VERSION "BodyCANhs"

NS_ :

BS_:

BU_: CCM CEM DDM ETC PAM PDM POT PSMD PSMP TRM VCM Y20CCMV526M1 Vector_XXX

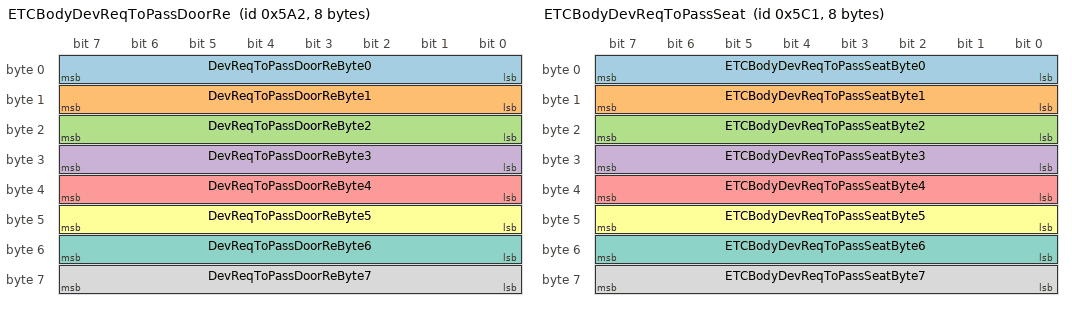
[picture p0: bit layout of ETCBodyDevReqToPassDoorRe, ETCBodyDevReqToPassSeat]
BO_ 1442 ETCBodyDevReqToPassDoorRe: 8 ETC
 SG_ DevReqToPassDoorReByte0 : 7|8@0+ (1,0) [0|255] ""  PDM
 SG_ DevReqToPassDoorReByte1 : 15|8@0+ (1,0) [0|255] ""  PDM
 SG_ DevReqToPassDoorReByte2 : 23|8@0+ (1,0) [0|255] ""  PDM
 SG_ DevReqToPassDoorReByte3 : 31|8@0+ (1,0) [0|255] ""  PDM
 SG_ DevReqToPassDoorReByte4 : 39|8@0+ (1,0) [0|255] ""  PDM
 SG_ DevReqToPassDoorReByte5 : 47|8@0+ (1,0) [0|255] ""  PDM
 SG_ DevReqToPassDoorReByte6 : 55|8@0+ (1,0) [0|255] ""  PDM
 SG_ DevReqToPassDoorReByte7 : 63|8@0+ (1,0) [0|255] ""  PDM

BO_ 1473 ETCBodyDevReqToPassSeat: 8 ETC
 SG_ ETCBodyDevReqToPassSeatByte0 : 7|8@0+ (1,0) [0|255] ""  PSMP
 SG_ ETCBodyDevReqToPassSeatByte1 : 15|8@0+ (1,0) [0|255] ""  PSMP
 SG_ ETCBodyDevReqToPassSeatByte2 : 23|8@0+ (1,0) [0|255] ""  PSMP
 SG_ ETCBodyDevReqToPassSeatByte3 : 31|8@0+ (1,0) [0|255] ""  PSMP
 SG_ ETCBodyDevReqToPassSeatByte4 : 39|8@0+ (1,0) [0|255] ""  PSMP
 SG_ ETCBodyDevReqToPassSeatByte5 : 47|8@0+ (1,0) [0|255] ""  PSMP
 SG_ ETCBodyDevReqToPassSeatByte6 : 55|8@0+ (1,0) [0|255] ""  PSMP
 SG_ ETCBodyDevReqToPassSeatByte7 : 63|8@0+ (1,0) [0|255] ""  PSMP

BO_ 1405 EtcMstCfgIDBodyFr01: 8 ETC
 SG_ IniValMstCfgIDBodyCAN : 7|16@0+ (1,0) [0|65535] ""  CEM

BO_ 1406 EtcSigCfgIDBodyFr01: 8 ETC
 SG_ IniValSigCfgIDBodyCAN : 7|16@0+ (1,0) [0|65535] ""  CCM,DDM,PDM,POT,PSMD,PSMP,TRM,VCM

BO_ 1520 ETCtoCCMXCPFr01: 8 ETC

BO_ 1521 ETCtoCEMXCPFr01: 8 ETC

BO_ 1522 ETCtoDDMXCPFr01: 8 ETC

BO_ 1523 ETCtoPDMXCPFr01: 8 ETC

BO_ 1467 ETCtoPOTXCPFr01: 8 ETC

BO_ 1465 ETCtoTRMXcpFr01: 8 ETC

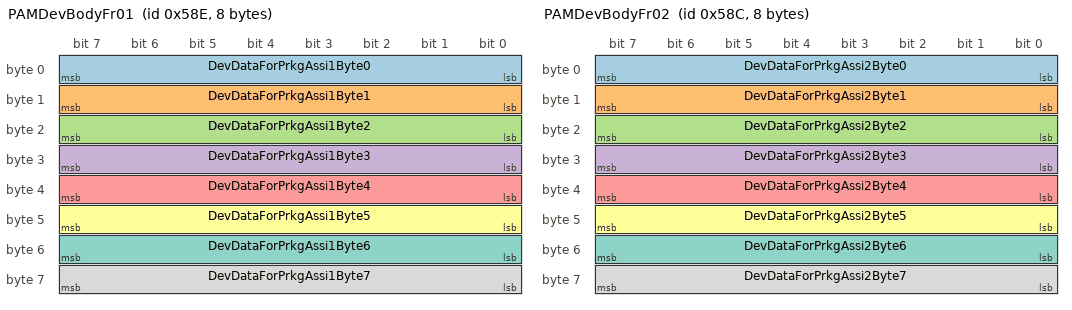
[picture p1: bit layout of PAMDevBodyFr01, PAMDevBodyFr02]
BO_ 1422 PAMDevBodyFr01: 8 PAM
 SG_ DevDataForPrkgAssi1Byte0 : 7|8@0+ (1,0) [0|255] ""  ETC
 SG_ DevDataForPrkgAssi1Byte1 : 15|8@0+ (1,0) [0|255] ""  ETC
 SG_ DevDataForPrkgAssi1Byte2 : 23|8@0+ (1,0) [0|255] ""  ETC
 SG_ DevDataForPrkgAssi1Byte3 : 31|8@0+ (1,0) [0|255] ""  ETC
 SG_ DevDataForPrkgAssi1Byte4 : 39|8@0+ (1,0) [0|255] ""  ETC
 SG_ DevDataForPrkgAssi1Byte5 : 47|8@0+ (1,0) [0|255] ""  ETC
 SG_ DevDataForPrkgAssi1Byte6 : 55|8@0+ (1,0) [0|255] ""  ETC
 SG_ DevDataForPrkgAssi1Byte7 : 63|8@0+ (1,0) [0|255] ""  ETC

BO_ 1420 PAMDevBodyFr02: 8 PAM
 SG_ DevDataForPrkgAssi2Byte0 : 7|8@0+ (1,0) [0|255] ""  ETC
 SG_ DevDataForPrkgAssi2Byte1 : 15|8@0+ (1,0) [0|255] ""  ETC
 SG_ DevDataForPrkgAssi2Byte2 : 23|8@0+ (1,0) [0|255] ""  ETC
 SG_ DevDataForPrkgAssi2Byte3 : 31|8@0+ (1,0) [0|255] ""  ETC
 SG_ DevDataForPrkgAssi2Byte4 : 39|8@0+ (1,0) [0|255] ""  ETC
 SG_ DevDataForPrkgAssi2Byte5 : 47|8@0+ (1,0) [0|255] ""  ETC
 SG_ DevDataForPrkgAssi2Byte6 : 55|8@0+ (1,0) [0|255] ""  ETC
 SG_ DevDataForPrkgAssi2Byte7 : 63|8@0+ (1,0) [0|255] ""  ETC

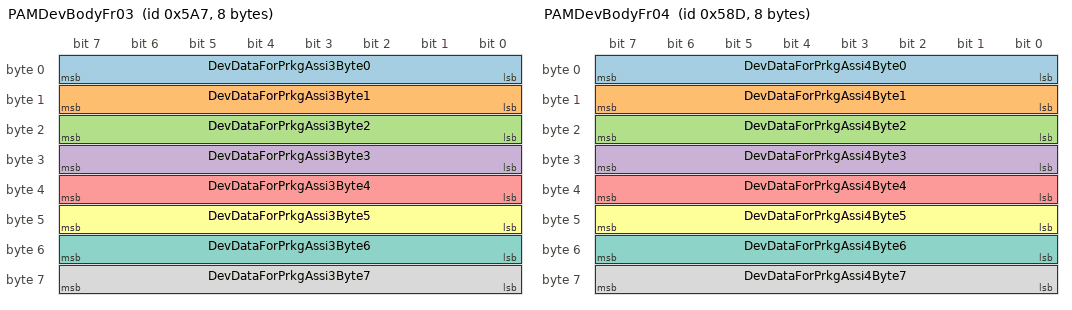
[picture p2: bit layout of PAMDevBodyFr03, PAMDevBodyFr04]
BO_ 1447 PAMDevBodyFr03: 8 PAM
 SG_ DevDataForPrkgAssi3Byte0 : 7|8@0+ (1,0) [0|255] ""  ETC
 SG_ DevDataForPrkgAssi3Byte1 : 15|8@0+ (1,0) [0|255] ""  ETC
 SG_ DevDataForPrkgAssi3Byte2 : 23|8@0+ (1,0) [0|255] ""  ETC
 SG_ DevDataForPrkgAssi3Byte3 : 31|8@0+ (1,0) [0|255] ""  ETC
 SG_ DevDataForPrkgAssi3Byte4 : 39|8@0+ (1,0) [0|255] ""  ETC
 SG_ DevDataForPrkgAssi3Byte5 : 47|8@0+ (1,0) [0|255] ""  ETC
 SG_ DevDataForPrkgAssi3Byte6 : 55|8@0+ (1,0) [0|255] ""  ETC
 SG_ DevDataForPrkgAssi3Byte7 : 63|8@0+ (1,0) [0|255] ""  ETC

BO_ 1421 PAMDevBodyFr04: 8 PAM
 SG_ DevDataForPrkgAssi4Byte0 : 7|8@0+ (1,0) [0|255] ""  ETC
 SG_ DevDataForPrkgAssi4Byte1 : 15|8@0+ (1,0) [0|255] ""  ETC
 SG_ DevDataForPrkgAssi4Byte2 : 23|8@0+ (1,0) [0|255] ""  ETC
 SG_ DevDataForPrkgAssi4Byte3 : 31|8@0+ (1,0) [0|255] ""  ETC
 SG_ DevDataForPrkgAssi4Byte4 : 39|8@0+ (1,0) [0|255] ""  ETC
 SG_ DevDataForPrkgAssi4Byte5 : 47|8@0+ (1,0) [0|255] ""  ETC
 SG_ DevDataForPrkgAssi4Byte6 : 55|8@0+ (1,0) [0|255] ""  ETC
 SG_ DevDataForPrkgAssi4Byte7 : 63|8@0+ (1,0) [0|255] ""  ETC

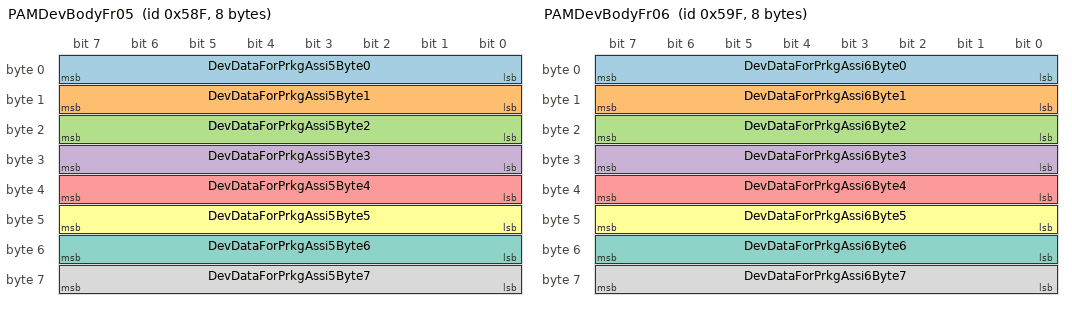
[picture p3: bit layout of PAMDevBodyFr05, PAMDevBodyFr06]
BO_ 1423 PAMDevBodyFr05: 8 PAM
 SG_ DevDataForPrkgAssi5Byte0 : 7|8@0+ (1,0) [0|255] ""  ETC
 SG_ DevDataForPrkgAssi5Byte1 : 15|8@0+ (1,0) [0|255] ""  ETC
 SG_ DevDataForPrkgAssi5Byte2 : 23|8@0+ (1,0) [0|255] ""  ETC
 SG_ DevDataForPrkgAssi5Byte3 : 31|8@0+ (1,0) [0|255] ""  ETC
 SG_ DevDataForPrkgAssi5Byte4 : 39|8@0+ (1,0) [0|255] ""  ETC
 SG_ DevDataForPrkgAssi5Byte5 : 47|8@0+ (1,0) [0|255] ""  ETC
 SG_ DevDataForPrkgAssi5Byte6 : 55|8@0+ (1,0) [0|255] ""  ETC
 SG_ DevDataForPrkgAssi5Byte7 : 63|8@0+ (1,0) [0|255] ""  ETC

BO_ 1439 PAMDevBodyFr06: 8 PAM
 SG_ DevDataForPrkgAssi6Byte0 : 7|8@0+ (1,0) [0|255] ""  ETC
 SG_ DevDataForPrkgAssi6Byte1 : 15|8@0+ (1,0) [0|255] ""  ETC
 SG_ DevDataForPrkgAssi6Byte2 : 23|8@0+ (1,0) [0|255] ""  ETC
 SG_ DevDataForPrkgAssi6Byte3 : 31|8@0+ (1,0) [0|255] ""  ETC
 SG_ DevDataForPrkgAssi6Byte4 : 39|8@0+ (1,0) [0|255] ""  ETC
 SG_ DevDataForPrkgAssi6Byte5 : 47|8@0+ (1,0) [0|255] ""  ETC
 SG_ DevDataForPrkgAssi6Byte6 : 55|8@0+ (1,0) [0|255] ""  ETC
 SG_ DevDataForPrkgAssi6Byte7 : 63|8@0+ (1,0) [0|255] ""  ETC

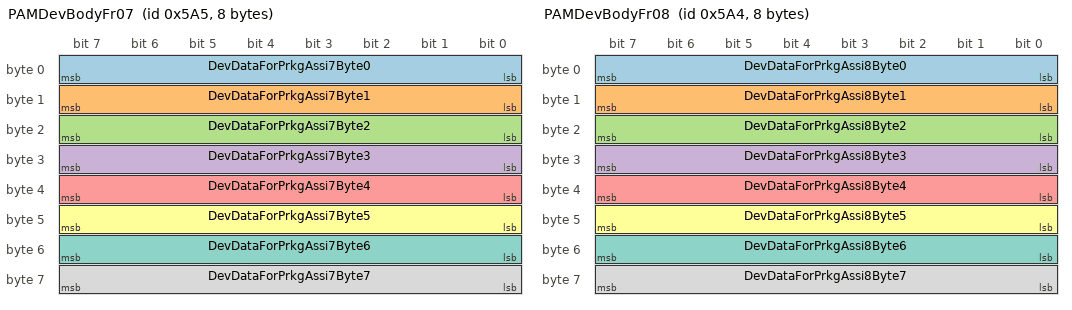
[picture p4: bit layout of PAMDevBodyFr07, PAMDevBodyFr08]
BO_ 1445 PAMDevBodyFr07: 8 PAM
 SG_ DevDataForPrkgAssi7Byte0 : 7|8@0+ (1,0) [0|255] ""  ETC
 SG_ DevDataForPrkgAssi7Byte1 : 15|8@0+ (1,0) [0|255] ""  ETC
 SG_ DevDataForPrkgAssi7Byte2 : 23|8@0+ (1,0) [0|255] ""  ETC
 SG_ DevDataForPrkgAssi7Byte3 : 31|8@0+ (1,0) [0|255] ""  ETC
 SG_ DevDataForPrkgAssi7Byte4 : 39|8@0+ (1,0) [0|255] ""  ETC
 SG_ DevDataForPrkgAssi7Byte5 : 47|8@0+ (1,0) [0|255] ""  ETC
 SG_ DevDataForPrkgAssi7Byte6 : 55|8@0+ (1,0) [0|255] ""  ETC
 SG_ DevDataForPrkgAssi7Byte7 : 63|8@0+ (1,0) [0|255] ""  ETC

BO_ 1444 PAMDevBodyFr08: 8 PAM
 SG_ DevDataForPrkgAssi8Byte0 : 7|8@0+ (1,0) [0|255] ""  ETC
 SG_ DevDataForPrkgAssi8Byte1 : 15|8@0+ (1,0) [0|255] ""  ETC
 SG_ DevDataForPrkgAssi8Byte2 : 23|8@0+ (1,0) [0|255] ""  ETC
 SG_ DevDataForPrkgAssi8Byte3 : 31|8@0+ (1,0) [0|255] ""  ETC
 SG_ DevDataForPrkgAssi8Byte4 : 39|8@0+ (1,0) [0|255] ""  ETC
 SG_ DevDataForPrkgAssi8Byte5 : 47|8@0+ (1,0) [0|255] ""  ETC
 SG_ DevDataForPrkgAssi8Byte6 : 55|8@0+ (1,0) [0|255] ""  ETC
 SG_ DevDataForPrkgAssi8Byte7 : 63|8@0+ (1,0) [0|255] ""  ETC

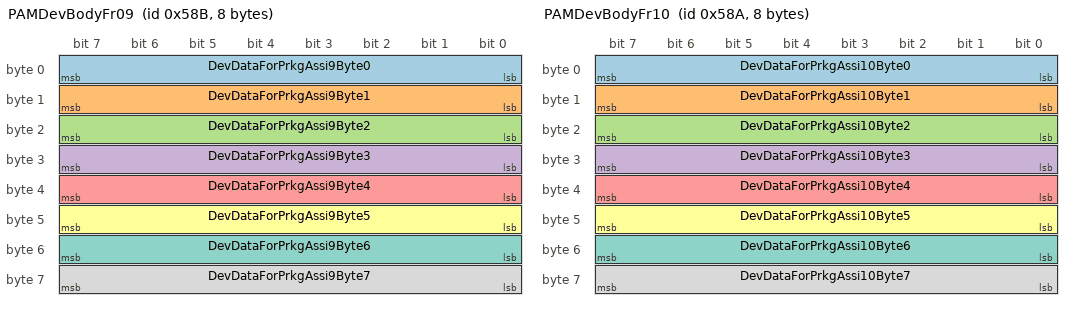
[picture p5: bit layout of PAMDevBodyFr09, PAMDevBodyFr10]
BO_ 1419 PAMDevBodyFr09: 8 PAM
 SG_ DevDataForPrkgAssi9Byte0 : 7|8@0+ (1,0) [0|255] ""  ETC
 SG_ DevDataForPrkgAssi9Byte1 : 15|8@0+ (1,0) [0|255] ""  ETC
 SG_ DevDataForPrkgAssi9Byte2 : 23|8@0+ (1,0) [0|255] ""  ETC
 SG_ DevDataForPrkgAssi9Byte3 : 31|8@0+ (1,0) [0|255] ""  ETC
 SG_ DevDataForPrkgAssi9Byte4 : 39|8@0+ (1,0) [0|255] ""  ETC
 SG_ DevDataForPrkgAssi9Byte5 : 47|8@0+ (1,0) [0|255] ""  ETC
 SG_ DevDataForPrkgAssi9Byte6 : 55|8@0+ (1,0) [0|255] ""  ETC
 SG_ DevDataForPrkgAssi9Byte7 : 63|8@0+ (1,0) [0|255] ""  ETC

BO_ 1418 PAMDevBodyFr10: 8 PAM
 SG_ DevDataForPrkgAssi10Byte0 : 7|8@0+ (1,0) [0|255] ""  ETC
 SG_ DevDataForPrkgAssi10Byte1 : 15|8@0+ (1,0) [0|255] ""  ETC
 SG_ DevDataForPrkgAssi10Byte2 : 23|8@0+ (1,0) [0|255] ""  ETC
 SG_ DevDataForPrkgAssi10Byte3 : 31|8@0+ (1,0) [0|255] ""  ETC
 SG_ DevDataForPrkgAssi10Byte4 : 39|8@0+ (1,0) [0|255] ""  ETC
 SG_ DevDataForPrkgAssi10Byte5 : 47|8@0+ (1,0) [0|255] ""  ETC
 SG_ DevDataForPrkgAssi10Byte6 : 55|8@0+ (1,0) [0|255] ""  ETC
 SG_ DevDataForPrkgAssi10Byte7 : 63|8@0+ (1,0) [0|255] ""  ETC

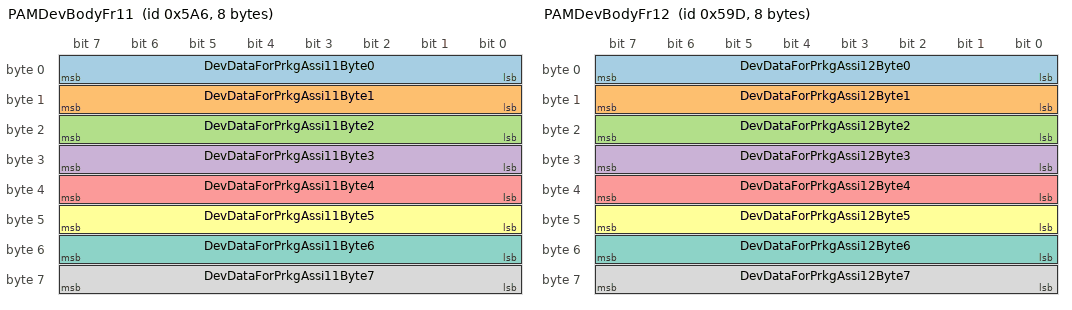
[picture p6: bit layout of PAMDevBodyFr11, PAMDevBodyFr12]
BO_ 1446 PAMDevBodyFr11: 8 PAM
 SG_ DevDataForPrkgAssi11Byte0 : 7|8@0+ (1,0) [0|255] ""  ETC
 SG_ DevDataForPrkgAssi11Byte1 : 15|8@0+ (1,0) [0|255] ""  ETC
 SG_ DevDataForPrkgAssi11Byte2 : 23|8@0+ (1,0) [0|255] ""  ETC
 SG_ DevDataForPrkgAssi11Byte3 : 31|8@0+ (1,0) [0|255] ""  ETC
 SG_ DevDataForPrkgAssi11Byte4 : 39|8@0+ (1,0) [0|255] ""  ETC
 SG_ DevDataForPrkgAssi11Byte5 : 47|8@0+ (1,0) [0|255] ""  ETC
 SG_ DevDataForPrkgAssi11Byte6 : 55|8@0+ (1,0) [0|255] ""  ETC
 SG_ DevDataForPrkgAssi11Byte7 : 63|8@0+ (1,0) [0|255] ""  ETC

BO_ 1437 PAMDevBodyFr12: 8 PAM
 SG_ DevDataForPrkgAssi12Byte0 : 7|8@0+ (1,0) [0|255] ""  ETC
 SG_ DevDataForPrkgAssi12Byte1 : 15|8@0+ (1,0) [0|255] ""  ETC
 SG_ DevDataForPrkgAssi12Byte2 : 23|8@0+ (1,0) [0|255] ""  ETC
 SG_ DevDataForPrkgAssi12Byte3 : 31|8@0+ (1,0) [0|255] ""  ETC
 SG_ DevDataForPrkgAssi12Byte4 : 39|8@0+ (1,0) [0|255] ""  ETC
 SG_ DevDataForPrkgAssi12Byte5 : 47|8@0+ (1,0) [0|255] ""  ETC
 SG_ DevDataForPrkgAssi12Byte6 : 55|8@0+ (1,0) [0|255] ""  ETC
 SG_ DevDataForPrkgAssi12Byte7 : 63|8@0+ (1,0) [0|255] ""  ETC

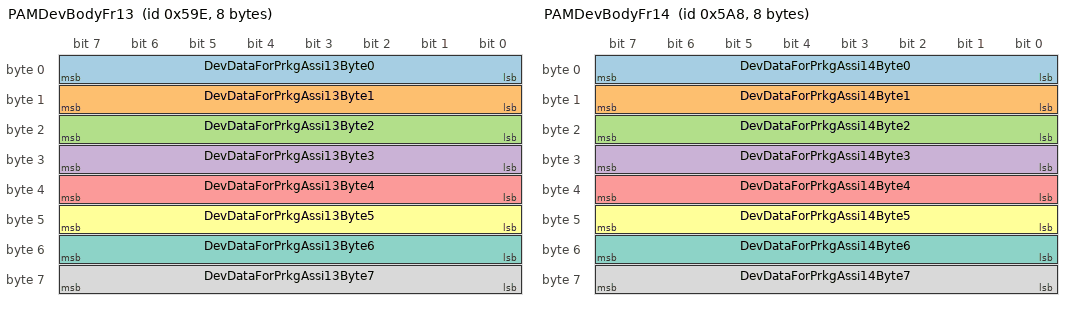
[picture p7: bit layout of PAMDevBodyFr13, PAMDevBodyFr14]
BO_ 1438 PAMDevBodyFr13: 8 PAM
 SG_ DevDataForPrkgAssi13Byte0 : 7|8@0+ (1,0) [0|255] ""  ETC
 SG_ DevDataForPrkgAssi13Byte1 : 15|8@0+ (1,0) [0|255] ""  ETC
 SG_ DevDataForPrkgAssi13Byte2 : 23|8@0+ (1,0) [0|255] ""  ETC
 SG_ DevDataForPrkgAssi13Byte3 : 31|8@0+ (1,0) [0|255] ""  ETC
 SG_ DevDataForPrkgAssi13Byte4 : 39|8@0+ (1,0) [0|255] ""  ETC
 SG_ DevDataForPrkgAssi13Byte5 : 47|8@0+ (1,0) [0|255] ""  ETC
 SG_ DevDataForPrkgAssi13Byte6 : 55|8@0+ (1,0) [0|255] ""  ETC
 SG_ DevDataForPrkgAssi13Byte7 : 63|8@0+ (1,0) [0|255] ""  ETC

BO_ 1448 PAMDevBodyFr14: 8 PAM
 SG_ DevDataForPrkgAssi14Byte0 : 7|8@0+ (1,0) [0|255] ""  ETC
 SG_ DevDataForPrkgAssi14Byte1 : 15|8@0+ (1,0) [0|255] ""  ETC
 SG_ DevDataForPrkgAssi14Byte2 : 23|8@0+ (1,0) [0|255] ""  ETC
 SG_ DevDataForPrkgAssi14Byte3 : 31|8@0+ (1,0) [0|255] ""  ETC
 SG_ DevDataForPrkgAssi14Byte4 : 39|8@0+ (1,0) [0|255] ""  ETC
 SG_ DevDataForPrkgAssi14Byte5 : 47|8@0+ (1,0) [0|255] ""  ETC
 SG_ DevDataForPrkgAssi14Byte6 : 55|8@0+ (1,0) [0|255] ""  ETC
 SG_ DevDataForPrkgAssi14Byte7 : 63|8@0+ (1,0) [0|255] ""  ETC

BO_ 16 PDMBodyFr01: 8 PDM
 SG_ ChdLockgProtnStsAtPassRe : 31|2@0+ (1,0) [0|3] ""  DDM
 SG_ ChdLockgProtnStsAtPassRe_UB : 38|1@0+ (1,0) [0|1] ""  DDM
 SG_ ChdWinProtnStsAtPassRe : 25|1@0+ (1,0) [0|1] ""  CEM,DDM
 SG_ ChdWinProtnStsAtPassRe_UB : 37|1@0+ (1,0) [0|1] ""  CEM,DDM
 SG_ CurtReReqFromRe : 54|1@0+ (1,0) [0|1] ""  CEM
 SG_ CurtReReqFromRe_UB : 55|1@0+ (1,0) [0|1] ""  CEM
 SG_ DoorPassLockReSts : 29|2@0+ (1,0) [0|3] ""  CEM,VCM
 SG_ DoorPassLockReSts_UB : 36|1@0+ (1,0) [0|1] ""  CEM,VCM
 SG_ DoorPassLockSts : 27|2@0+ (1,0) [0|3] ""  CEM,VCM
 SG_ DoorPassLockSts_UB : 35|1@0+ (1,0) [0|1] ""  CEM,VCM
 SG_ DoorPassSwtIntrLockgReq : 18|2@0+ (1,0) [0|3] ""  CEM
 SG_ DoorPassSwtIntrLockgReq_UB : 16|1@0+ (1,0) [0|1] ""  CEM
 SG_ DoorPassSwtLockgReSts : 24|1@0+ (1,0) [0|1] ""  CEM
 SG_ DoorPassSwtLockgReSts_UB : 34|1@0+ (1,0) [0|1] ""  CEM
 SG_ LcmaLedStsPassSide : 39|1@0+ (1,0) [0|1] ""  CEM
 SG_ LcmaLedStsPassSide_UB : 33|1@0+ (1,0) [0|1] ""  CEM
 SG_ MirrAtPassInMovmt : 1|1@0+ (1,0) [0|1] ""  CEM
 SG_ MirrAtPassInMovmt_UB : 0|1@0+ (1,0) [0|1] ""  CEM
 SG_ MirrDwnStsAtPass : 15|3@0+ (1,0) [0|7] ""  CEM,DDM
 SG_ MirrDwnStsAtPass_UB : 12|1@0+ (1,0) [0|1] ""  CEM,DDM
 SG_ MirrFoldStsAtPass : 11|3@0+ (1,0) [0|7] ""  CEM,DDM
 SG_ MirrFoldStsAtPass_UB : 8|1@0+ (1,0) [0|1] ""  CEM,DDM
 SG_ PassMemBtnPsd_UB : 19|1@0+ (1,0) [0|1] ""  CEM
 SG_ PassMemBtnPsdMemBtn1 : 23|1@0+ (1,0) [0|1] ""  CEM
 SG_ PassMemBtnPsdMemBtn2 : 22|1@0+ (1,0) [0|1] ""  CEM
 SG_ PassMemBtnPsdMemBtn3 : 21|1@0+ (1,0) [0|1] ""  CEM
 SG_ PassMemBtnPsdMemButM : 20|1@0+ (1,0) [0|1] ""  CEM
 SG_ SunRoofAndCurtReqFromRe_UB : 32|1@0+ (1,0) [0|1] ""  CEM
 SG_ SunRoofAndCurtReqFromReSunCurtRo : 53|3@0+ (1,0) [0|7] ""  CEM
 SG_ SunRoofAndCurtReqFromReSunRoofRe : 50|3@0+ (1,0) [0|7] ""  CEM
 SG_ WinAndCurtSwtReqReLeFromRe : 42|3@0+ (1,0) [0|7] ""  DDM
 SG_ WinAndCurtSwtReqReLeFromRe_UB : 43|1@0+ (1,0) [0|1] ""  DDM
 SG_ WinPosnStsRePass : 7|5@0+ (1,0) [0|31] ""  CCM,CEM
 SG_ WinPosnStsRePass_UB : 2|1@0+ (1,0) [0|1] ""  CCM,CEM

BO_ 352 PDMBodyFr02: 8 PDM
 SG_ AmbTQlyAtPassSide : 4|2@0+ (1,0) [0|3] ""  CEM
 SG_ AmbTRawAtPassSide_UB : 5|1@0+ (1,0) [0|1] ""  CEM
 SG_ AmbTURawAtRiSideForObd : 41|10@0+ (1,0) [0|1023] ""  CEM
 SG_ AmbTURawAtRiSideForObd_UB : 46|1@0+ (1,0) [0|1] ""  CEM
 SG_ AmbTValAtPassSide : 2|11@0+ (0.1,-70) [-70|134.7] "degC"  CEM
 SG_ CrashUnlckFailrStsAtPass : 7|2@0+ (1,0) [0|3] ""  CEM
 SG_ CrashUnlckFailrStsAtPass_UB : 24|1@0+ (1,0) [0|1] ""  CEM
 SG_ CrashUnlckFailrStsAtPassRe : 17|2@0+ (1,0) [0|3] ""  CEM
 SG_ CrashUnlckFailrStsAtPassRe_UB : 25|1@0+ (1,0) [0|1] ""  CEM
 SG_ DoorPassReStsOfSeatSwt_UB : 36|1@0+ (1,0) [0|1] ""  PSMP
 SG_ DoorPassReStsOfSeatSwtActrIncSts : 35|2@0+ (1,0) [0|3] ""  PSMP
 SG_ DoorPassReStsOfSeatSwtActrSldSts : 33|2@0+ (1,0) [0|3] ""  PSMP
 SG_ FltOfPuddleLiPass : 31|1@0+ (1,0) [0|1] ""  CEM
 SG_ FltOfPuddleLiPass_UB : 26|1@0+ (1,0) [0|1] ""  CEM
 SG_ LiPassFltIndcrTurn : 30|1@0+ (1,0) [0|1] ""  CEM
 SG_ LiPassFltIndcrTurn_UB : 27|1@0+ (1,0) [0|1] ""  CEM
 SG_ MirrDefrstAtPassSts : 18|1@0+ (1,0) [0|1] ""  CEM
 SG_ MirrDefrstAtPassSts_UB : 28|1@0+ (1,0) [0|1] ""  CEM
 SG_ WinPosnStsPass : 23|5@0+ (1,0) [0|31] ""  CCM,CEM,VCM
 SG_ WinPosnStsPass_UB : 29|1@0+ (1,0) [0|1] ""  CCM,CEM,VCM

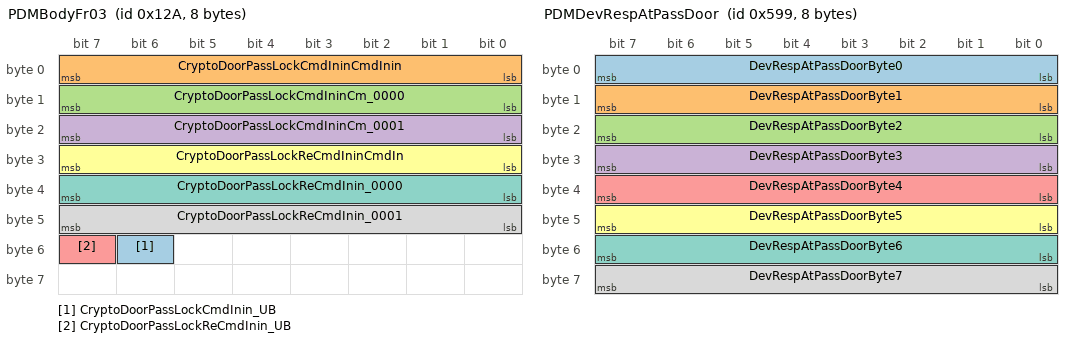
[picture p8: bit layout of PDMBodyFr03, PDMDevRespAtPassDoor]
BO_ 298 PDMBodyFr03: 8 PDM
 SG_ CryptoDoorPassLockCmdInin_UB : 54|1@0+ (1,0) [0|1] ""  CEM
 SG_ CryptoDoorPassLockCmdIninCmdInin : 7|8@0+ (1,0) [0|255] ""  CEM
 SG_ CryptoDoorPassLockCmdIninCm_0000 : 15|8@0+ (1,0) [0|255] ""  CEM
 SG_ CryptoDoorPassLockCmdIninCm_0001 : 23|8@0+ (1,0) [0|255] ""  CEM
 SG_ CryptoDoorPassLockReCmdInin_UB : 55|1@0+ (1,0) [0|1] ""  CEM
 SG_ CryptoDoorPassLockReCmdIninCmdIn : 31|8@0+ (1,0) [0|255] ""  CEM
 SG_ CryptoDoorPassLockReCmdInin_0000 : 39|8@0+ (1,0) [0|255] ""  CEM
 SG_ CryptoDoorPassLockReCmdInin_0001 : 47|8@0+ (1,0) [0|255] ""  CEM

BO_ 1284 PdmBodyNMFr: 8 PDM
 SG_ PNC23_Spare1_PDM : 39|1@0+ (1,0) [0|0] ""  ETC
 SG_ PNC22_Spare2_PDM : 38|1@0+ (1,0) [0|0] ""  ETC
 SG_ PNC21_Spare3_PDM : 37|1@0+ (1,0) [0|0] ""  ETC
 SG_ PNC20_Spare4_PDM : 36|1@0+ (1,0) [0|0] ""  ETC
 SG_ PNC19_Spare5_PDM : 35|1@0+ (1,0) [0|0] ""  ETC
 SG_ PNC18_Spare6_PDM : 34|1@0+ (1,0) [0|0] ""  ETC
 SG_ PNC17_Spare7_PDM : 33|1@0+ (1,0) [0|0] ""  ETC
 SG_ PNC16_Diesel_PDM : 32|1@0+ (1,0) [0|0] ""  ETC
 SG_ PNC15_DriverInfoPoll_PDM : 31|1@0+ (1,0) [0|0] ""  ETC
 SG_ PNC14_GSD_PDM : 30|1@0+ (1,0) [0|0] ""  ETC
 SG_ PNC13_Global_PDM : 29|1@0+ (1,0) [0|0] ""  ETC
 SG_ PNC12_TrailerCaravan_PDM : 28|1@0+ (1,0) [0|0] ""  ETC
 SG_ PNC11_Driving_PDM : 27|1@0+ (1,0) [0|0] ""  ETC
 SG_ PNC10_PreClimatization_PDM : 26|1@0+ (1,0) [0|0] ""  ETC
 SG_ PNC9_Charging_PDM : 25|1@0+ (1,0) [0|0] ""  ETC
 SG_ PNC8_Start_PDM : 24|1@0+ (1,0) [0|0] ""  ETC
 SG_ PNC7_Entrance_PDM : 23|1@0+ (1,0) [0|0] ""  ETC
 SG_ PNC6_InfotainmentHMI_PDM : 22|1@0+ (1,0) [0|0] ""  ETC
 SG_ PNC5_Body_PDM : 21|1@0+ (1,0) [0|0] ""  ETC
 SG_ PNC4_Visibility_PDM : 20|1@0+ (1,0) [0|0] ""  ETC
 SG_ PNC3_WarningSounds_PDM : 19|1@0+ (1,0) [0|0] ""  ETC
 SG_ PNC2_Hazard_PDM : 18|1@0+ (1,0) [0|0] ""  ETC
 SG_ PNC1_Locking_PDM : 17|1@0+ (1,0) [0|0] ""  ETC
 SG_ PNC0_DriverInfo_PDM : 16|1@0+ (1,0) [0|0] ""  ETC
 SG_ NM_AW_PDM : 12|1@0+ (1,0) [0|0] ""  ETC
 SG_ NM_CS_PDM : 11|1@0+ (1,0) [0|0] ""  ETC
 SG_ NM_RMR_PDM : 8|1@0+ (1,0) [0|0] ""  ETC
 SG_ NM_PNI_PDM : 14|1@0+ (1,0) [0|0] ""  ETC
 SG_ NM_NodeID_PDM : 7|8@0+ (1,0) [0|0] ""  ETC

BO_ 1433 PDMDevRespAtPassDoor: 8 PDM
 SG_ DevRespAtPassDoorByte0 : 7|8@0+ (1,0) [0|255] ""  ETC
 SG_ DevRespAtPassDoorByte1 : 15|8@0+ (1,0) [0|255] ""  ETC
 SG_ DevRespAtPassDoorByte2 : 23|8@0+ (1,0) [0|255] ""  ETC
 SG_ DevRespAtPassDoorByte3 : 31|8@0+ (1,0) [0|255] ""  ETC
 SG_ DevRespAtPassDoorByte4 : 39|8@0+ (1,0) [0|255] ""  ETC
 SG_ DevRespAtPassDoorByte5 : 47|8@0+ (1,0) [0|255] ""  ETC
 SG_ DevRespAtPassDoorByte6 : 55|8@0+ (1,0) [0|255] ""  ETC
 SG_ DevRespAtPassDoorByte7 : 63|8@0+ (1,0) [0|255] ""  ETC

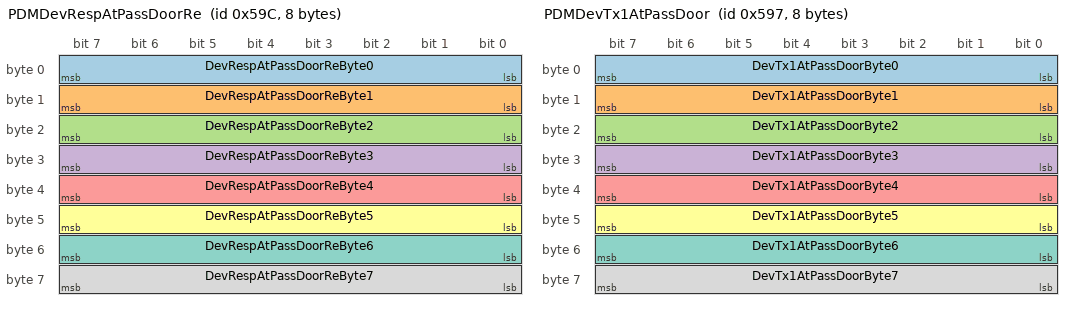
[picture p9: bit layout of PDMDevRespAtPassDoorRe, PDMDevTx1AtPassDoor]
BO_ 1436 PDMDevRespAtPassDoorRe: 8 PDM
 SG_ DevRespAtPassDoorReByte0 : 7|8@0+ (1,0) [0|255] ""  ETC
 SG_ DevRespAtPassDoorReByte1 : 15|8@0+ (1,0) [0|255] ""  ETC
 SG_ DevRespAtPassDoorReByte2 : 23|8@0+ (1,0) [0|255] ""  ETC
 SG_ DevRespAtPassDoorReByte3 : 31|8@0+ (1,0) [0|255] ""  ETC
 SG_ DevRespAtPassDoorReByte4 : 39|8@0+ (1,0) [0|255] ""  ETC
 SG_ DevRespAtPassDoorReByte5 : 47|8@0+ (1,0) [0|255] ""  ETC
 SG_ DevRespAtPassDoorReByte6 : 55|8@0+ (1,0) [0|255] ""  ETC
 SG_ DevRespAtPassDoorReByte7 : 63|8@0+ (1,0) [0|255] ""  ETC

BO_ 1431 PDMDevTx1AtPassDoor: 8 PDM
 SG_ DevTx1AtPassDoorByte0 : 7|8@0+ (1,0) [0|255] ""  ETC
 SG_ DevTx1AtPassDoorByte1 : 15|8@0+ (1,0) [0|255] ""  ETC
 SG_ DevTx1AtPassDoorByte2 : 23|8@0+ (1,0) [0|255] ""  ETC
 SG_ DevTx1AtPassDoorByte3 : 31|8@0+ (1,0) [0|255] ""  ETC
 SG_ DevTx1AtPassDoorByte4 : 39|8@0+ (1,0) [0|255] ""  ETC
 SG_ DevTx1AtPassDoorByte5 : 47|8@0+ (1,0) [0|255] ""  ETC
 SG_ DevTx1AtPassDoorByte6 : 55|8@0+ (1,0) [0|255] ""  ETC
 SG_ DevTx1AtPassDoorByte7 : 63|8@0+ (1,0) [0|255] ""  ETC

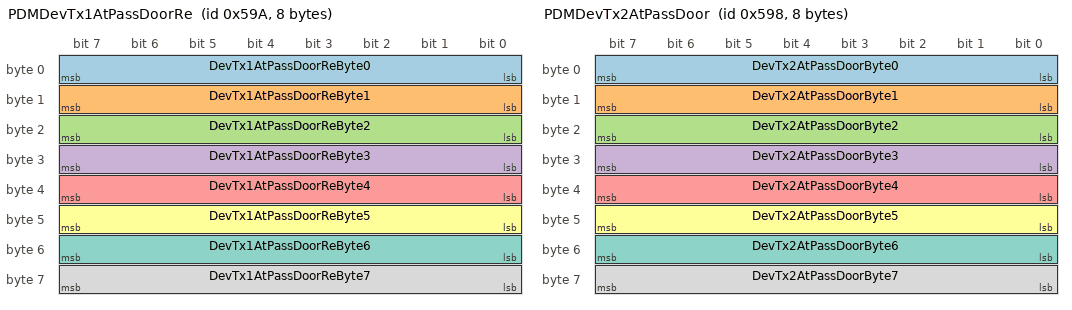
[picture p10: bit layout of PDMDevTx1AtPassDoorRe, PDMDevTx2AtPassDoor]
BO_ 1434 PDMDevTx1AtPassDoorRe: 8 PDM
 SG_ DevTx1AtPassDoorReByte0 : 7|8@0+ (1,0) [0|255] ""  ETC
 SG_ DevTx1AtPassDoorReByte1 : 15|8@0+ (1,0) [0|255] ""  ETC
 SG_ DevTx1AtPassDoorReByte2 : 23|8@0+ (1,0) [0|255] ""  ETC
 SG_ DevTx1AtPassDoorReByte3 : 31|8@0+ (1,0) [0|255] ""  ETC
 SG_ DevTx1AtPassDoorReByte4 : 39|8@0+ (1,0) [0|255] ""  ETC
 SG_ DevTx1AtPassDoorReByte5 : 47|8@0+ (1,0) [0|255] ""  ETC
 SG_ DevTx1AtPassDoorReByte6 : 55|8@0+ (1,0) [0|255] ""  ETC
 SG_ DevTx1AtPassDoorReByte7 : 63|8@0+ (1,0) [0|255] ""  ETC

BO_ 1432 PDMDevTx2AtPassDoor: 8 PDM
 SG_ DevTx2AtPassDoorByte0 : 7|8@0+ (1,0) [0|255] ""  ETC
 SG_ DevTx2AtPassDoorByte1 : 15|8@0+ (1,0) [0|255] ""  ETC
 SG_ DevTx2AtPassDoorByte2 : 23|8@0+ (1,0) [0|255] ""  ETC
 SG_ DevTx2AtPassDoorByte3 : 31|8@0+ (1,0) [0|255] ""  ETC
 SG_ DevTx2AtPassDoorByte4 : 39|8@0+ (1,0) [0|255] ""  ETC
 SG_ DevTx2AtPassDoorByte5 : 47|8@0+ (1,0) [0|255] ""  ETC
 SG_ DevTx2AtPassDoorByte6 : 55|8@0+ (1,0) [0|255] ""  ETC
 SG_ DevTx2AtPassDoorByte7 : 63|8@0+ (1,0) [0|255] ""  ETC

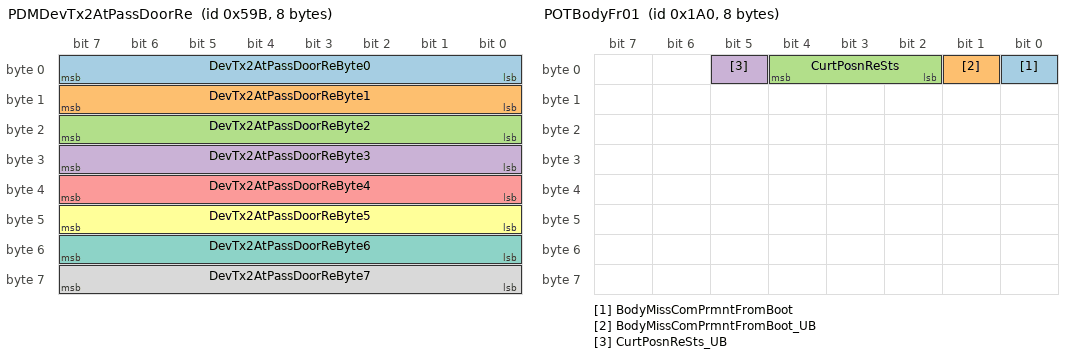
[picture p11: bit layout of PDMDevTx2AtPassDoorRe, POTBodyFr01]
BO_ 1435 PDMDevTx2AtPassDoorRe: 8 PDM
 SG_ DevTx2AtPassDoorReByte0 : 7|8@0+ (1,0) [0|255] ""  ETC
 SG_ DevTx2AtPassDoorReByte1 : 15|8@0+ (1,0) [0|255] ""  ETC
 SG_ DevTx2AtPassDoorReByte2 : 23|8@0+ (1,0) [0|255] ""  ETC
 SG_ DevTx2AtPassDoorReByte3 : 31|8@0+ (1,0) [0|255] ""  ETC
 SG_ DevTx2AtPassDoorReByte4 : 39|8@0+ (1,0) [0|255] ""  ETC
 SG_ DevTx2AtPassDoorReByte5 : 47|8@0+ (1,0) [0|255] ""  ETC
 SG_ DevTx2AtPassDoorReByte6 : 55|8@0+ (1,0) [0|255] ""  ETC
 SG_ DevTx2AtPassDoorReByte7 : 63|8@0+ (1,0) [0|255] ""  ETC

BO_ 1555 PdmToCemBodyDiagResFrame: 8 PDM

BO_ 1424 PDMtoETCXCPFr01: 8 PDM

BO_ 416 POTBodyFr01: 8 POT
 SG_ BodyMissComPrmntFromBoot : 0|1@0+ (1,0) [0|1] ""  CEM
 SG_ BodyMissComPrmntFromBoot_UB : 1|1@0+ (1,0) [0|1] ""  CEM
 SG_ CurtPosnReSts : 4|3@0+ (1,0) [0|7] ""  CEM
 SG_ CurtPosnReSts_UB : 5|1@0+ (1,0) [0|1] ""  CEM

BO_ 149 POTBodyFr02: 8 POT
 SG_ TrOpenerSts : 3|4@0+ (1,0) [0|15] ""  CEM
 SG_ TrOpenerSts_UB : 4|1@0+ (1,0) [0|1] ""  CEM

BO_ 1287 PotBodyNMFr: 8 POT
 SG_ PNC23_Spare1_POT : 39|1@0+ (1,0) [0|0] ""  ETC
 SG_ PNC22_Spare2_POT : 38|1@0+ (1,0) [0|0] ""  ETC
 SG_ PNC21_Spare3_POT : 37|1@0+ (1,0) [0|0] ""  ETC
 SG_ PNC20_Spare4_POT : 36|1@0+ (1,0) [0|0] ""  ETC
 SG_ PNC19_Spare5_POT : 35|1@0+ (1,0) [0|0] ""  ETC
 SG_ PNC18_Spare6_POT : 34|1@0+ (1,0) [0|0] ""  ETC
 SG_ PNC17_Spare7_POT : 33|1@0+ (1,0) [0|0] ""  ETC
 SG_ PNC16_Diesel_POT : 32|1@0+ (1,0) [0|0] ""  ETC
 SG_ PNC15_DriverInfoPoll_POT : 31|1@0+ (1,0) [0|0] ""  ETC
 SG_ PNC14_GSD_POT : 30|1@0+ (1,0) [0|0] ""  ETC
 SG_ PNC13_Global_POT : 29|1@0+ (1,0) [0|0] ""  ETC
 SG_ PNC12_TrailerCaravan_POT : 28|1@0+ (1,0) [0|0] ""  ETC
 SG_ PNC11_Driving_POT : 27|1@0+ (1,0) [0|0] ""  ETC
 SG_ PNC10_PreClimatization_POT : 26|1@0+ (1,0) [0|0] ""  ETC
 SG_ PNC9_Charging_POT : 25|1@0+ (1,0) [0|0] ""  ETC
 SG_ PNC8_Start_POT : 24|1@0+ (1,0) [0|0] ""  ETC
 SG_ PNC7_Entrance_POT : 23|1@0+ (1,0) [0|0] ""  ETC
 SG_ PNC6_InfotainmentHMI_POT : 22|1@0+ (1,0) [0|0] ""  ETC
 SG_ PNC5_Body_POT : 21|1@0+ (1,0) [0|0] ""  ETC
 SG_ PNC4_Visibility_POT : 20|1@0+ (1,0) [0|0] ""  ETC
 SG_ PNC3_WarningSounds_POT : 19|1@0+ (1,0) [0|0] ""  ETC
 SG_ PNC2_Hazard_POT : 18|1@0+ (1,0) [0|0] ""  ETC
 SG_ PNC1_Locking_POT : 17|1@0+ (1,0) [0|0] ""  ETC
 SG_ PNC0_DriverInfo_POT : 16|1@0+ (1,0) [0|0] ""  ETC
 SG_ NM_AW_POT : 12|1@0+ (1,0) [0|0] ""  ETC
 SG_ NM_CS_POT : 11|1@0+ (1,0) [0|0] ""  ETC
 SG_ NM_RMR_POT : 8|1@0+ (1,0) [0|0] ""  ETC
 SG_ NM_PNI_POT : 14|1@0+ (1,0) [0|0] ""  ETC
 SG_ NM_NodeID_POT : 7|8@0+ (1,0) [0|0] ""  ETC

BO_ 1557 PotToCemBodyDiagResFrame: 8 POT

BO_ 1466 POTtoETCXCPFr01: 8 POT

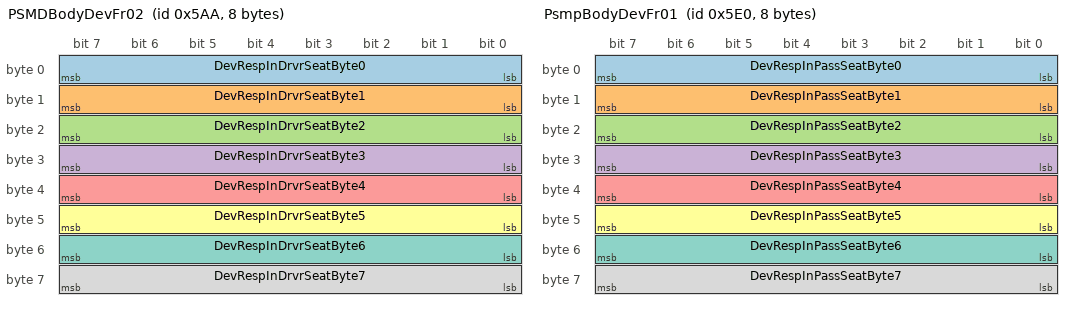
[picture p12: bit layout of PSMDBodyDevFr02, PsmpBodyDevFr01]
BO_ 1450 PSMDBodyDevFr02: 8 PSMD
 SG_ DevRespInDrvrSeatByte0 : 7|8@0+ (1,0) [0|255] ""  ETC
 SG_ DevRespInDrvrSeatByte1 : 15|8@0+ (1,0) [0|255] ""  ETC
 SG_ DevRespInDrvrSeatByte2 : 23|8@0+ (1,0) [0|255] ""  ETC
 SG_ DevRespInDrvrSeatByte3 : 31|8@0+ (1,0) [0|255] ""  ETC
 SG_ DevRespInDrvrSeatByte4 : 39|8@0+ (1,0) [0|255] ""  ETC
 SG_ DevRespInDrvrSeatByte5 : 47|8@0+ (1,0) [0|255] ""  ETC
 SG_ DevRespInDrvrSeatByte6 : 55|8@0+ (1,0) [0|255] ""  ETC
 SG_ DevRespInDrvrSeatByte7 : 63|8@0+ (1,0) [0|255] ""  ETC

BO_ 144 PSMDBodyFr01: 8 PSMD
 SG_ DrvrCtrlOfPassSeatFrntSts : 4|2@0+ (1,0) [0|3] ""  CEM,PSMP
 SG_ DrvrCtrlOfPassSeatFrntSts_UB : 39|1@0+ (1,0) [0|1] ""  CEM,PSMP
 SG_ DrvrMassgRunng : 2|1@0+ (1,0) [0|1] ""  CEM
 SG_ DrvrMassgRunng_UB : 38|1@0+ (1,0) [0|1] ""  CEM
 SG_ DrvrSeatActvSpplFct : 7|3@0+ (1,0) [0|7] ""  CEM
 SG_ DrvrSeatActvSpplFct_UB : 37|1@0+ (1,0) [0|1] ""  CEM
 SG_ DrvrSeatBtnPsd : 1|1@0+ (1,0) [0|1] ""  CEM
 SG_ DrvrSeatBtnPsd_UB : 36|1@0+ (1,0) [0|1] ""  CEM
 SG_ DrvrSeatInAutMovmt : 0|1@0+ (1,0) [0|1] ""  CEM
 SG_ DrvrSeatInAutMovmt_UB : 35|1@0+ (1,0) [0|1] ""  CEM
 SG_ DrvrSeatMassgFct_UB : 34|1@0+ (1,0) [0|1] ""  CEM
 SG_ DrvrSeatMassgFctMassgInten : 11|2@0+ (1,0) [0|3] ""  CEM
 SG_ DrvrSeatMassgFctMassgProg : 15|3@0+ (1,0) [0|7] ""  CEM
 SG_ DrvrSeatMassgFctMassgSpdLvl : 9|2@0+ (1,0) [0|3] ""  CEM
 SG_ DrvrSeatMassgFctOnOff : 12|1@0+ (1,0) [0|1] ""  CEM
 SG_ DrvrSeatSwtAdjmtOfSpplFctHozlSts : 23|2@0+ (1,0) [0|3] ""  CEM,PSMP
 SG_ DrvrSeatSwtAdjmtOfSpplFctVertSts : 21|2@0+ (1,0) [0|3] ""  CEM,PSMP
 SG_ DrvrSeatSwtHeiFrntSts : 19|2@0+ (1,0) [0|3] ""  CEM,PSMP
 SG_ DrvrSeatSwtHeiSts : 17|2@0+ (1,0) [0|3] ""  CEM,PSMP
 SG_ DrvrSeatSwtInclSts : 31|2@0+ (1,0) [0|3] ""  CEM,PSMP
 SG_ DrvrSeatSwtSelnOfSpplFctSts : 29|2@0+ (1,0) [0|3] ""  CEM,PSMP
 SG_ DrvrSeatSwtSldSts : 27|2@0+ (1,0) [0|3] ""  CEM,PSMP
 SG_ DrvrSeatSwtSts_UB : 24|1@0+ (1,0) [0|1] ""  CEM,PSMP
 SG_ SeatBackUnlckdThrd_UB : 43|1@0+ (1,0) [0|1] ""  CEM
 SG_ SeatBackUnlckdThrdLe : 47|1@0+ (1,0) [0|1] ""  CEM
 SG_ SeatBackUnlckdThrdRi : 46|1@0+ (1,0) [0|1] ""  CEM
 SG_ SeatBlkdLe : 45|1@0+ (1,0) [0|1] ""  CEM
 SG_ SeatBlkdRi : 44|1@0+ (1,0) [0|1] ""  CEM
 SG_ SeatBlkdThrd_UB : 42|1@0+ (1,0) [0|1] ""  CEM
 SG_ SeatFoldFctStsThrdGlb : 25|1@0+ (1,0) [0|1] ""  CEM
 SG_ SeatFoldFctStsThrdGlb_UB : 33|1@0+ (1,0) [0|1] ""  CEM

BO_ 1285 PsmdBodyNMFr: 8 PSMD
 SG_ PNC23_Spare1_PSMD : 39|1@0+ (1,0) [0|0] ""  ETC
 SG_ PNC22_Spare2_PSMD : 38|1@0+ (1,0) [0|0] ""  ETC
 SG_ PNC21_Spare3_PSMD : 37|1@0+ (1,0) [0|0] ""  ETC
 SG_ PNC20_Spare4_PSMD : 36|1@0+ (1,0) [0|0] ""  ETC
 SG_ PNC19_Spare5_PSMD : 35|1@0+ (1,0) [0|0] ""  ETC
 SG_ PNC18_Spare6_PSMD : 34|1@0+ (1,0) [0|0] ""  ETC
 SG_ PNC17_Spare7_PSMD : 33|1@0+ (1,0) [0|0] ""  ETC
 SG_ PNC16_Diesel_PSMD : 32|1@0+ (1,0) [0|0] ""  ETC
 SG_ PNC15_DriverInfoPoll_PSMD : 31|1@0+ (1,0) [0|0] ""  ETC
 SG_ PNC14_GSD_PSMD : 30|1@0+ (1,0) [0|0] ""  ETC
 SG_ PNC13_Global_PSMD : 29|1@0+ (1,0) [0|0] ""  ETC
 SG_ PNC12_TrailerCaravan_PSMD : 28|1@0+ (1,0) [0|0] ""  ETC
 SG_ PNC11_Driving_PSMD : 27|1@0+ (1,0) [0|0] ""  ETC
 SG_ PNC10_PreClimatization_PSMD : 26|1@0+ (1,0) [0|0] ""  ETC
 SG_ PNC9_Charging_PSMD : 25|1@0+ (1,0) [0|0] ""  ETC
 SG_ PNC8_Start_PSMD : 24|1@0+ (1,0) [0|0] ""  ETC
 SG_ PNC7_Entrance_PSMD : 23|1@0+ (1,0) [0|0] ""  ETC
 SG_ PNC6_InfotainmentHMI_PSMD : 22|1@0+ (1,0) [0|0] ""  ETC
 SG_ PNC5_Body_PSMD : 21|1@0+ (1,0) [0|0] ""  ETC
 SG_ PNC4_Visibility_PSMD : 20|1@0+ (1,0) [0|0] ""  ETC
 SG_ PNC3_WarningSounds_PSMD : 19|1@0+ (1,0) [0|0] ""  ETC
 SG_ PNC2_Hazard_PSMD : 18|1@0+ (1,0) [0|0] ""  ETC
 SG_ PNC1_Locking_PSMD : 17|1@0+ (1,0) [0|0] ""  ETC
 SG_ PNC0_DriverInfo_PSMD : 16|1@0+ (1,0) [0|0] ""  ETC
 SG_ NM_AW_PSMD : 12|1@0+ (1,0) [0|0] ""  ETC
 SG_ NM_CS_PSMD : 11|1@0+ (1,0) [0|0] ""  ETC
 SG_ NM_RMR_PSMD : 8|1@0+ (1,0) [0|0] ""  ETC
 SG_ NM_PNI_PSMD : 14|1@0+ (1,0) [0|0] ""  ETC
 SG_ NM_NodeID_PSMD : 7|8@0+ (1,0) [0|0] ""  ETC

BO_ 1556 PsmdToCemBodyDiagResFrame: 8 PSMD

BO_ 1504 PsmpBodyDevFr01: 8 PSMP
 SG_ DevRespInPassSeatByte0 : 7|8@0+ (1,0) [0|255] ""  ETC
 SG_ DevRespInPassSeatByte1 : 15|8@0+ (1,0) [0|255] ""  ETC
 SG_ DevRespInPassSeatByte2 : 23|8@0+ (1,0) [0|255] ""  ETC
 SG_ DevRespInPassSeatByte3 : 31|8@0+ (1,0) [0|255] ""  ETC
 SG_ DevRespInPassSeatByte4 : 39|8@0+ (1,0) [0|255] ""  ETC
 SG_ DevRespInPassSeatByte5 : 47|8@0+ (1,0) [0|255] ""  ETC
 SG_ DevRespInPassSeatByte6 : 55|8@0+ (1,0) [0|255] ""  ETC
 SG_ DevRespInPassSeatByte7 : 63|8@0+ (1,0) [0|255] ""  ETC

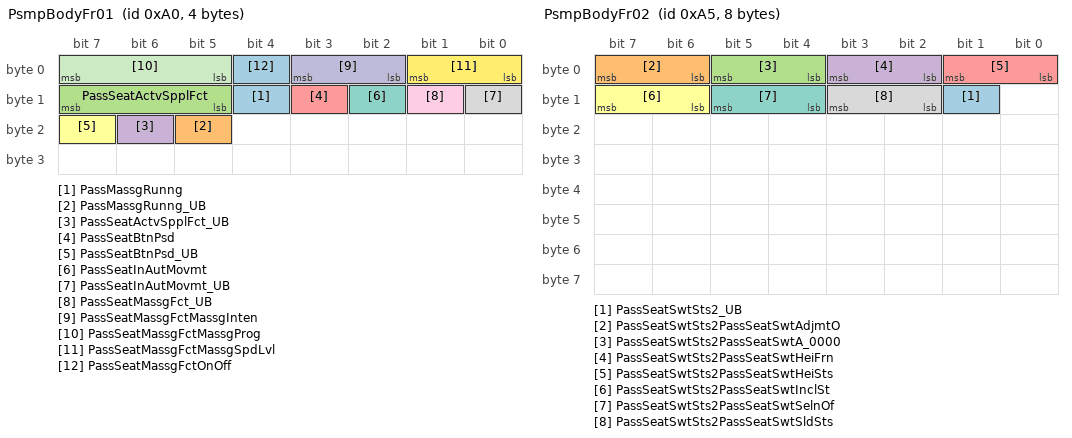
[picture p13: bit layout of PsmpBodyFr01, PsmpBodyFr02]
BO_ 160 PsmpBodyFr01: 4 PSMP
 SG_ PassMassgRunng : 12|1@0+ (1,0) [0|1] ""  CEM
 SG_ PassMassgRunng_UB : 21|1@0+ (1,0) [0|1] ""  CEM
 SG_ PassSeatActvSpplFct : 15|3@0+ (1,0) [0|7] ""  CEM
 SG_ PassSeatActvSpplFct_UB : 22|1@0+ (1,0) [0|1] ""  CEM
 SG_ PassSeatBtnPsd : 11|1@0+ (1,0) [0|1] ""  CEM
 SG_ PassSeatBtnPsd_UB : 23|1@0+ (1,0) [0|1] ""  CEM
 SG_ PassSeatInAutMovmt : 10|1@0+ (1,0) [0|1] ""  CEM
 SG_ PassSeatInAutMovmt_UB : 8|1@0+ (1,0) [0|1] ""  CEM
 SG_ PassSeatMassgFct_UB : 9|1@0+ (1,0) [0|1] ""  CEM
 SG_ PassSeatMassgFctMassgInten : 3|2@0+ (1,0) [0|3] ""  CEM
 SG_ PassSeatMassgFctMassgProg : 7|3@0+ (1,0) [0|7] ""  CEM
 SG_ PassSeatMassgFctMassgSpdLvl : 1|2@0+ (1,0) [0|3] ""  CEM
 SG_ PassSeatMassgFctOnOff : 4|1@0+ (1,0) [0|1] ""  CEM

BO_ 165 PsmpBodyFr02: 8 PSMP
 SG_ PassSeatSwtSts2_UB : 9|1@0+ (1,0) [0|1] ""  CEM
 SG_ PassSeatSwtSts2PassSeatSwtAdjmtO : 7|2@0+ (1,0) [0|3] ""  CEM
 SG_ PassSeatSwtSts2PassSeatSwtA_0000 : 5|2@0+ (1,0) [0|3] ""  CEM
 SG_ PassSeatSwtSts2PassSeatSwtHeiFrn : 3|2@0+ (1,0) [0|3] ""  CEM
 SG_ PassSeatSwtSts2PassSeatSwtHeiSts : 1|2@0+ (1,0) [0|3] ""  CEM
 SG_ PassSeatSwtSts2PassSeatSwtInclSt : 15|2@0+ (1,0) [0|3] ""  CEM
 SG_ PassSeatSwtSts2PassSeatSwtSelnOf : 13|2@0+ (1,0) [0|3] ""  CEM
 SG_ PassSeatSwtSts2PassSeatSwtSldSts : 11|2@0+ (1,0) [0|3] ""  CEM

BO_ 1286 PsmpBodyNMFr: 8 PSMP
 SG_ PNC23_Spare1_PSMP : 39|1@0+ (1,0) [0|0] ""  ETC
 SG_ PNC22_Spare2_PSMP : 38|1@0+ (1,0) [0|0] ""  ETC
 SG_ PNC21_Spare3_PSMP : 37|1@0+ (1,0) [0|0] ""  ETC
 SG_ PNC20_Spare4_PSMP : 36|1@0+ (1,0) [0|0] ""  ETC
 SG_ PNC19_Spare5_PSMP : 35|1@0+ (1,0) [0|0] ""  ETC
 SG_ PNC18_Spare6_PSMP : 34|1@0+ (1,0) [0|0] ""  ETC
 SG_ PNC17_Spare7_PSMP : 33|1@0+ (1,0) [0|0] ""  ETC
 SG_ PNC16_Diesel_PSMP : 32|1@0+ (1,0) [0|0] ""  ETC
 SG_ PNC15_DriverInfoPoll_PSMP : 31|1@0+ (1,0) [0|0] ""  ETC
 SG_ PNC14_GSD_PSMP : 30|1@0+ (1,0) [0|0] ""  ETC
 SG_ PNC13_Global_PSMP : 29|1@0+ (1,0) [0|0] ""  ETC
 SG_ PNC12_TrailerCaravan_PSMP : 28|1@0+ (1,0) [0|0] ""  ETC
 SG_ PNC11_Driving_PSMP : 27|1@0+ (1,0) [0|0] ""  ETC
 SG_ PNC10_PreClimatization_PSMP : 26|1@0+ (1,0) [0|0] ""  ETC
 SG_ PNC9_Charging_PSMP : 25|1@0+ (1,0) [0|0] ""  ETC
 SG_ PNC8_Start_PSMP : 24|1@0+ (1,0) [0|0] ""  ETC
 SG_ PNC7_Entrance_PSMP : 23|1@0+ (1,0) [0|0] ""  ETC
 SG_ PNC6_InfotainmentHMI_PSMP : 22|1@0+ (1,0) [0|0] ""  ETC
 SG_ PNC5_Body_PSMP : 21|1@0+ (1,0) [0|0] ""  ETC
 SG_ PNC4_Visibility_PSMP : 20|1@0+ (1,0) [0|0] ""  ETC
 SG_ PNC3_WarningSounds_PSMP : 19|1@0+ (1,0) [0|0] ""  ETC
 SG_ PNC2_Hazard_PSMP : 18|1@0+ (1,0) [0|0] ""  ETC
 SG_ PNC1_Locking_PSMP : 17|1@0+ (1,0) [0|0] ""  ETC
 SG_ PNC0_DriverInfo_PSMP : 16|1@0+ (1,0) [0|0] ""  ETC
 SG_ NM_AW_PSMP : 12|1@0+ (1,0) [0|0] ""  ETC
 SG_ NM_CS_PSMP : 11|1@0+ (1,0) [0|0] ""  ETC
 SG_ NM_RMR_PSMP : 8|1@0+ (1,0) [0|0] ""  ETC
 SG_ NM_PNI_PSMP : 14|1@0+ (1,0) [0|0] ""  ETC
 SG_ NM_NodeID_PSMP : 7|8@0+ (1,0) [0|0] ""  ETC

BO_ 1562 PsmpToCemBodyDiagResFrame: 8 PSMP

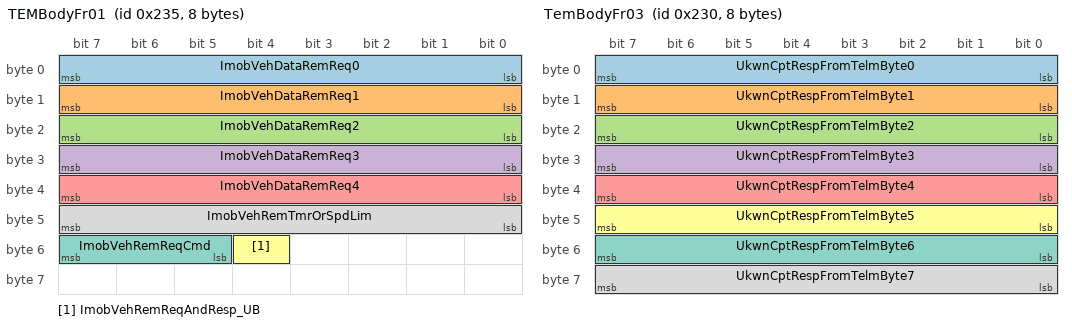
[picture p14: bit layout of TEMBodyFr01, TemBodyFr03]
BO_ 565 TEMBodyFr01: 8 VCM
 SG_ ImobVehDataRemReq0 : 7|8@0+ (1,0) [0|255] ""  CEM
 SG_ ImobVehDataRemReq1 : 15|8@0+ (1,0) [0|255] ""  CEM
 SG_ ImobVehDataRemReq2 : 23|8@0+ (1,0) [0|255] ""  CEM
 SG_ ImobVehDataRemReq3 : 31|8@0+ (1,0) [0|255] ""  CEM
 SG_ ImobVehDataRemReq4 : 39|8@0+ (1,0) [0|255] ""  CEM
 SG_ ImobVehRemReqAndResp_UB : 52|1@0+ (1,0) [0|1] ""  CEM
 SG_ ImobVehRemReqCmd : 55|3@0+ (1,0) [0|7] ""  CEM
 SG_ ImobVehRemTmrOrSpdLim : 47|8@0+ (1,0) [0|255] ""  CEM

BO_ 192 TemBodyFr02: 8 VCM
 SG_ CarFindrHornLiReqFromTelm : 1|2@0+ (1,0) [0|3] ""  CEM
 SG_ CarFindrHornLiReqFromTelm_UB : 23|1@0+ (1,0) [0|1] ""  CEM
 SG_ ClimaRqrd1 : 13|2@0+ (1,0) [0|3] ""  CCM
 SG_ ClimaRqrd1_UB : 22|1@0+ (1,0) [0|1] ""  CCM
 SG_ EmgyAsscSts : 7|3@0+ (1,0) [0|7] ""  CEM
 SG_ EmgyAsscSts_UB : 21|1@0+ (1,0) [0|1] ""  CEM
 SG_ ErsCmdRec_UB : 52|1@0+ (1,0) [0|1] ""  CEM
 SG_ ErsCmdRecErsCmd : 41|2@0+ (1,0) [0|3] ""  CEM
 SG_ ErsCmdRecErsLeftFrontSeatHeat : 55|1@0+ (1,0) [0|1] ""  CEM
 SG_ ErsCmdRecErsRightFrontSeatHeat : 54|1@0+ (1,0) [0|1] ""  CEM
 SG_ ErsCmdRecErsRunTime : 47|6@0+ (1,0) [0|59] "Mins"  CEM
 SG_ ErsCmdRecErsSteeringWheelHeat : 53|1@0+ (1,0) [0|1] ""  CEM
 SG_ NetTelmActvt_UB : 25|1@0+ (1,0) [0|1] ""  CEM
 SG_ NetTelmActvtPrio : 24|1@0+ (1,0) [0|1] ""  CEM
 SG_ NetTelmActvtResourceGroup : 39|8@0+ (1,0) [0|255] ""  CEM
 SG_ RoadAsscSts : 4|3@0+ (1,0) [0|7] ""  CEM
 SG_ RoadAsscSts_UB : 20|1@0+ (1,0) [0|1] ""  CEM
 SG_ SeatHeatDurgClimaEnadFromTelm : 15|2@0+ (1,0) [0|3] ""  CCM
 SG_ SeatHeatDurgClimaEnadFromTelm_UB : 19|1@0+ (1,0) [0|1] ""  CCM
 SG_ SteerWhlHeatgDurgClimaEnadFromTe : 11|1@0+ (1,0) [0|1] ""  CCM
 SG_ SteerWhlHeatgDurgClimaEnadF_0000 : 18|1@0+ (1,0) [0|1] ""  CCM
 SG_ TelmFctReq : 10|1@0+ (1,0) [0|1] ""  CEM
 SG_ TelmFctReq_UB : 17|1@0+ (1,0) [0|1] ""  CEM
 SG_ TelmLockgCenReq : 27|2@0+ (1,0) [0|3] ""  CEM
 SG_ TelmLockgReq_UB : 51|1@0+ (1,0) [0|1] ""  CEM
 SG_ TelmSts : 9|2@0+ (1,0) [0|3] ""  CEM
 SG_ TelmSts_UB : 16|1@0+ (1,0) [0|1] ""  CEM
 SG_ UInt4 : 31|4@0+ (1,0) [0|15] ""  CEM

BO_ 560 TemBodyFr03: 8 VCM
 SG_ UkwnCptRespFromTelmByte0 : 7|8@0+ (1,0) [0|255] ""  CEM
 SG_ UkwnCptRespFromTelmByte1 : 15|8@0+ (1,0) [0|255] ""  CEM
 SG_ UkwnCptRespFromTelmByte2 : 23|8@0+ (1,0) [0|255] ""  CEM
 SG_ UkwnCptRespFromTelmByte3 : 31|8@0+ (1,0) [0|255] ""  CEM
 SG_ UkwnCptRespFromTelmByte4 : 39|8@0+ (1,0) [0|255] ""  CEM
 SG_ UkwnCptRespFromTelmByte5 : 47|8@0+ (1,0) [0|255] ""  CEM
 SG_ UkwnCptRespFromTelmByte6 : 55|8@0+ (1,0) [0|255] ""  CEM
 SG_ UkwnCptRespFromTelmByte7 : 63|8@0+ (1,0) [0|255] ""  CEM

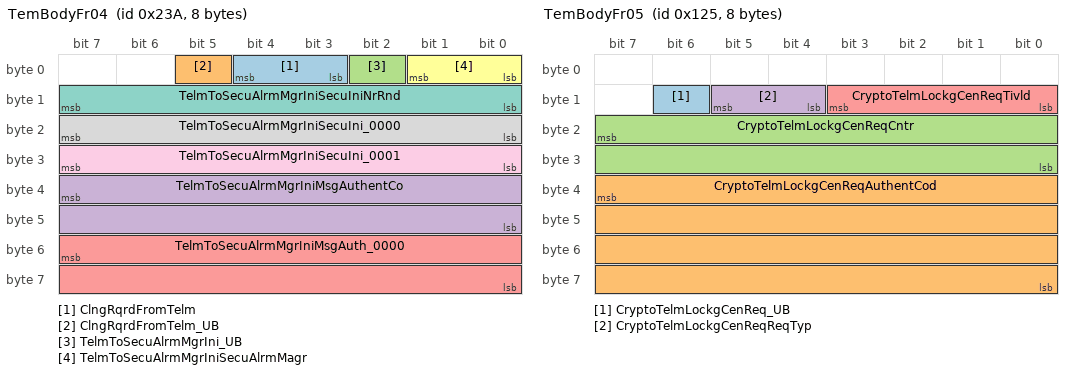
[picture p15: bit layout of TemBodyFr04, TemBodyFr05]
BO_ 570 TemBodyFr04: 8 VCM
 SG_ ClngRqrdFromTelm : 4|2@0+ (1,0) [0|3] ""  CCM
 SG_ ClngRqrdFromTelm_UB : 5|1@0+ (1,0) [0|1] ""  CCM
 SG_ TelmToSecuAlrmMgrIni_UB : 2|1@0+ (1,0) [0|1] ""  CEM
 SG_ TelmToSecuAlrmMgrIniMsgAuthentCo : 39|16@0+ (1,0) [0|65535] ""  CEM
 SG_ TelmToSecuAlrmMgrIniMsgAuth_0000 : 55|16@0+ (1,0) [0|65535] ""  CEM
 SG_ TelmToSecuAlrmMgrIniSecuAlrmMagr : 1|2@0+ (1,0) [0|3] ""  CEM
 SG_ TelmToSecuAlrmMgrIniSecuIniNrRnd : 15|8@0+ (1,0) [0|255] ""  CEM
 SG_ TelmToSecuAlrmMgrIniSecuIni_0000 : 23|8@0+ (1,0) [0|255] ""  CEM
 SG_ TelmToSecuAlrmMgrIniSecuIni_0001 : 31|8@0+ (1,0) [0|255] ""  CEM

BO_ 293 TemBodyFr05: 8 VCM
 SG_ CryptoTelmLockgCenReq_UB : 14|1@0+ (1,0) [0|1] ""  CEM
 SG_ CryptoTelmLockgCenReqAuthentCod : 39|32@0+ (1,0) [0|4294967295] ""  CEM
 SG_ CryptoTelmLockgCenReqCntr : 23|16@0+ (1,0) [0|65535] ""  CEM
 SG_ CryptoTelmLockgCenReqReqTyp : 13|2@0+ (1,0) [0|3] ""  CEM
 SG_ CryptoTelmLockgCenReqTivld : 11|4@0+ (1,0) [0|15] ""  CEM

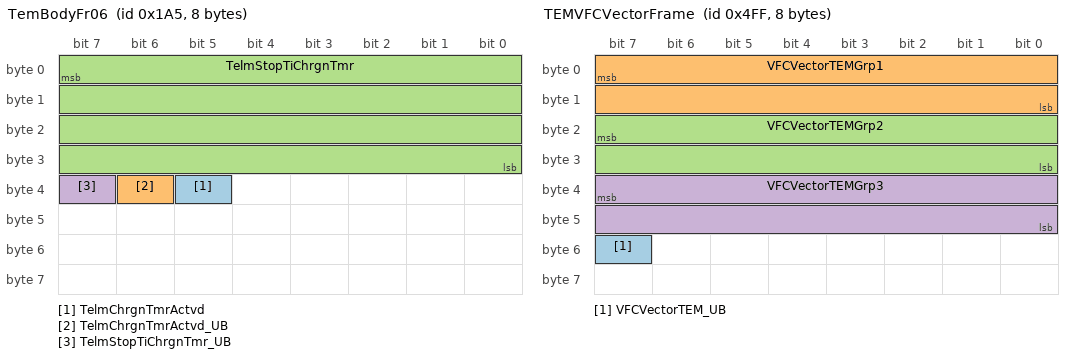
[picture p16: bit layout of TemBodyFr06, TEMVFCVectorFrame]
BO_ 421 TemBodyFr06: 8 VCM
 SG_ TelmChrgnTmrActvd : 37|1@0+ (1,0) [0|1] ""  CEM
 SG_ TelmChrgnTmrActvd_UB : 38|1@0+ (1,0) [0|1] ""  CEM
 SG_ TelmStopTiChrgnTmr : 7|32@0+ (0.1,0) [0|429496729.5] "s"  CEM
 SG_ TelmStopTiChrgnTmr_UB : 39|1@0+ (1,0) [0|1] ""  CEM

BO_ 423 TemBodyFr07: 8 VCM
 SG_ TelmStrtTiChrgnTmr : 7|32@0+ (0.1,0) [0|429496729.5] "s"  CEM
 SG_ TelmStrtTiChrgnTmr_UB : 39|1@0+ (1,0) [0|1] ""  CEM

BO_ 1289 TemBodyNMFr: 8 VCM
 SG_ PNC23_Spare1_VCM : 39|1@0+ (1,0) [0|0] ""  ETC
 SG_ PNC22_Spare2_VCM : 38|1@0+ (1,0) [0|0] ""  ETC
 SG_ PNC21_Spare3_VCM : 37|1@0+ (1,0) [0|0] ""  ETC
 SG_ PNC20_Spare4_VCM : 36|1@0+ (1,0) [0|0] ""  ETC
 SG_ PNC19_Spare5_VCM : 35|1@0+ (1,0) [0|0] ""  ETC
 SG_ PNC18_Spare6_VCM : 34|1@0+ (1,0) [0|0] ""  ETC
 SG_ PNC17_Spare7_VCM : 33|1@0+ (1,0) [0|0] ""  ETC
 SG_ PNC16_Diesel_VCM : 32|1@0+ (1,0) [0|0] ""  ETC
 SG_ PNC15_DriverInfoPoll_VCM : 31|1@0+ (1,0) [0|0] ""  ETC
 SG_ PNC14_GSD_VCM : 30|1@0+ (1,0) [0|0] ""  ETC
 SG_ PNC13_Global_VCM : 29|1@0+ (1,0) [0|0] ""  ETC
 SG_ PNC12_TrailerCaravan_VCM : 28|1@0+ (1,0) [0|0] ""  ETC
 SG_ PNC11_Driving_VCM : 27|1@0+ (1,0) [0|0] ""  ETC
 SG_ PNC10_PreClimatization_VCM : 26|1@0+ (1,0) [0|0] ""  ETC
 SG_ PNC9_Charging_VCM : 25|1@0+ (1,0) [0|0] ""  ETC
 SG_ PNC8_Start_VCM : 24|1@0+ (1,0) [0|0] ""  ETC
 SG_ PNC7_Entrance_VCM : 23|1@0+ (1,0) [0|0] ""  ETC
 SG_ PNC6_InfotainmentHMI_VCM : 22|1@0+ (1,0) [0|0] ""  ETC
 SG_ PNC5_Body_VCM : 21|1@0+ (1,0) [0|0] ""  ETC
 SG_ PNC4_Visibility_VCM : 20|1@0+ (1,0) [0|0] ""  ETC
 SG_ PNC3_WarningSounds_VCM : 19|1@0+ (1,0) [0|0] ""  ETC
 SG_ PNC2_Hazard_VCM : 18|1@0+ (1,0) [0|0] ""  ETC
 SG_ PNC1_Locking_VCM : 17|1@0+ (1,0) [0|0] ""  ETC
 SG_ PNC0_DriverInfo_VCM : 16|1@0+ (1,0) [0|0] ""  ETC
 SG_ NM_AW_VCM : 12|1@0+ (1,0) [0|0] ""  ETC
 SG_ NM_CS_VCM : 11|1@0+ (1,0) [0|0] ""  ETC
 SG_ NM_RMR_VCM : 8|1@0+ (1,0) [0|0] ""  ETC
 SG_ NM_PNI_VCM : 14|1@0+ (1,0) [0|0] ""  ETC
 SG_ NM_NodeID_VCM : 7|8@0+ (1,0) [0|0] ""  ETC

BO_ 1279 TEMVFCVectorFrame: 8 VCM
 SG_ VFCVectorTEM_UB : 55|1@0+ (1,0) [0|1] ""  CEM
 SG_ VFCVectorTEMGrp1 : 7|16@0+ (1,0) [0|65535] ""  CEM
 SG_ VFCVectorTEMGrp2 : 23|16@0+ (1,0) [0|65535] ""  CEM
 SG_ VFCVectorTEMGrp3 : 39|16@0+ (1,0) [0|65535] ""  CEM

BO_ 208 TRMBodyFr01: 4 TRM
 SG_ TrlrFogLiSts : 17|1@0+ (1,0) [0|1] ""  CEM
 SG_ TrlrFogLiSts_UB : 16|1@0+ (1,0) [0|1] ""  CEM
 SG_ TrlrIndcrLeSts : 1|1@0+ (1,0) [0|1] ""  CEM
 SG_ TrlrIndcrLeSts_UB : 10|1@0+ (1,0) [0|1] ""  CEM
 SG_ TrlrIndcrRiSts : 0|1@0+ (1,0) [0|1] ""  CEM
 SG_ TrlrIndcrRiSts_UB : 9|1@0+ (1,0) [0|1] ""  CEM
 SG_ TrlrLampActvtChk : 15|1@0+ (1,0) [0|1] ""  CEM
 SG_ TrlrLampActvtChk_UB : 8|1@0+ (1,0) [0|1] ""  CEM
 SG_ TrlrLampChkSts : 7|3@0+ (1,0) [0|7] ""  CEM
 SG_ TrlrLampChkSts_UB : 23|1@0+ (1,0) [0|1] ""  CEM
 SG_ TrlrLiSts : 4|3@0+ (1,0) [0|7] ""  CEM
 SG_ TrlrLiSts_UB : 22|1@0+ (1,0) [0|1] ""  CEM
 SG_ TrlrPrmntPwrActv : 14|1@0+ (1,0) [0|1] ""  CEM
 SG_ TrlrPrmntPwrActv_UB : 21|1@0+ (1,0) [0|1] ""  CEM
 SG_ TrlrPrsnt : 13|1@0+ (1,0) [0|1] ""  CEM
 SG_ TrlrPrsnt_UB : 20|1@0+ (1,0) [0|1] ""  CEM
 SG_ TrlrSrvReq : 12|1@0+ (1,0) [0|1] ""  CEM
 SG_ TrlrSrvReq_UB : 19|1@0+ (1,0) [0|1] ""  CEM
 SG_ TwbrWarnSts : 11|1@0+ (1,0) [0|1] ""  CEM
 SG_ TwbrWarnSts_UB : 18|1@0+ (1,0) [0|1] ""  CEM

BO_ 1290 TrmBodyNMFr: 8 TRM
 SG_ PNC23_Spare1_TRM : 39|1@0+ (1,0) [0|0] ""  ETC
 SG_ PNC22_Spare2_TRM : 38|1@0+ (1,0) [0|0] ""  ETC
 SG_ PNC21_Spare3_TRM : 37|1@0+ (1,0) [0|0] ""  ETC
 SG_ PNC20_Spare4_TRM : 36|1@0+ (1,0) [0|0] ""  ETC
 SG_ PNC19_Spare5_TRM : 35|1@0+ (1,0) [0|0] ""  ETC
 SG_ PNC18_Spare6_TRM : 34|1@0+ (1,0) [0|0] ""  ETC
 SG_ PNC17_Spare7_TRM : 33|1@0+ (1,0) [0|0] ""  ETC
 SG_ PNC16_Diesel_TRM : 32|1@0+ (1,0) [0|0] ""  ETC
 SG_ PNC15_DriverInfoPoll_TRM : 31|1@0+ (1,0) [0|0] ""  ETC
 SG_ PNC14_GSD_TRM : 30|1@0+ (1,0) [0|0] ""  ETC
 SG_ PNC13_Global_TRM : 29|1@0+ (1,0) [0|0] ""  ETC
 SG_ PNC12_TrailerCaravan_TRM : 28|1@0+ (1,0) [0|0] ""  ETC
 SG_ PNC11_Driving_TRM : 27|1@0+ (1,0) [0|0] ""  ETC
 SG_ PNC10_PreClimatization_TRM : 26|1@0+ (1,0) [0|0] ""  ETC
 SG_ PNC9_Charging_TRM : 25|1@0+ (1,0) [0|0] ""  ETC
 SG_ PNC8_Start_TRM : 24|1@0+ (1,0) [0|0] ""  ETC
 SG_ PNC7_Entrance_TRM : 23|1@0+ (1,0) [0|0] ""  ETC
 SG_ PNC6_InfotainmentHMI_TRM : 22|1@0+ (1,0) [0|0] ""  ETC
 SG_ PNC5_Body_TRM : 21|1@0+ (1,0) [0|0] ""  ETC
 SG_ PNC4_Visibility_TRM : 20|1@0+ (1,0) [0|0] ""  ETC
 SG_ PNC3_WarningSounds_TRM : 19|1@0+ (1,0) [0|0] ""  ETC
 SG_ PNC2_Hazard_TRM : 18|1@0+ (1,0) [0|0] ""  ETC
 SG_ PNC1_Locking_TRM : 17|1@0+ (1,0) [0|0] ""  ETC
 SG_ PNC0_DriverInfo_TRM : 16|1@0+ (1,0) [0|0] ""  ETC
 SG_ NM_AW_TRM : 12|1@0+ (1,0) [0|0] ""  ETC
 SG_ NM_CS_TRM : 11|1@0+ (1,0) [0|0] ""  ETC
 SG_ NM_RMR_TRM : 8|1@0+ (1,0) [0|0] ""  ETC
 SG_ NM_PNI_TRM : 14|1@0+ (1,0) [0|0] ""  ETC
 SG_ NM_NodeID_TRM : 7|8@0+ (1,0) [0|0] ""  ETC

BO_ 1559 TrmToCemBodyDiagResFrame: 8 TRM

BO_ 1464 TRMtoETCXcpFr01: 8 TRM

CM_ SG_ 1442 DevReqToPassDoorReByte0 "Development request signal to the Rear Passenger door module Byte0";
CM_ SG_ 1442 DevReqToPassDoorReByte1 "Development request signal to the Rear Passenger door module Byte1";
CM_ SG_ 1442 DevReqToPassDoorReByte2 "Development request signal to the Rear Passenger door module Byte2";
CM_ SG_ 1442 DevReqToPassDoorReByte3 "Development request signal to the Rear Passenger door module Byte3";
CM_ SG_ 1442 DevReqToPassDoorReByte4 "Development request signal to the Rear Passenger door module Byte4";
CM_ SG_ 1442 DevReqToPassDoorReByte5 "Development request signal to the Rear Passenger door module Byte5";
CM_ SG_ 1442 DevReqToPassDoorReByte6 "Development request signal to the Rear Passenger door module Byte6";
CM_ SG_ 1442 DevReqToPassDoorReByte7 "Development request signal to the Rear Passenger door module Byte7";
CM_ SG_ 1473 ETCBodyDevReqToPassSeatByte0 "KOSTIA request. Supplier specific signal used for their EOL test. Not transmitted in vehicle. Byte0";
CM_ SG_ 1473 ETCBodyDevReqToPassSeatByte1 "KOSTIA request. Supplier specific signal used for their EOL test. Not transmitted in vehicle. Byte1";
CM_ SG_ 1473 ETCBodyDevReqToPassSeatByte2 "KOSTIA request. Supplier specific signal used for their EOL test. Not transmitted in vehicle. Byte2";
CM_ SG_ 1473 ETCBodyDevReqToPassSeatByte3 "KOSTIA request. Supplier specific signal used for their EOL test. Not transmitted in vehicle. Byte3";
CM_ SG_ 1473 ETCBodyDevReqToPassSeatByte4 "KOSTIA request. Supplier specific signal used for their EOL test. Not transmitted in vehicle. Byte4";
CM_ SG_ 1473 ETCBodyDevReqToPassSeatByte5 "KOSTIA request. Supplier specific signal used for their EOL test. Not transmitted in vehicle. Byte5";
CM_ SG_ 1473 ETCBodyDevReqToPassSeatByte6 "KOSTIA request. Supplier specific signal used for their EOL test. Not transmitted in vehicle. Byte6";
CM_ SG_ 1473 ETCBodyDevReqToPassSeatByte7 "KOSTIA request. Supplier specific signal used for their EOL test. Not transmitted in vehicle. Byte7";
CM_ SG_ 1422 DevDataForPrkgAssi1Byte0 "Signal for development and analysis data for the park assist system. Byte0";
CM_ SG_ 1422 DevDataForPrkgAssi1Byte1 "Signal for development and analysis data for the park assist system. Byte1";
CM_ SG_ 1422 DevDataForPrkgAssi1Byte2 "Signal for development and analysis data for the park assist system. Byte2";
CM_ SG_ 1422 DevDataForPrkgAssi1Byte3 "Signal for development and analysis data for the park assist system. Byte3";
CM_ SG_ 1422 DevDataForPrkgAssi1Byte4 "Signal for development and analysis data for the park assist system. Byte4";
CM_ SG_ 1422 DevDataForPrkgAssi1Byte5 "Signal for development and analysis data for the park assist system. Byte5";
CM_ SG_ 1422 DevDataForPrkgAssi1Byte6 "Signal for development and analysis data for the park assist system. Byte6";
CM_ SG_ 1422 DevDataForPrkgAssi1Byte7 "Signal for development and analysis data for the park assist system. Byte7";
CM_ SG_ 1420 DevDataForPrkgAssi2Byte0 "Signal for development and analysis data for the park assist system. Byte0";
CM_ SG_ 1420 DevDataForPrkgAssi2Byte1 "Signal for development and analysis data for the park assist system. Byte1";
CM_ SG_ 1420 DevDataForPrkgAssi2Byte2 "Signal for development and analysis data for the park assist system. Byte2";
CM_ SG_ 1420 DevDataForPrkgAssi2Byte3 "Signal for development and analysis data for the park assist system. Byte3";
CM_ SG_ 1420 DevDataForPrkgAssi2Byte4 "Signal for development and analysis data for the park assist system. Byte4";
CM_ SG_ 1420 DevDataForPrkgAssi2Byte5 "Signal for development and analysis data for the park assist system. Byte5";
CM_ SG_ 1420 DevDataForPrkgAssi2Byte6 "Signal for development and analysis data for the park assist system. Byte6";
CM_ SG_ 1420 DevDataForPrkgAssi2Byte7 "Signal for development and analysis data for the park assist system. Byte7";
CM_ SG_ 1447 DevDataForPrkgAssi3Byte0 "Signal for development and analysis data for the park assist system. Byte0";
CM_ SG_ 1447 DevDataForPrkgAssi3Byte1 "Signal for development and analysis data for the park assist system. Byte1";
CM_ SG_ 1447 DevDataForPrkgAssi3Byte2 "Signal for development and analysis data for the park assist system. Byte2";
CM_ SG_ 1447 DevDataForPrkgAssi3Byte3 "Signal for development and analysis data for the park assist system. Byte3";
CM_ SG_ 1447 DevDataForPrkgAssi3Byte4 "Signal for development and analysis data for the park assist system. Byte4";
CM_ SG_ 1447 DevDataForPrkgAssi3Byte5 "Signal for development and analysis data for the park assist system. Byte5";
CM_ SG_ 1447 DevDataForPrkgAssi3Byte6 "Signal for development and analysis data for the park assist system. Byte6";
CM_ SG_ 1447 DevDataForPrkgAssi3Byte7 "Signal for development and analysis data for the park assist system. Byte7";
CM_ SG_ 1421 DevDataForPrkgAssi4Byte0 "Signal for development and analysis data for the park assist system. Byte0";
CM_ SG_ 1421 DevDataForPrkgAssi4Byte1 "Signal for development and analysis data for the park assist system. Byte1";
CM_ SG_ 1421 DevDataForPrkgAssi4Byte2 "Signal for development and analysis data for the park assist system. Byte2";
CM_ SG_ 1421 DevDataForPrkgAssi4Byte3 "Signal for development and analysis data for the park assist system. Byte3";
CM_ SG_ 1421 DevDataForPrkgAssi4Byte4 "Signal for development and analysis data for the park assist system. Byte4";
CM_ SG_ 1421 DevDataForPrkgAssi4Byte5 "Signal for development and analysis data for the park assist system. Byte5";
CM_ SG_ 1421 DevDataForPrkgAssi4Byte6 "Signal for development and analysis data for the park assist system. Byte6";
CM_ SG_ 1421 DevDataForPrkgAssi4Byte7 "Signal for development and analysis data for the park assist system. Byte7";
CM_ SG_ 1423 DevDataForPrkgAssi5Byte0 "Signal for development and analysis data for the park assist system. Byte0";
CM_ SG_ 1423 DevDataForPrkgAssi5Byte1 "Signal for development and analysis data for the park assist system. Byte1";
CM_ SG_ 1423 DevDataForPrkgAssi5Byte2 "Signal for development and analysis data for the park assist system. Byte2";
CM_ SG_ 1423 DevDataForPrkgAssi5Byte3 "Signal for development and analysis data for the park assist system. Byte3";
CM_ SG_ 1423 DevDataForPrkgAssi5Byte4 "Signal for development and analysis data for the park assist system. Byte4";
CM_ SG_ 1423 DevDataForPrkgAssi5Byte5 "Signal for development and analysis data for the park assist system. Byte5";
CM_ SG_ 1423 DevDataForPrkgAssi5Byte6 "Signal for development and analysis data for the park assist system. Byte6";
CM_ SG_ 1423 DevDataForPrkgAssi5Byte7 "Signal for development and analysis data for the park assist system. Byte7";
CM_ SG_ 1439 DevDataForPrkgAssi6Byte0 "Signal for development and analysis data for the park assist system. Byte0";
CM_ SG_ 1439 DevDataForPrkgAssi6Byte1 "Signal for development and analysis data for the park assist system. Byte1";
CM_ SG_ 1439 DevDataForPrkgAssi6Byte2 "Signal for development and analysis data for the park assist system. Byte2";
CM_ SG_ 1439 DevDataForPrkgAssi6Byte3 "Signal for development and analysis data for the park assist system. Byte3";
CM_ SG_ 1439 DevDataForPrkgAssi6Byte4 "Signal for development and analysis data for the park assist system. Byte4";
CM_ SG_ 1439 DevDataForPrkgAssi6Byte5 "Signal for development and analysis data for the park assist system. Byte5";
CM_ SG_ 1439 DevDataForPrkgAssi6Byte6 "Signal for development and analysis data for the park assist system. Byte6";
CM_ SG_ 1439 DevDataForPrkgAssi6Byte7 "Signal for development and analysis data for the park assist system. Byte7";
CM_ SG_ 1445 DevDataForPrkgAssi7Byte0 "Signal for development and analysis data for the park assist system. Byte0";
CM_ SG_ 1445 DevDataForPrkgAssi7Byte1 "Signal for development and analysis data for the park assist system. Byte1";
CM_ SG_ 1445 DevDataForPrkgAssi7Byte2 "Signal for development and analysis data for the park assist system. Byte2";
CM_ SG_ 1445 DevDataForPrkgAssi7Byte3 "Signal for development and analysis data for the park assist system. Byte3";
CM_ SG_ 1445 DevDataForPrkgAssi7Byte4 "Signal for development and analysis data for the park assist system. Byte4";
CM_ SG_ 1445 DevDataForPrkgAssi7Byte5 "Signal for development and analysis data for the park assist system. Byte5";
CM_ SG_ 1445 DevDataForPrkgAssi7Byte6 "Signal for development and analysis data for the park assist system. Byte6";
CM_ SG_ 1445 DevDataForPrkgAssi7Byte7 "Signal for development and analysis data for the park assist system. Byte7";
CM_ SG_ 1444 DevDataForPrkgAssi8Byte0 "Signal for development and analysis data for the park assist system. Byte0";
CM_ SG_ 1444 DevDataForPrkgAssi8Byte1 "Signal for development and analysis data for the park assist system. Byte1";
CM_ SG_ 1444 DevDataForPrkgAssi8Byte2 "Signal for development and analysis data for the park assist system. Byte2";
CM_ SG_ 1444 DevDataForPrkgAssi8Byte3 "Signal for development and analysis data for the park assist system. Byte3";
CM_ SG_ 1444 DevDataForPrkgAssi8Byte4 "Signal for development and analysis data for the park assist system. Byte4";
CM_ SG_ 1444 DevDataForPrkgAssi8Byte5 "Signal for development and analysis data for the park assist system. Byte5";
CM_ SG_ 1444 DevDataForPrkgAssi8Byte6 "Signal for development and analysis data for the park assist system. Byte6";
CM_ SG_ 1444 DevDataForPrkgAssi8Byte7 "Signal for development and analysis data for the park assist system. Byte7";
CM_ SG_ 1419 DevDataForPrkgAssi9Byte0 "Signal for development and analysis data for the park assist system. Byte0";
CM_ SG_ 1419 DevDataForPrkgAssi9Byte1 "Signal for development and analysis data for the park assist system. Byte1";
CM_ SG_ 1419 DevDataForPrkgAssi9Byte2 "Signal for development and analysis data for the park assist system. Byte2";
CM_ SG_ 1419 DevDataForPrkgAssi9Byte3 "Signal for development and analysis data for the park assist system. Byte3";
CM_ SG_ 1419 DevDataForPrkgAssi9Byte4 "Signal for development and analysis data for the park assist system. Byte4";
CM_ SG_ 1419 DevDataForPrkgAssi9Byte5 "Signal for development and analysis data for the park assist system. Byte5";
CM_ SG_ 1419 DevDataForPrkgAssi9Byte6 "Signal for development and analysis data for the park assist system. Byte6";
CM_ SG_ 1419 DevDataForPrkgAssi9Byte7 "Signal for development and analysis data for the park assist system. Byte7";
CM_ SG_ 1418 DevDataForPrkgAssi10Byte0 "Signal for development and analysis data for the park assist system. Byte0";
CM_ SG_ 1418 DevDataForPrkgAssi10Byte1 "Signal for development and analysis data for the park assist system. Byte1";
CM_ SG_ 1418 DevDataForPrkgAssi10Byte2 "Signal for development and analysis data for the park assist system. Byte2";
CM_ SG_ 1418 DevDataForPrkgAssi10Byte3 "Signal for development and analysis data for the park assist system. Byte3";
CM_ SG_ 1418 DevDataForPrkgAssi10Byte4 "Signal for development and analysis data for the park assist system. Byte4";
CM_ SG_ 1418 DevDataForPrkgAssi10Byte5 "Signal for development and analysis data for the park assist system. Byte5";
CM_ SG_ 1418 DevDataForPrkgAssi10Byte6 "Signal for development and analysis data for the park assist system. Byte6";
CM_ SG_ 1418 DevDataForPrkgAssi10Byte7 "Signal for development and analysis data for the park assist system. Byte7";
CM_ SG_ 1446 DevDataForPrkgAssi11Byte0 "Signal for development and analysis data for the park assist system. Byte0";
CM_ SG_ 1446 DevDataForPrkgAssi11Byte1 "Signal for development and analysis data for the park assist system. Byte1";
CM_ SG_ 1446 DevDataForPrkgAssi11Byte2 "Signal for development and analysis data for the park assist system. Byte2";
CM_ SG_ 1446 DevDataForPrkgAssi11Byte3 "Signal for development and analysis data for the park assist system. Byte3";
CM_ SG_ 1446 DevDataForPrkgAssi11Byte4 "Signal for development and analysis data for the park assist system. Byte4";
CM_ SG_ 1446 DevDataForPrkgAssi11Byte5 "Signal for development and analysis data for the park assist system. Byte5";
CM_ SG_ 1446 DevDataForPrkgAssi11Byte6 "Signal for development and analysis data for the park assist system. Byte6";
CM_ SG_ 1446 DevDataForPrkgAssi11Byte7 "Signal for development and analysis data for the park assist system. Byte7";
CM_ SG_ 1437 DevDataForPrkgAssi12Byte0 "Signal for development and analysis data for the park assist system. Byte0";
CM_ SG_ 1437 DevDataForPrkgAssi12Byte1 "Signal for development and analysis data for the park assist system. Byte1";
CM_ SG_ 1437 DevDataForPrkgAssi12Byte2 "Signal for development and analysis data for the park assist system. Byte2";
CM_ SG_ 1437 DevDataForPrkgAssi12Byte3 "Signal for development and analysis data for the park assist system. Byte3";
CM_ SG_ 1437 DevDataForPrkgAssi12Byte4 "Signal for development and analysis data for the park assist system. Byte4";
CM_ SG_ 1437 DevDataForPrkgAssi12Byte5 "Signal for development and analysis data for the park assist system. Byte5";
CM_ SG_ 1437 DevDataForPrkgAssi12Byte6 "Signal for development and analysis data for the park assist system. Byte6";
CM_ SG_ 1437 DevDataForPrkgAssi12Byte7 "Signal for development and analysis data for the park assist system. Byte7";
CM_ SG_ 1438 DevDataForPrkgAssi13Byte0 "Signal for development and analysis data for the park assist system. Byte0";
CM_ SG_ 1438 DevDataForPrkgAssi13Byte1 "Signal for development and analysis data for the park assist system. Byte1";
CM_ SG_ 1438 DevDataForPrkgAssi13Byte2 "Signal for development and analysis data for the park assist system. Byte2";
CM_ SG_ 1438 DevDataForPrkgAssi13Byte3 "Signal for development and analysis data for the park assist system. Byte3";
CM_ SG_ 1438 DevDataForPrkgAssi13Byte4 "Signal for development and analysis data for the park assist system. Byte4";
CM_ SG_ 1438 DevDataForPrkgAssi13Byte5 "Signal for development and analysis data for the park assist system. Byte5";
CM_ SG_ 1438 DevDataForPrkgAssi13Byte6 "Signal for development and analysis data for the park assist system. Byte6";
CM_ SG_ 1438 DevDataForPrkgAssi13Byte7 "Signal for development and analysis data for the park assist system. Byte7";
CM_ SG_ 1448 DevDataForPrkgAssi14Byte0 "Signal for development and analysis data for the park assist system. Byte0";
CM_ SG_ 1448 DevDataForPrkgAssi14Byte1 "Signal for development and analysis data for the park assist system. Byte1";
CM_ SG_ 1448 DevDataForPrkgAssi14Byte2 "Signal for development and analysis data for the park assist system. Byte2";
CM_ SG_ 1448 DevDataForPrkgAssi14Byte3 "Signal for development and analysis data for the park assist system. Byte3";
CM_ SG_ 1448 DevDataForPrkgAssi14Byte4 "Signal for development and analysis data for the park assist system. Byte4";
CM_ SG_ 1448 DevDataForPrkgAssi14Byte5 "Signal for development and analysis data for the park assist system. Byte5";
CM_ SG_ 1448 DevDataForPrkgAssi14Byte6 "Signal for development and analysis data for the park assist system. Byte6";
CM_ SG_ 1448 DevDataForPrkgAssi14Byte7 "Signal for development and analysis data for the park assist system. Byte7";
CM_ SG_ 16 ChdLockgProtnStsAtPassRe "CdhLockgProtnStsAtPassRe - Child Lock Protection Status at Passenger side Rear Door

Indicates child lock status for passenger side rear door:

On - Child lock is active
Off - Child lock is not active";
CM_ SG_ 16 ChdLockgProtnStsAtPassRe_UB "Update bit for signal ChdLockgProtnStsAtPassRe";
CM_ SG_ 16 ChdWinProtnStsAtPassRe "'Signal sent from the rear passenger door module to the Driver door module that informs of the local status of the power window disable functionality.
'
";
CM_ SG_ 16 ChdWinProtnStsAtPassRe_UB "Update bit for signal ChdWinProtnStsAtPassRe";
CM_ SG_ 16 CurtReReqFromRe_UB "Update bit for signal CurtReReqFromRe";
CM_ SG_ 16 DoorPassLockReSts "DoorPassLockReSts - Passenger Side Rear Door Lock Status

Lock status:

LockStsUkwn - Lock Status Unknown
Unlckd - Unlocked
Lockd - Locked
SafeLockd - Safe Locked (Double Locked)";
CM_ SG_ 16 DoorPassLockReSts_UB "Update bit for signal DoorPassLockReSts";
CM_ SG_ 16 DoorPassLockSts "DoorPassLockSts - Passenger Door Lock Status

Lock status:

LockStsUkwn - Lock Status Unknown
Unlckd - Unlocked
Lockd - Locked
SafeLockd - Safe Locked (Double Locked)";
CM_ SG_ 16 DoorPassLockSts_UB "Update bit for signal DoorPassLockSts";
CM_ SG_ 16 DoorPassSwtIntrLockgReq "DoorPassSwtIntrLockgReq - Passenger Door Interior Locking Switch Request

Central locking/unlocking request from passenger door interior central locking/unlocking switch

Idle - No Request
Unlck - Unlock request
Lock - Lock request";
CM_ SG_ 16 DoorPassSwtIntrLockgReq_UB "Update bit for signal DoorPassSwtIntrLockgReq";
CM_ SG_ 16 DoorPassSwtLockgReSts "DoorPassSwtLockgReSts - Passenger Side Rear Door Locking Switch Status

Status of the passenger side rear door interior locking switch:

Psd - Pressed
NotPsd - Not Pressed";
CM_ SG_ 16 DoorPassSwtLockgReSts_UB "Update bit for signal DoorPassSwtLockgReSts";
CM_ SG_ 16 LcmaLedStsPassSide "Signal which indicates if the LCMA LED HMI is broken or not.";
CM_ SG_ 16 LcmaLedStsPassSide_UB "Update bit for signal LcmaLedStsPassSide";
CM_ SG_ 16 MirrAtPassInMovmt "Informs the Setting Management subsystem that the outer rear view mirrors are in movement. Passanger side.";
CM_ SG_ 16 MirrAtPassInMovmt_UB "Update bit for signal MirrAtPassInMovmt";
CM_ SG_ 16 MirrDwnStsAtPass "Reports the status of the mirror dipping mode. Passanger side.";
CM_ SG_ 16 MirrDwnStsAtPass_UB "Update bit for signal MirrDwnStsAtPass";
CM_ SG_ 16 MirrFoldStsAtPass "Reports the fold status of the outer rear view mirrors. Passanger side.";
CM_ SG_ 16 MirrFoldStsAtPass_UB "Update bit for signal MirrFoldStsAtPass";
CM_ SG_ 16 PassMemBtnPsd_UB "Update bit for signal group PassMemBtnPsd; PassMemBtnPsdMemBtn1 PassMemBtnPsdMemBtn2 PassMemBtnPsdMemBtn3 PassMemBtnPsdMemButM ";
CM_ SG_ 16 PassMemBtnPsdMemBtn1 "Signals status of the passenger memory buttons (true/false) Memory button 1";
CM_ SG_ 16 PassMemBtnPsdMemBtn2 "Signals status of the passenger memory buttons (true/false) Memory Button 2";
CM_ SG_ 16 PassMemBtnPsdMemBtn3 "Signals status of the passenger memory buttons (true/false) Memory Button 3";
CM_ SG_ 16 PassMemBtnPsdMemButM "Signals status of the passenger memory buttons (true/false) Memory Button M";
CM_ SG_ 16 SunRoofAndCurtReqFromRe_UB "Update bit for signal group SunRoofAndCurtReqFromRe; SunRoofAndCurtReqFromReSunCurtRoofReqFromRe SunRoofAndCurtReqFromReSunRoofReqFromRe ";
CM_ SG_ 16 WinAndCurtSwtReqReLeFromRe_UB "Update bit for signal WinAndCurtSwtReqReLeFromRe";
CM_ SG_ 16 WinPosnStsRePass "'Signal sent to inform the rest of the car of the window position status for the rear passenger side door. The value of the signal is either an approximated percentage of openness, of the window is moving or if the position is unkown.
'
";
CM_ SG_ 16 WinPosnStsRePass_UB "Update bit for signal WinPosnStsRePass";
CM_ SG_ 352 AmbTQlyAtPassSide "Unfiltered ambient temp raw data in deg C from the passenger door module, will only give valid values for left hand driven vehicles. Shall only be used by the amient temp manager at CEM, which will transmit the correct ambient temp raw value in the signal AmbTRaw. Quality Factor of the ambient temp";
CM_ SG_ 352 AmbTRawAtPassSide_UB "Update bit for signal group AmbTRawAtPassSide; AmbTQlyAtPassSide AmbTValAtPassSide ";
CM_ SG_ 352 AmbTURawAtRiSideForObd "OBD data element for Ambient Temperature from the passanger door module. The data is direct from the ADC.";
CM_ SG_ 352 AmbTURawAtRiSideForObd_UB "Update bit for signal AmbTURawAtRiSideForObd";
CM_ SG_ 352 AmbTValAtPassSide "Unfiltered ambient temp raw data in deg C from the passenger door module, will only give valid values for left hand driven vehicles. Shall only be used by the amient temp manager at CEM, which will transmit the correct ambient temp raw value in the signal AmbTRaw. Ambient temp value";
CM_ SG_ 352 CrashUnlckFailrStsAtPass "CrashUnlckFailrStsAtPass - Passenger Door Crash Unlock Failure Status

This signal is set to On when a fault is detected that could lead to that passenger door is not correctly unlocked in case of impact. A warning shall be shown to the user via HMI.";
CM_ SG_ 352 CrashUnlckFailrStsAtPass_UB "Update bit for signal CrashUnlckFailrStsAtPass";
CM_ SG_ 352 CrashUnlckFailrStsAtPassRe "CrashUnlckFailrStsAtPassRe - Passenger Side Rear Door Crash Unlock Failure Status

This signal is set to On when a fault is detected that could lead to that passenger side rear door is not correctly unlocked in case of impact. A warning shall be shown to the user via HMI.";
CM_ SG_ 352 CrashUnlckFailrStsAtPassRe_UB "Update bit for signal CrashUnlckFailrStsAtPassRe";
CM_ SG_ 352 DoorPassReStsOfSeatSwt_UB "Update bit for signal group DoorPassReStsOfSeatSwt; DoorPassReStsOfSeatSwtActrIncSts DoorPassReStsOfSeatSwtActrSldSts ";
CM_ SG_ 352 DoorPassReStsOfSeatSwtActrIncSts " Contain actuator inclination status ";
CM_ SG_ 352 DoorPassReStsOfSeatSwtActrSldSts " Contains actuator Slide status";
CM_ SG_ 352 FltOfPuddleLiPass "Light source failure (open load or short circuit) indication to driver, puddle light passenger side.";
CM_ SG_ 352 FltOfPuddleLiPass_UB "Update bit for signal FltOfPuddleLiPass";
CM_ SG_ 352 LiPassFltIndcrTurn "Light source failure (open load or short circuit) indication to driver, side direction indicator passenger side.";
CM_ SG_ 352 LiPassFltIndcrTurn_UB "Update bit for signal LiPassFltIndcrTurn";
CM_ SG_ 352 MirrDefrstAtPassSts "Status signal exterior rear view mirror electrical defroster passenger side.";
CM_ SG_ 352 MirrDefrstAtPassSts_UB "Update bit for signal MirrDefrstAtPassSts";
CM_ SG_ 352 WinPosnStsPass "'Signal sent to inform the rest of the car of the window position status for the front passenger side door. The value of the signal is either an approximated percentage of openness, of the window is moving or if the position is unkown.
'
";
CM_ SG_ 352 WinPosnStsPass_UB "Update bit for signal WinPosnStsPass";
CM_ SG_ 298 CryptoDoorPassLockCmdInin_UB "Update bit for signal group CryptoDoorPassLockCmdInin; CryptoDoorPassLockCmdIninCmdInin1 CryptoDoorPassLockCmdIninCmdInin2 CryptoDoorPassLockCmdIninCmdInin3 ";
CM_ SG_ 298 CryptoDoorPassLockCmdIninCmdInin "Request of an initialization of the secure communication for passenger door unlock Initialization request first byte";
CM_ SG_ 298 CryptoDoorPassLockCmdIninCm_0000 "Request of an initialization of the secure communication for passenger door unlock Initialization request second byte";
CM_ SG_ 298 CryptoDoorPassLockCmdIninCm_0001 "Request of an initialization of the secure communication for passenger door unlock Initialization request third byte";
CM_ SG_ 298 CryptoDoorPassLockReCmdInin_UB "Update bit for signal group CryptoDoorPassLockReCmdInin; CryptoDoorPassLockReCmdIninCmdInin1 CryptoDoorPassLockReCmdIninCmdInin2 CryptoDoorPassLockReCmdIninCmdInin3 ";
CM_ SG_ 298 CryptoDoorPassLockReCmdIninCmdIn "Request of an initialization of the secure communication for rear passenger door unlock Initialization request first byte";
CM_ SG_ 298 CryptoDoorPassLockReCmdInin_0000 "Request of an initialization of the secure communication for rear passenger door unlock Initialization request second byte";
CM_ SG_ 298 CryptoDoorPassLockReCmdInin_0001 "Request of an initialization of the secure communication for rear passenger door unlock Initialization request third byte";
CM_ SG_ 1284 NM_AW_PDM "Active Wakeup Bit, 0: Node has not woken up the network (passive wakeup), 1: Node has woken up the network (active Wakeup)";
CM_ SG_ 1284 NM_CS_PDM "NM Coordinator Sleep Bit, 0: Start of synchronized shutdown is not requested by main coordinator, 1: Start of synchronized shutdown is requested by main coordinator";
CM_ SG_ 1284 NM_RMR_PDM "Repeat Message Request Bit, 0: Repeat Message State not requested, 1: Repeat Message State requested";
CM_ SG_ 1284 NM_PNI_PDM "Partial Network Information Bit, 0: NM message contains no Partial Network request information, 1: NM message contains Partial Network request information";
CM_ SG_ 1284 NM_NodeID_PDM "Source Node Identifier";
CM_ SG_ 1433 DevRespAtPassDoorByte0 "Development response from the Passenger door module
 Byte0";
CM_ SG_ 1433 DevRespAtPassDoorByte1 "Development response from the Passenger door module
 Byte1";
CM_ SG_ 1433 DevRespAtPassDoorByte2 "Development response from the Passenger door module
 Byte2";
CM_ SG_ 1433 DevRespAtPassDoorByte3 "Development response from the Passenger door module
 Byte3";
CM_ SG_ 1433 DevRespAtPassDoorByte4 "Development response from the Passenger door module
 Byte4";
CM_ SG_ 1433 DevRespAtPassDoorByte5 "Development response from the Passenger door module
 Byte5";
CM_ SG_ 1433 DevRespAtPassDoorByte6 "Development response from the Passenger door module
 Byte6";
CM_ SG_ 1433 DevRespAtPassDoorByte7 "Development response from the Passenger door module
 Byte7";
CM_ SG_ 1436 DevRespAtPassDoorReByte0 "Development response from the Rear Passenger door module
 Byte0";
CM_ SG_ 1436 DevRespAtPassDoorReByte1 "Development response from the Rear Passenger door module
 Byte1";
CM_ SG_ 1436 DevRespAtPassDoorReByte2 "Development response from the Rear Passenger door module
 Byte2";
CM_ SG_ 1436 DevRespAtPassDoorReByte3 "Development response from the Rear Passenger door module
 Byte3";
CM_ SG_ 1436 DevRespAtPassDoorReByte4 "Development response from the Rear Passenger door module
 Byte4";
CM_ SG_ 1436 DevRespAtPassDoorReByte5 "Development response from the Rear Passenger door module
 Byte5";
CM_ SG_ 1436 DevRespAtPassDoorReByte6 "Development response from the Rear Passenger door module
 Byte6";
CM_ SG_ 1436 DevRespAtPassDoorReByte7 "Development response from the Rear Passenger door module
 Byte7";
CM_ SG_ 1431 DevTx1AtPassDoorByte0 "Development transmission 1 from the Passenger door module
 Byte0";
CM_ SG_ 1431 DevTx1AtPassDoorByte1 "Development transmission 1 from the Passenger door module
 Byte1";
CM_ SG_ 1431 DevTx1AtPassDoorByte2 "Development transmission 1 from the Passenger door module
 Byte2";
CM_ SG_ 1431 DevTx1AtPassDoorByte3 "Development transmission 1 from the Passenger door module
 Byte3";
CM_ SG_ 1431 DevTx1AtPassDoorByte4 "Development transmission 1 from the Passenger door module
 Byte4";
CM_ SG_ 1431 DevTx1AtPassDoorByte5 "Development transmission 1 from the Passenger door module
 Byte5";
CM_ SG_ 1431 DevTx1AtPassDoorByte6 "Development transmission 1 from the Passenger door module
 Byte6";
CM_ SG_ 1431 DevTx1AtPassDoorByte7 "Development transmission 1 from the Passenger door module
 Byte7";
CM_ SG_ 1434 DevTx1AtPassDoorReByte0 "Development transmission 1 from the Rear Passenger door module
 Byte0";
CM_ SG_ 1434 DevTx1AtPassDoorReByte1 "Development transmission 1 from the Rear Passenger door module
 Byte1";
CM_ SG_ 1434 DevTx1AtPassDoorReByte2 "Development transmission 1 from the Rear Passenger door module
 Byte2";
CM_ SG_ 1434 DevTx1AtPassDoorReByte3 "Development transmission 1 from the Rear Passenger door module
 Byte3";
CM_ SG_ 1434 DevTx1AtPassDoorReByte4 "Development transmission 1 from the Rear Passenger door module
 Byte4";
CM_ SG_ 1434 DevTx1AtPassDoorReByte5 "Development transmission 1 from the Rear Passenger door module
 Byte5";
CM_ SG_ 1434 DevTx1AtPassDoorReByte6 "Development transmission 1 from the Rear Passenger door module
 Byte6";
CM_ SG_ 1434 DevTx1AtPassDoorReByte7 "Development transmission 1 from the Rear Passenger door module
 Byte7";
CM_ SG_ 1432 DevTx2AtPassDoorByte0 "Development transmission 2 from the Passenger door module
 Byte0";
CM_ SG_ 1432 DevTx2AtPassDoorByte1 "Development transmission 2 from the Passenger door module
 Byte1";
CM_ SG_ 1432 DevTx2AtPassDoorByte2 "Development transmission 2 from the Passenger door module
 Byte2";
CM_ SG_ 1432 DevTx2AtPassDoorByte3 "Development transmission 2 from the Passenger door module
 Byte3";
CM_ SG_ 1432 DevTx2AtPassDoorByte4 "Development transmission 2 from the Passenger door module
 Byte4";
CM_ SG_ 1432 DevTx2AtPassDoorByte5 "Development transmission 2 from the Passenger door module
 Byte5";
CM_ SG_ 1432 DevTx2AtPassDoorByte6 "Development transmission 2 from the Passenger door module
 Byte6";
CM_ SG_ 1432 DevTx2AtPassDoorByte7 "Development transmission 2 from the Passenger door module
 Byte7";
CM_ SG_ 1435 DevTx2AtPassDoorReByte0 "Development transmission 2 from the Rear Passenger door module
 Byte0";
CM_ SG_ 1435 DevTx2AtPassDoorReByte1 "Development transmission 2 from the Rear Passenger door module
 Byte1";
CM_ SG_ 1435 DevTx2AtPassDoorReByte2 "Development transmission 2 from the Rear Passenger door module
 Byte2";
CM_ SG_ 1435 DevTx2AtPassDoorReByte3 "Development transmission 2 from the Rear Passenger door module
 Byte3";
CM_ SG_ 1435 DevTx2AtPassDoorReByte4 "Development transmission 2 from the Rear Passenger door module
 Byte4";
CM_ SG_ 1435 DevTx2AtPassDoorReByte5 "Development transmission 2 from the Rear Passenger door module
 Byte5";
CM_ SG_ 1435 DevTx2AtPassDoorReByte6 "Development transmission 2 from the Rear Passenger door module
 Byte6";
CM_ SG_ 1435 DevTx2AtPassDoorReByte7 "Development transmission 2 from the Rear Passenger door module
 Byte7";
CM_ SG_ 416 BodyMissComPrmntFromBoot "BodyMissComPrmntBoot - Permanent missing communication POT

";
CM_ SG_ 416 BodyMissComPrmntFromBoot_UB "Update bit for signal BodyMissComPrmntFromBoot";
CM_ SG_ 416 CurtPosnReSts "Position of the rear (not side) window sun curtain";
CM_ SG_ 416 CurtPosnReSts_UB "Update bit for signal CurtPosnReSts";
CM_ SG_ 149 TrOpenerSts_UB "Update bit for signal TrOpenerSts";
CM_ SG_ 1287 NM_AW_POT "Active Wakeup Bit, 0: Node has not woken up the network (passive wakeup), 1: Node has woken up the network (active Wakeup)";
CM_ SG_ 1287 NM_CS_POT "NM Coordinator Sleep Bit, 0: Start of synchronized shutdown is not requested by main coordinator, 1: Start of synchronized shutdown is requested by main coordinator";
CM_ SG_ 1287 NM_RMR_POT "Repeat Message Request Bit, 0: Repeat Message State not requested, 1: Repeat Message State requested";
CM_ SG_ 1287 NM_PNI_POT "Partial Network Information Bit, 0: NM message contains no Partial Network request information, 1: NM message contains Partial Network request information";
CM_ SG_ 1287 NM_NodeID_POT "Source Node Identifier";
CM_ SG_ 1450 DevRespInDrvrSeatByte0 "KOSTIA response. Supplier specific signal used for their EOL test. Not transmitted in vehicle. Byte0";
CM_ SG_ 1450 DevRespInDrvrSeatByte1 "KOSTIA response. Supplier specific signal used for their EOL test. Not transmitted in vehicle. Byte1";
CM_ SG_ 1450 DevRespInDrvrSeatByte2 "KOSTIA response. Supplier specific signal used for their EOL test. Not transmitted in vehicle. Byte2";
CM_ SG_ 1450 DevRespInDrvrSeatByte3 "KOSTIA response. Supplier specific signal used for their EOL test. Not transmitted in vehicle. Byte3";
CM_ SG_ 1450 DevRespInDrvrSeatByte4 "KOSTIA response. Supplier specific signal used for their EOL test. Not transmitted in vehicle. Byte4";
CM_ SG_ 1450 DevRespInDrvrSeatByte5 "KOSTIA response. Supplier specific signal used for their EOL test. Not transmitted in vehicle. Byte5";
CM_ SG_ 1450 DevRespInDrvrSeatByte6 "KOSTIA response. Supplier specific signal used for their EOL test. Not transmitted in vehicle. Byte6";
CM_ SG_ 1450 DevRespInDrvrSeatByte7 "KOSTIA response. Supplier specific signal used for their EOL test. Not transmitted in vehicle. Byte7";
CM_ SG_ 144 DrvrCtrlOfPassSeatFrntSts "The Remote control of passenger (Gentleman Function) seat function shall let the Driver control the Passengers power seat. The function shall be activated by entering a menu in the vehicles center stack display (Touch screen) and activate it. When the Gentleman Function is activated the adjustment switches attached to the driver side's seat ECU shall control the passenger side's seat instead of its own seat. It shall be done by sending a signal from the driver ECU to the passenger.
The Driver ECU shall receive information from subsystem HMI Management & Display whether the user has selected the Gentleman Function to be active or not. This shall be done via the signal DrvrCtrlOfPassSeatFrntReqd (Off/On). The Driver ECU shall report status of the Gentleman Function to HMI and the Passenger ECU via the signal DrvrCtrlOfPassSeatFrntSts (Not Available/Available/Deactivated/Activated).
";
CM_ SG_ 144 DrvrCtrlOfPassSeatFrntSts_UB "Update bit for signal DrvrCtrlOfPassSeatFrntSts";
CM_ SG_ 144 DrvrMassgRunng "When the massage system has been activated it will stay on for approximately 10 minutes. A signal Driver/Passenger Massage Running {On, Off} shall be send On to HMI if system running (Signal names: DrvrMassgRunng/PassMassgRunng). ";
CM_ SG_ 144 DrvrMassgRunng_UB "Update bit for signal DrvrMassgRunng";
CM_ SG_ 144 DrvrSeatActvSpplFct "The PSMD/PSMP multifunction switch consists of a 4-way adjustment switch and a 2-way integrated switch. By pressing the integrated switch up or down, the next supported seat function shall be activated. Information of which function that is currently active shall be transmitted from the seat Control subsystem ECU's via the signals DrvrSeatActvSpplFct and PassSeatActvSpplFct to the subsystem Hmi managagement & control.
";
CM_ SG_ 144 DrvrSeatActvSpplFct_UB "Update bit for signal DrvrSeatActvSpplFct";
CM_ SG_ 144 DrvrSeatBtnPsd "The signal DrvrSeatBtnPsd shall be sent when any button connected to the PSM is activated. ";
CM_ SG_ 144 DrvrSeatBtnPsd_UB "Update bit for signal DrvrSeatBtnPsd";
CM_ SG_ 144 DrvrSeatInAutMovmt "Seat Control Subsystem shall provide information to Settings Management when the seat is in movement (yes / no).

";
CM_ SG_ 144 DrvrSeatInAutMovmt_UB "Update bit for signal DrvrSeatInAutMovmt";
CM_ SG_ 144 DrvrSeatMassgFct_UB "Update bit for signal group DrvrSeatMassgFct; DrvrSeatMassgFctMassgInten DrvrSeatMassgFctMassgProg DrvrSeatMassgFctMassgSpdLvl DrvrSeatMassgFctOnOff ";
CM_ SG_ 144 DrvrSeatMassgFctMassgInten "To maneuver the driver and passenger front seat massage system the customer shall be able to access the system functions via both the so called multifunction switch on the Seat and via the IP touch screen. The DrvrSeatMassgFct/PassSeatMassgFct signal will contain data for navigating in the massage menu in the CSD. Massage program Intensity Level";
CM_ SG_ 144 DrvrSeatMassgFctMassgProg "To maneuver the driver and passenger front seat massage system the customer shall be able to access the system functions via both the so called multifunction switch on the Seat and via the IP touch screen. The DrvrSeatMassgFct/PassSeatMassgFct signal will contain data for navigating in the massage menu in the CSD. Massage Programs Types";
CM_ SG_ 144 DrvrSeatMassgFctMassgSpdLvl "To maneuver the driver and passenger front seat massage system the customer shall be able to access the system functions via both the so called multifunction switch on the Seat and via the IP touch screen. The DrvrSeatMassgFct/PassSeatMassgFct signal will contain data for navigating in the massage menu in the CSD. Massage program Speed Level";
CM_ SG_ 144 DrvrSeatMassgFctOnOff "To maneuver the driver and passenger front seat massage system the customer shall be able to access the system functions via both the so called multifunction switch on the Seat and via the IP touch screen. The DrvrSeatMassgFct/PassSeatMassgFct signal will contain data for navigating in the massage menu in the CSD. Turn on or off seat massage";
CM_ SG_ 144 DrvrSeatSwtAdjmtOfSpplFctHozlSts "The Remote control of passenger (Gentleman Function) seat function shall let the Driver control the Passengers power seat. The function shall be activated by entering a menu in the vehicles center stack display (Touch screen) and activate it. When the Gentleman Function is activated the adjustment switches attached to the driver side's seat ECU shall control the passenger side's seat instead of its own seat. It shall be done by sending a signal from the driver ECU to the passenger.

Signalgroup DrvrSeatSwtSts shall be transmitted from The Driver ECU to the Passenger ECU for control of the passenger seat.
 Driver Seat Switch Adjustment Of Supplementary Function Horizontal Status";
CM_ SG_ 144 DrvrSeatSwtAdjmtOfSpplFctVertSts "The Remote control of passenger (Gentleman Function) seat function shall let the Driver control the Passengers power seat. The function shall be activated by entering a menu in the vehicles center stack display (Touch screen) and activate it. When the Gentleman Function is activated the adjustment switches attached to the driver side's seat ECU shall control the passenger side's seat instead of its own seat. It shall be done by sending a signal from the driver ECU to the passenger.

Signalgroup DrvrSeatSwtSts shall be transmitted from The Driver ECU to the Passenger ECU for control of the passenger seat.
 Driver Seat Switch Adjustment Of Supplementary Function Vertical Status";
CM_ SG_ 144 DrvrSeatSwtHeiFrntSts "The Remote control of passenger (Gentleman Function) seat function shall let the Driver control the Passengers power seat. The function shall be activated by entering a menu in the vehicles center stack display (Touch screen) and activate it. When the Gentleman Function is activated the adjustment switches attached to the driver side's seat ECU shall control the passenger side's seat instead of its own seat. It shall be done by sending a signal from the driver ECU to the passenger.

Signalgroup DrvrSeatSwtSts shall be transmitted from The Driver ECU to the Passenger ECU for control of the passenger seat.
 Driver Seat Front Height Switch Status";
CM_ SG_ 144 DrvrSeatSwtHeiSts "The Remote control of passenger (Gentleman Function) seat function shall let the Driver control the Passengers power seat. The function shall be activated by entering a menu in the vehicles center stack display (Touch screen) and activate it. When the Gentleman Function is activated the adjustment switches attached to the driver side's seat ECU shall control the passenger side's seat instead of its own seat. It shall be done by sending a signal from the driver ECU to the passenger.

Signalgroup DrvrSeatSwtSts shall be transmitted from The Driver ECU to the Passenger ECU for control of the passenger seat.
 Driver Seat Height Switch Status";
CM_ SG_ 144 DrvrSeatSwtInclSts "The Remote control of passenger (Gentleman Function) seat function shall let the Driver control the Passengers power seat. The function shall be activated by entering a menu in the vehicles center stack display (Touch screen) and activate it. When the Gentleman Function is activated the adjustment switches attached to the driver side's seat ECU shall control the passenger side's seat instead of its own seat. It shall be done by sending a signal from the driver ECU to the passenger.

Signalgroup DrvrSeatSwtSts shall be transmitted from The Driver ECU to the Passenger ECU for control of the passenger seat.
 Driver Seat Inclination Switch Status";
CM_ SG_ 144 DrvrSeatSwtSelnOfSpplFctSts "The Remote control of passenger (Gentleman Function) seat function shall let the Driver control the Passengers power seat. The function shall be activated by entering a menu in the vehicles center stack display (Touch screen) and activate it. When the Gentleman Function is activated the adjustment switches attached to the driver side's seat ECU shall control the passenger side's seat instead of its own seat. It shall be done by sending a signal from the driver ECU to the passenger.

Signalgroup DrvrSeatSwtSts shall be transmitted from The Driver ECU to the Passenger ECU for control of the passenger seat.
 Driver Seat Switch Selection Of Supplementary Function Status";
CM_ SG_ 144 DrvrSeatSwtSldSts "The Remote control of passenger (Gentleman Function) seat function shall let the Driver control the Passengers power seat. The function shall be activated by entering a menu in the vehicles center stack display (Touch screen) and activate it. When the Gentleman Function is activated the adjustment switches attached to the driver side's seat ECU shall control the passenger side's seat instead of its own seat. It shall be done by sending a signal from the driver ECU to the passenger.

Signalgroup DrvrSeatSwtSts shall be transmitted from The Driver ECU to the Passenger ECU for control of the passenger seat.
 Driver Seat Slide Switch Status";
CM_ SG_ 144 DrvrSeatSwtSts_UB "Update bit for signal group DrvrSeatSwtSts; DrvrSeatSwtAdjmtOfSpplFctHozlSts DrvrSeatSwtAdjmtOfSpplFctVertSts DrvrSeatSwtHeiFrntSts DrvrSeatSwtHeiSts DrvrSeatSwtInclSts DrvrSeatSwtSelnOfSpplFctSts DrvrSeatSwtSldSts ";
CM_ SG_ 144 SeatBackUnlckdThrd_UB "Update bit for signal group SeatBackUnlckdThrd; SeatBackUnlckdThrdLe SeatBackUnlckdThrdRi ";
CM_ SG_ 144 SeatBackUnlckdThrdLe "Status flag from the LIN slave for third row fold function to indicate that Seat backrest is Unlocked in Unfolded position.

";
CM_ SG_ 144 SeatBackUnlckdThrdRi "Status flag from the LIN slave for third row fold function to indicate that Seat backrest is Unlocked in Unfolded position.

";
CM_ SG_ 144 SeatBlkdLe "Status flag from the LIN slave for third row fold function to indicate that Seat backrest is Blocked.";
CM_ SG_ 144 SeatBlkdRi "Status flag from the LIN slave for third row fold function to indicate that Seat backrest is Blocked.";
CM_ SG_ 144 SeatBlkdThrd_UB "Update bit for signal group SeatBlkdThrd; SeatBlkdLe SeatBlkdRi ";
CM_ SG_ 144 SeatFoldFctStsThrdGlb "Error flags from the LIN slave for third row fold function shall be merged into one error signal that shall be sent to the HMI-domain and showed in DIM ECU.
Fault types and Signals associated with each fault:

Fold switch left/right stuck.
Seatback position sensor left/right fail.
ECU internal error

The logic shall be:
SeatSwtFoldStuckLe OR SeatSwtFoldStuckRi OR SeatSnsrForInclnPosnFaildLe OR SeatSnsrForInclnPosnFaildRi OR EcuIntErrThrd = SeatFoldFctStsThrdGlb 
(Longname: Seat Fold function Status third Global)

I.e. if any of the third row fold function ECU status flag is True then the DIM shall notify the customer by a message.

Action:
Show message:
Foldable 3rd row seats Service required, 
Trigger:
When the signal SeatFoldFctStsThrdGlb is received ' True' the ECU shall show the message.
";
CM_ SG_ 144 SeatFoldFctStsThrdGlb_UB "Update bit for signal SeatFoldFctStsThrdGlb";
CM_ SG_ 1285 NM_AW_PSMD "Active Wakeup Bit, 0: Node has not woken up the network (passive wakeup), 1: Node has woken up the network (active Wakeup)";
CM_ SG_ 1285 NM_CS_PSMD "NM Coordinator Sleep Bit, 0: Start of synchronized shutdown is not requested by main coordinator, 1: Start of synchronized shutdown is requested by main coordinator";
CM_ SG_ 1285 NM_RMR_PSMD "Repeat Message Request Bit, 0: Repeat Message State not requested, 1: Repeat Message State requested";
CM_ SG_ 1285 NM_PNI_PSMD "Partial Network Information Bit, 0: NM message contains no Partial Network request information, 1: NM message contains Partial Network request information";
CM_ SG_ 1285 NM_NodeID_PSMD "Source Node Identifier";
CM_ SG_ 1504 DevRespInPassSeatByte0 "KOSTIA response. Supplier specific signal used their EOL test. Not transmitted in vehicle. Byte0";
CM_ SG_ 1504 DevRespInPassSeatByte1 "KOSTIA response. Supplier specific signal used their EOL test. Not transmitted in vehicle. Byte1";
CM_ SG_ 1504 DevRespInPassSeatByte2 "KOSTIA response. Supplier specific signal used their EOL test. Not transmitted in vehicle. Byte2";
CM_ SG_ 1504 DevRespInPassSeatByte3 "KOSTIA response. Supplier specific signal used their EOL test. Not transmitted in vehicle. Byte3";
CM_ SG_ 1504 DevRespInPassSeatByte4 "KOSTIA response. Supplier specific signal used their EOL test. Not transmitted in vehicle. Byte4";
CM_ SG_ 1504 DevRespInPassSeatByte5 "KOSTIA response. Supplier specific signal used their EOL test. Not transmitted in vehicle. Byte5";
CM_ SG_ 1504 DevRespInPassSeatByte6 "KOSTIA response. Supplier specific signal used their EOL test. Not transmitted in vehicle. Byte6";
CM_ SG_ 1504 DevRespInPassSeatByte7 "KOSTIA response. Supplier specific signal used their EOL test. Not transmitted in vehicle. Byte7";
CM_ SG_ 160 PassMassgRunng "When the massage system has been activated it will stay on for approximately 10 minutes. A signal Driver/Passenger Massage Running {On, Off} shall be send On to HMI if system running (Signal names: DrvrMassgRunng/PassMassgRunng).";
CM_ SG_ 160 PassMassgRunng_UB "Update bit for signal PassMassgRunng";
CM_ SG_ 160 PassSeatActvSpplFct "The PSMD/PSMP multifunction switch consists of a 4-way adjustment switch and a 2-way integrated switch. By pressing the integrated switch up or down, the next supported seat function shall be activated. Information of which function that is currently active shall be transmitted from the seat Control subsystem ECU's via the signals DrvrSeatActvSpplFct and PassSeatActvSpplFct to the subsystem Hmi managagement & control.
";
CM_ SG_ 160 PassSeatActvSpplFct_UB "Update bit for signal PassSeatActvSpplFct";
CM_ SG_ 160 PassSeatBtnPsd "The signal PassSeatBtnPsd shall be sent when any button connected to the PSM is activated. ";
CM_ SG_ 160 PassSeatBtnPsd_UB "Update bit for signal PassSeatBtnPsd";
CM_ SG_ 160 PassSeatInAutMovmt "Seat Control Subsystem shall provide information to Settings Management when the seat is in movement (yes / no).
";
CM_ SG_ 160 PassSeatInAutMovmt_UB "Update bit for signal PassSeatInAutMovmt";
CM_ SG_ 160 PassSeatMassgFct_UB "Update bit for signal group PassSeatMassgFct; PassSeatMassgFctMassgInten PassSeatMassgFctMassgProg PassSeatMassgFctMassgSpdLvl PassSeatMassgFctOnOff ";
CM_ SG_ 160 PassSeatMassgFctMassgInten "To maneuver the driver and passenger front seat massage system the customer shall be able to access the system functions via both the so called multifunction switch on the Seat and via the IP touch screen. The DrvrSeatMassgFct/PassSeatMassgFct signal will contain data for navigating in the massage menu in the CSD. Massage program Intensity Level";
CM_ SG_ 160 PassSeatMassgFctMassgProg "To maneuver the driver and passenger front seat massage system the customer shall be able to access the system functions via both the so called multifunction switch on the Seat and via the IP touch screen. The DrvrSeatMassgFct/PassSeatMassgFct signal will contain data for navigating in the massage menu in the CSD. Massage Programs Types";
CM_ SG_ 160 PassSeatMassgFctMassgSpdLvl "To maneuver the driver and passenger front seat massage system the customer shall be able to access the system functions via both the so called multifunction switch on the Seat and via the IP touch screen. The DrvrSeatMassgFct/PassSeatMassgFct signal will contain data for navigating in the massage menu in the CSD. Massage program Speed Level";
CM_ SG_ 160 PassSeatMassgFctOnOff "To maneuver the driver and passenger front seat massage system the customer shall be able to access the system functions via both the so called multifunction switch on the Seat and via the IP touch screen. The DrvrSeatMassgFct/PassSeatMassgFct signal will contain data for navigating in the massage menu in the CSD. Turn on or off seat massage";
CM_ SG_ 165 PassSeatSwtSts2_UB "Update bit for signal group PassSeatSwtSts2; PassSeatSwtSts2PassSeatSwtAdjmtOfSpplFctHozlSts PassSeatSwtSts2PassSeatSwtAdjmtOfSpplFctVerSts PassSeatSwtSts2PassSeatSwtHeiFrntSts PassSeatSwtSts2PassSeatSwtHeiSts PassSeatSwtSts2PassSeatSwtInclSts PassSeatSwtSts2PassSeatSwtSelnOfSpplFctStsSts PassSeatSwtSts2PassSeatSwtSldSts ";
CM_ SG_ 165 PassSeatSwtSts2PassSeatSwtAdjmtO "Passenger Seat Switch Status Passenger Seat Switch Adjustment Of Supplementary Function Horizontal Status";
CM_ SG_ 165 PassSeatSwtSts2PassSeatSwtA_0000 "Passenger Seat Switch Status Passenger Seat Switch Adjustment Of Supplementary Function Vertical Status";
CM_ SG_ 165 PassSeatSwtSts2PassSeatSwtHeiFrn "Passenger Seat Switch Status Passenger Seat Front Height Switch Status";
CM_ SG_ 165 PassSeatSwtSts2PassSeatSwtHeiSts "Passenger Seat Switch Status Passenger Seat Height Switch Status";
CM_ SG_ 165 PassSeatSwtSts2PassSeatSwtInclSt "Passenger Seat Switch Status Passenger Inclination Switch Status";
CM_ SG_ 165 PassSeatSwtSts2PassSeatSwtSelnOf "Passenger Seat Switch Status Passenger Seat Switch Selection Of Supplementary Function Status";
CM_ SG_ 165 PassSeatSwtSts2PassSeatSwtSldSts "Passenger Seat Switch Status Passenger Seat Slide Switch Status";
CM_ SG_ 1286 NM_AW_PSMP "Active Wakeup Bit, 0: Node has not woken up the network (passive wakeup), 1: Node has woken up the network (active Wakeup)";
CM_ SG_ 1286 NM_CS_PSMP "NM Coordinator Sleep Bit, 0: Start of synchronized shutdown is not requested by main coordinator, 1: Start of synchronized shutdown is requested by main coordinator";
CM_ SG_ 1286 NM_RMR_PSMP "Repeat Message Request Bit, 0: Repeat Message State not requested, 1: Repeat Message State requested";
CM_ SG_ 1286 NM_PNI_PSMP "Partial Network Information Bit, 0: NM message contains no Partial Network request information, 1: NM message contains Partial Network request information";
CM_ SG_ 1286 NM_NodeID_PSMP "Source Node Identifier";
CM_ SG_ 565 ImobVehDataRemReq0 "RVI request from TEM to CEM, 5 bytes of response and timer value. Byte nummer 0";
CM_ SG_ 565 ImobVehDataRemReq1 "RVI request from TEM to CEM, 5 bytes of response and timer value. Byte nummer 1";
CM_ SG_ 565 ImobVehDataRemReq2 "RVI request from TEM to CEM, 5 bytes of response and timer value. Byte nummer 2";
CM_ SG_ 565 ImobVehDataRemReq3 "RVI request from TEM to CEM, 5 bytes of response and timer value. Byte nummer 3";
CM_ SG_ 565 ImobVehDataRemReq4 "RVI request from TEM to CEM, 5 bytes of response and timer value. Byte nummer 4";
CM_ SG_ 565 ImobVehRemReqAndResp_UB "Update bit for signal group ImobVehRemReqAndResp; ImobVehDataRemReq0 ImobVehDataRemReq1 ImobVehDataRemReq2 ImobVehDataRemReq3 ImobVehDataRemReq4 ImobVehRemReqCmd ImobVehRemTmrOrSpdLim ";
CM_ SG_ 565 ImobVehRemReqCmd "RVI request from TEM to CEM, 5 bytes of response and timer value. Request from TEM";
CM_ SG_ 565 ImobVehRemTmrOrSpdLim "RVI request from TEM to CEM, 5 bytes of response and timer value. Time or Speed Limit";
CM_ SG_ 192 CarFindrHornLiReqFromTelm "Request signal from Telematics to activate the Car Locator Horn and Light function (FR Mobile App).";
CM_ SG_ 192 CarFindrHornLiReqFromTelm_UB "Update bit for signal CarFindrHornLiReqFromTelm";
CM_ SG_ 192 ClimaRqrd1 "Request signal from Telematics to start or stop a remote pre-climatization.";
CM_ SG_ 192 ClimaRqrd1_UB "Update bit for signal ClimaRqrd1";
CM_ SG_ 192 EmgyAsscSts "Indicates the current status of the Emergency Assistance function (VEH-FCT : 184B - Emergency Assist / MAIN; 0).";
CM_ SG_ 192 EmgyAsscSts_UB "Update bit for signal EmgyAsscSts";
CM_ SG_ 192 ErsCmdRec_UB "Update bit for signal group ErsCmdRec; ErsCmdRecErsCmd ErsCmdRecErsLeftFrontSeatHeat ErsCmdRecErsRightFrontSeatHeat ErsCmdRecErsRunTime ErsCmdRecErsSteeringWheelHeat ";
CM_ SG_ 192 ErsCmdRecErsCmd " Ers command signal";
CM_ SG_ 192 ErsCmdRecErsLeftFrontSeatHeat " Controls if left frontseat should be automatically heated or not heated at all during ERS";
CM_ SG_ 192 ErsCmdRecErsRightFrontSeatHeat " Controls if right front seat should be automatically heated or not heated at all during ERS";
CM_ SG_ 192 ErsCmdRecErsRunTime " How long time to run ERS";
CM_ SG_ 192 ErsCmdRecErsSteeringWheelHeat " Controls if steering wheel should be automatically heated or not heated at all during ERS";
CM_ SG_ 192 NetTelmActvt_UB "Update bit for signal group NetTelmActvt; NetTelmActvtPrio NetTelmActvtResourceGroup ";
CM_ SG_ 192 NetTelmActvtPrio "Network ControllerActivate:
Wakeup signal from the TEM, with the purpose of waking up other infotainment nodes when a function on that node is requested.
Bit 1: Prio high/normal
Bit 2-5: Requested function number (Function no 0-15) Prority of resource request";
CM_ SG_ 192 NetTelmActvtResourceGroup "Network ControllerActivate:
Wakeup signal from the TEM, with the purpose of waking up other infotainment nodes when a function on that node is requested.
Bit 1: Prio high/normal
Bit 2-5: Requested function number (Function no 0-15) Resource group member";
CM_ SG_ 192 RoadAsscSts "Indicates the current status of the Roadside Assistance function (VEH-FCT : 184A - Roadside Assistance / MAIN; 0).";
CM_ SG_ 192 RoadAsscSts_UB "Update bit for signal RoadAsscSts";
CM_ SG_ 192 SeatHeatDurgClimaEnadFromTelm "Request signal from Telematics to start the seat heater during a pre-climatization.";
CM_ SG_ 192 SeatHeatDurgClimaEnadFromTelm_UB "Update bit for signal SeatHeatDurgClimaEnadFromTelm";
CM_ SG_ 192 SteerWhlHeatgDurgClimaEnadFromTe "Request signal from Telematics to start the stearing wheel heater during a pre-climatization.";
CM_ SG_ 192 SteerWhlHeatgDurgClimaEnadF_0000 "Update bit for signal SteerWhlHeatgDurgClimaEnadFromTelm";
CM_ SG_ 192 TelmFctReq "Request to Vehicle Mode Management to set the vehicle in Usage Mode inactive due to a convinience telematic function need to wake up the vehicle.";
CM_ SG_ 192 TelmFctReq_UB "Update bit for signal TelmFctReq";
CM_ SG_ 192 TelmLockgCenReq "Request signal from Telematics to central lock/unlock the vehicle or to unlock via tailgate enabled. (VEH-FCT : S-83-06 Vehicle LockingUnlocking / SPA; 0) Request type";
CM_ SG_ 192 TelmLockgReq_UB "Update bit for signal group TelmLockgReq; TelmLockgCenReq UInt4 ";
CM_ SG_ 192 TelmSts "Inidactes the current telematic/subscription status and telematic system error indication.";
CM_ SG_ 192 TelmSts_UB "Update bit for signal TelmSts";
CM_ SG_ 192 UInt4 "Request signal from Telematics to central lock/unlock the vehicle or to unlock via tailgate enabled. (VEH-FCT : S-83-06 Vehicle LockingUnlocking / SPA; 0) Valid time";
CM_ SG_ 560 UkwnCptRespFromTelmByte0 "Encryption response from FCD slave ECU. Scrambled and indiscernable outside ECU. Byte0";
CM_ SG_ 560 UkwnCptRespFromTelmByte1 "Encryption response from FCD slave ECU. Scrambled and indiscernable outside ECU. Byte1";
CM_ SG_ 560 UkwnCptRespFromTelmByte2 "Encryption response from FCD slave ECU. Scrambled and indiscernable outside ECU. Byte2";
CM_ SG_ 560 UkwnCptRespFromTelmByte3 "Encryption response from FCD slave ECU. Scrambled and indiscernable outside ECU. Byte3";
CM_ SG_ 560 UkwnCptRespFromTelmByte4 "Encryption response from FCD slave ECU. Scrambled and indiscernable outside ECU. Byte4";
CM_ SG_ 560 UkwnCptRespFromTelmByte5 "Encryption response from FCD slave ECU. Scrambled and indiscernable outside ECU. Byte5";
CM_ SG_ 560 UkwnCptRespFromTelmByte6 "Encryption response from FCD slave ECU. Scrambled and indiscernable outside ECU. Byte6";
CM_ SG_ 560 UkwnCptRespFromTelmByte7 "Encryption response from FCD slave ECU. Scrambled and indiscernable outside ECU. Byte7";
CM_ SG_ 570 ClngRqrdFromTelm_UB "Update bit for signal ClngRqrdFromTelm";
CM_ SG_ 570 TelmToSecuAlrmMgrIni_UB "Update bit for signal group TelmToSecuAlrmMgrIni; TelmToSecuAlrmMgrIniMsgAuthentCod1 TelmToSecuAlrmMgrIniMsgAuthentCod2 TelmToSecuAlrmMgrIniSecuAlrmMagrToTelmIniMsgAuthentCodMsgTyp TelmToSecuAlrmMgrIniSecuIniNrRnd1 TelmToSecuAlrmMgrIniSecuIniNrRnd2 TelmToSecuAlrmMgrIniSecuIniNrRnd3 ";
CM_ SG_ 570 TelmToSecuAlrmMgrIniSecuAlrmMagr " authentication type";
CM_ SG_ 293 CryptoTelmLockgCenReq_UB "Update bit for signal group CryptoTelmLockgCenReq; CryptoTelmLockgCenReqAuthentCod CryptoTelmLockgCenReqCntr CryptoTelmLockgCenReqReqTyp CryptoTelmLockgCenReqTivld ";
CM_ SG_ 293 CryptoTelmLockgCenReqAuthentCod "A secure communication of the RDU/telematic unlock and the time its valid, including MAC and counter. MAC";
CM_ SG_ 293 CryptoTelmLockgCenReqCntr "A secure communication of the RDU/telematic unlock and the time its valid, including MAC and counter. Counter";
CM_ SG_ 293 CryptoTelmLockgCenReqReqTyp "A secure communication of the RDU/telematic unlock and the time its valid, including MAC and counter. Request type";
CM_ SG_ 293 CryptoTelmLockgCenReqTivld "A secure communication of the RDU/telematic unlock and the time its valid, including MAC and counter. Valid time";
CM_ SG_ 421 TelmChrgnTmrActvd "Charging timer on/off from TEM";
CM_ SG_ 421 TelmChrgnTmrActvd_UB "Update bit for signal TelmChrgnTmrActvd";
CM_ SG_ 421 TelmStopTiChrgnTmr "End time of a charging timer";
CM_ SG_ 421 TelmStopTiChrgnTmr_UB "Update bit for signal TelmStopTiChrgnTmr";
CM_ SG_ 423 TelmStrtTiChrgnTmr "Start time of a charging timer";
CM_ SG_ 423 TelmStrtTiChrgnTmr_UB "Update bit for signal TelmStrtTiChrgnTmr";
CM_ SG_ 1289 NM_AW_VCM "Active Wakeup Bit, 0: Node has not woken up the network (passive wakeup), 1: Node has woken up the network (active Wakeup)";
CM_ SG_ 1289 NM_CS_VCM "NM Coordinator Sleep Bit, 0: Start of synchronized shutdown is not requested by main coordinator, 1: Start of synchronized shutdown is requested by main coordinator";
CM_ SG_ 1289 NM_RMR_VCM "Repeat Message Request Bit, 0: Repeat Message State not requested, 1: Repeat Message State requested";
CM_ SG_ 1289 NM_PNI_VCM "Partial Network Information Bit, 0: NM message contains no Partial Network request information, 1: NM message contains Partial Network request information";
CM_ SG_ 1289 NM_NodeID_VCM "Source Node Identifier";
CM_ SG_ 1279 VFCVectorTEM_UB "Update bit for signal group VFCVectorTEM; VFCVectorTEMGrp1 VFCVectorTEMGrp2 VFCVectorTEMGrp3 ";
CM_ SG_ 1279 VFCVectorTEMGrp1 " VFC bit vector, VFC {0..15}";
CM_ SG_ 1279 VFCVectorTEMGrp2 " VFC bit vector, VFC{16..31}";
CM_ SG_ 1279 VFCVectorTEMGrp3 " VFC bit vector, VFC {32..47}";
CM_ SG_ 208 TrlrFogLiSts "Indicates if there is a load on the fog ligths on the trailer. If no Fog Light is present signa vill be set to Off.";
CM_ SG_ 208 TrlrFogLiSts_UB "Update bit for signal TrlrFogLiSts";
CM_ SG_ 208 TrlrIndcrLeSts "Status information about left turn indicator ";
CM_ SG_ 208 TrlrIndcrLeSts_UB "Update bit for signal TrlrIndcrLeSts";
CM_ SG_ 208 TrlrIndcrRiSts "Status information about right turn indicator ";
CM_ SG_ 208 TrlrIndcrRiSts_UB "Update bit for signal TrlrIndcrRiSts";
CM_ SG_ 208 TrlrLampActvtChk "Information to HMI,Trailer Lamp check possible/not possible to execute";
CM_ SG_ 208 TrlrLampActvtChk_UB "Update bit for signal TrlrLampActvtChk";
CM_ SG_ 208 TrlrLampChkSts "Status information about Trailer Lamp Check, (Started, Completed)";
CM_ SG_ 208 TrlrLampChkSts_UB "Update bit for signal TrlrLampChkSts";
CM_ SG_ 208 TrlrLiSts "Lamp failure information for display in HMI";
CM_ SG_ 208 TrlrLiSts_UB "Update bit for signal TrlrLiSts";
CM_ SG_ 208 TrlrPrmntPwrActv "TrlrPrmntPwrActv tells if there is a load on TrailerPermanentPowerOutput.";
CM_ SG_ 208 TrlrPrmntPwrActv_UB "Update bit for signal TrlrPrmntPwrActv";
CM_ SG_ 208 TrlrPrsnt "status containing information about if a trailer is connected to the vehicle or not";
CM_ SG_ 208 TrlrPrsnt_UB "Update bit for signal TrlrPrsnt";
CM_ SG_ 208 TrlrSrvReq "Information about system malfunction for display in HMI";
CM_ SG_ 208 TrlrSrvReq_UB "Update bit for signal TrlrSrvReq";
CM_ SG_ 208 TwbrWarnSts "Status information about retractable towbar for display in HMI";
CM_ SG_ 208 TwbrWarnSts_UB "Update bit for signal TwbrWarnSts";
CM_ SG_ 1290 NM_AW_TRM "Active Wakeup Bit, 0: Node has not woken up the network (passive wakeup), 1: Node has woken up the network (active Wakeup)";
CM_ SG_ 1290 NM_CS_TRM "NM Coordinator Sleep Bit, 0: Start of synchronized shutdown is not requested by main coordinator, 1: Start of synchronized shutdown is requested by main coordinator";
CM_ SG_ 1290 NM_RMR_TRM "Repeat Message Request Bit, 0: Repeat Message State not requested, 1: Repeat Message State requested";
CM_ SG_ 1290 NM_PNI_TRM "Partial Network Information Bit, 0: NM message contains no Partial Network request information, 1: NM message contains Partial Network request information";
CM_ SG_ 1290 NM_NodeID_TRM "Source Node Identifier";
BA_DEF_ SG_  "GenSigDataID" STRING ;
BA_DEF_ SG_  "GenSigFuncType" ENUM  "NoFunction","not-used","not-used","not-used","not-used","not-used","not-used","not-used","not-used","not-used","not-used","not-used","not-used","not-used","not-used","CHK","CNTR";
BA_DEF_ SG_  "SigGroup" STRING ;
BA_DEF_ BO_  "GenMsgILSupport" ENUM  "No","Yes";
BA_DEF_ BO_  "GenMsgCycleTimeFast" INT 0 50000;
BA_DEF_ BO_  "GenMsgSendType" ENUM  "cyclic","spontaneous","cyclicIfActive","spontaneousWithDelay","cyclicAndSpontaneous","cyclicAndSpontaneousWithDelay","not_used","not_used","not_used","cyclicWithRepeatOnDemand";
BA_DEF_ BO_  "GenMsgCycleTime" FLOAT 0 300000;
BA_DEF_ BO_  "GenMsgStartDelayTime" FLOAT 0 300000;
BA_DEF_ BO_  "GenMsgDelayTime" FLOAT 0 300000;
BA_DEF_ SG_  "GenSigSendType" ENUM  "Cyclic","OnWrite","OnWriteWithRepetition","OnChange","OnChangeWithRepetition","IfActive","IfActiveWithRepetition","NoSigSendType";
BA_DEF_ SG_  "GenSigStartValue" FLOAT -1E+019 1E+019;
BA_DEF_ SG_  "SystemSignalLongSymbol" STRING ;
BA_DEF_DEF_  "GenSigDataID" "";
BA_DEF_DEF_  "GenSigFuncType" "NoFunction";
BA_DEF_DEF_  "SigGroup" "";
BA_DEF_DEF_  "GenMsgILSupport" "Yes";
BA_DEF_DEF_  "GenMsgCycleTimeFast" 2;
BA_DEF_DEF_  "GenMsgSendType" "spontaneous";
BA_DEF_DEF_  "GenMsgCycleTime" 0;
BA_DEF_DEF_  "GenMsgStartDelayTime" 0;
BA_DEF_DEF_  "GenMsgDelayTime" 0;
BA_DEF_DEF_  "GenSigSendType" "Cyclic";
BA_DEF_DEF_  "GenSigStartValue" 0;
BA_DEF_DEF_  "SystemSignalLongSymbol" "";
BA_ "GenMsgDelayTime" BO_ 1442 10;
BA_ "GenMsgDelayTime" BO_ 1473 1000;
BA_ "GenMsgCycleTime" BO_ 1405 500;
BA_ "GenMsgCycleTime" BO_ 1406 500;
BA_ "GenMsgDelayTime" BO_ 1520 5;
BA_ "GenMsgDelayTime" BO_ 1521 5;
BA_ "GenMsgDelayTime" BO_ 1522 5;
BA_ "GenMsgDelayTime" BO_ 1523 5;
BA_ "GenMsgDelayTime" BO_ 1467 10;
BA_ "GenMsgDelayTime" BO_ 1465 10;
BA_ "GenMsgDelayTime" BO_ 1422 10;
BA_ "GenMsgDelayTime" BO_ 1420 10;
BA_ "GenMsgDelayTime" BO_ 1447 10;
BA_ "GenMsgDelayTime" BO_ 1421 10;
BA_ "GenMsgDelayTime" BO_ 1423 10;
BA_ "GenMsgDelayTime" BO_ 1439 10;
BA_ "GenMsgDelayTime" BO_ 1445 10;
BA_ "GenMsgDelayTime" BO_ 1444 10;
BA_ "GenMsgDelayTime" BO_ 1419 10;
BA_ "GenMsgDelayTime" BO_ 1418 10;
BA_ "GenMsgDelayTime" BO_ 1446 10;
BA_ "GenMsgDelayTime" BO_ 1437 10;
BA_ "GenMsgDelayTime" BO_ 1438 10;
BA_ "GenMsgDelayTime" BO_ 1448 10;
BA_ "GenMsgCycleTime" BO_ 16 10;
BA_ "GenMsgSendType" BO_ 16 0;
BA_ "GenMsgCycleTime" BO_ 352 200;
BA_ "GenMsgSendType" BO_ 352 0;
BA_ "GenMsgCycleTime" BO_ 298 150;
BA_ "GenMsgSendType" BO_ 298 0;
BA_ "GenMsgILSupport" BO_ 1284 0;
BA_ "GenMsgDelayTime" BO_ 1284 20;
BA_ "GenMsgDelayTime" BO_ 1433 10;
BA_ "GenMsgDelayTime" BO_ 1436 10;
BA_ "GenMsgDelayTime" BO_ 1431 10;
BA_ "GenMsgDelayTime" BO_ 1434 10;
BA_ "GenMsgDelayTime" BO_ 1432 10;
BA_ "GenMsgDelayTime" BO_ 1435 10;
BA_ "GenMsgDelayTime" BO_ 1555 5;
BA_ "GenMsgDelayTime" BO_ 1424 5;
BA_ "GenMsgCycleTime" BO_ 416 300;
BA_ "GenMsgSendType" BO_ 416 0;
BA_ "GenMsgCycleTime" BO_ 149 40;
BA_ "GenMsgSendType" BO_ 149 0;
BA_ "GenMsgILSupport" BO_ 1287 0;
BA_ "GenMsgDelayTime" BO_ 1287 20;
BA_ "GenMsgDelayTime" BO_ 1557 5;
BA_ "GenMsgDelayTime" BO_ 1466 10;
BA_ "GenMsgDelayTime" BO_ 1450 10;
BA_ "GenMsgCycleTime" BO_ 144 30;
BA_ "GenMsgSendType" BO_ 144 0;
BA_ "GenMsgILSupport" BO_ 1285 0;
BA_ "GenMsgDelayTime" BO_ 1285 20;
BA_ "GenMsgDelayTime" BO_ 1556 5;
BA_ "GenMsgDelayTime" BO_ 1504 10;
BA_ "GenMsgCycleTime" BO_ 160 40;
BA_ "GenMsgSendType" BO_ 160 0;
BA_ "GenMsgCycleTime" BO_ 165 40;
BA_ "GenMsgSendType" BO_ 165 0;
BA_ "GenMsgILSupport" BO_ 1286 0;
BA_ "GenMsgDelayTime" BO_ 1286 20;
BA_ "GenMsgDelayTime" BO_ 1562 5;
BA_ "GenMsgCycleTime" BO_ 565 100;
BA_ "GenMsgSendType" BO_ 565 0;
BA_ "GenMsgCycleTime" BO_ 192 50;
BA_ "GenMsgSendType" BO_ 192 0;
BA_ "GenMsgCycleTime" BO_ 560 500;
BA_ "GenMsgSendType" BO_ 560 0;
BA_ "GenMsgCycleTime" BO_ 570 600;
BA_ "GenMsgSendType" BO_ 570 0;
BA_ "GenMsgCycleTime" BO_ 293 100;
BA_ "GenMsgSendType" BO_ 293 0;
BA_ "GenMsgCycleTime" BO_ 421 300;
BA_ "GenMsgSendType" BO_ 421 0;
BA_ "GenMsgCycleTime" BO_ 423 300;
BA_ "GenMsgSendType" BO_ 423 0;
BA_ "GenMsgILSupport" BO_ 1289 0;
BA_ "GenMsgDelayTime" BO_ 1289 20;
BA_ "GenMsgCycleTime" BO_ 1279 50;
BA_ "GenMsgSendType" BO_ 1279 0;
BA_ "GenMsgCycleTime" BO_ 208 60;
BA_ "GenMsgSendType" BO_ 208 0;
BA_ "GenMsgILSupport" BO_ 1290 0;
BA_ "GenMsgDelayTime" BO_ 1290 20;
BA_ "GenMsgDelayTime" BO_ 1559 5;
BA_ "GenMsgDelayTime" BO_ 1464 10;
BA_ "SigGroup" SG_ 1442 DevReqToPassDoorReByte0 "DevReqToPassDoorRe";
BA_ "GenSigSendType" SG_ 1442 DevReqToPassDoorReByte0 3;
BA_ "SigGroup" SG_ 1442 DevReqToPassDoorReByte1 "DevReqToPassDoorRe";
BA_ "GenSigSendType" SG_ 1442 DevReqToPassDoorReByte1 3;
BA_ "SigGroup" SG_ 1442 DevReqToPassDoorReByte2 "DevReqToPassDoorRe";
BA_ "GenSigSendType" SG_ 1442 DevReqToPassDoorReByte2 3;
BA_ "SigGroup" SG_ 1442 DevReqToPassDoorReByte3 "DevReqToPassDoorRe";
BA_ "GenSigSendType" SG_ 1442 DevReqToPassDoorReByte3 3;
BA_ "SigGroup" SG_ 1442 DevReqToPassDoorReByte4 "DevReqToPassDoorRe";
BA_ "GenSigSendType" SG_ 1442 DevReqToPassDoorReByte4 3;
BA_ "SigGroup" SG_ 1442 DevReqToPassDoorReByte5 "DevReqToPassDoorRe";
BA_ "GenSigSendType" SG_ 1442 DevReqToPassDoorReByte5 3;
BA_ "SigGroup" SG_ 1442 DevReqToPassDoorReByte6 "DevReqToPassDoorRe";
BA_ "GenSigSendType" SG_ 1442 DevReqToPassDoorReByte6 3;
BA_ "SigGroup" SG_ 1442 DevReqToPassDoorReByte7 "DevReqToPassDoorRe";
BA_ "GenSigSendType" SG_ 1442 DevReqToPassDoorReByte7 3;
BA_ "SigGroup" SG_ 1473 ETCBodyDevReqToPassSeatByte0 "ETCBodyDevReqToPassSeat";
BA_ "GenSigSendType" SG_ 1473 ETCBodyDevReqToPassSeatByte0 3;
BA_ "SigGroup" SG_ 1473 ETCBodyDevReqToPassSeatByte1 "ETCBodyDevReqToPassSeat";
BA_ "GenSigSendType" SG_ 1473 ETCBodyDevReqToPassSeatByte1 3;
BA_ "SigGroup" SG_ 1473 ETCBodyDevReqToPassSeatByte2 "ETCBodyDevReqToPassSeat";
BA_ "GenSigSendType" SG_ 1473 ETCBodyDevReqToPassSeatByte2 3;
BA_ "SigGroup" SG_ 1473 ETCBodyDevReqToPassSeatByte3 "ETCBodyDevReqToPassSeat";
BA_ "GenSigSendType" SG_ 1473 ETCBodyDevReqToPassSeatByte3 3;
BA_ "SigGroup" SG_ 1473 ETCBodyDevReqToPassSeatByte4 "ETCBodyDevReqToPassSeat";
BA_ "GenSigSendType" SG_ 1473 ETCBodyDevReqToPassSeatByte4 3;
BA_ "SigGroup" SG_ 1473 ETCBodyDevReqToPassSeatByte5 "ETCBodyDevReqToPassSeat";
BA_ "GenSigSendType" SG_ 1473 ETCBodyDevReqToPassSeatByte5 3;
BA_ "SigGroup" SG_ 1473 ETCBodyDevReqToPassSeatByte6 "ETCBodyDevReqToPassSeat";
BA_ "GenSigSendType" SG_ 1473 ETCBodyDevReqToPassSeatByte6 3;
BA_ "SigGroup" SG_ 1473 ETCBodyDevReqToPassSeatByte7 "ETCBodyDevReqToPassSeat";
BA_ "GenSigSendType" SG_ 1473 ETCBodyDevReqToPassSeatByte7 3;
BA_ "GenSigSendType" SG_ 1405 IniValMstCfgIDBodyCAN 3;
BA_ "GenSigStartValue" SG_ 1405 IniValMstCfgIDBodyCAN 4105;
BA_ "GenSigSendType" SG_ 1406 IniValSigCfgIDBodyCAN 3;
BA_ "GenSigStartValue" SG_ 1406 IniValSigCfgIDBodyCAN 4105;
BA_ "SigGroup" SG_ 1422 DevDataForPrkgAssi1Byte0 "DevDataForPrkgAssi1";
BA_ "GenSigSendType" SG_ 1422 DevDataForPrkgAssi1Byte0 3;
BA_ "SigGroup" SG_ 1422 DevDataForPrkgAssi1Byte1 "DevDataForPrkgAssi1";
BA_ "GenSigSendType" SG_ 1422 DevDataForPrkgAssi1Byte1 3;
BA_ "SigGroup" SG_ 1422 DevDataForPrkgAssi1Byte2 "DevDataForPrkgAssi1";
BA_ "GenSigSendType" SG_ 1422 DevDataForPrkgAssi1Byte2 3;
BA_ "SigGroup" SG_ 1422 DevDataForPrkgAssi1Byte3 "DevDataForPrkgAssi1";
BA_ "GenSigSendType" SG_ 1422 DevDataForPrkgAssi1Byte3 3;
BA_ "SigGroup" SG_ 1422 DevDataForPrkgAssi1Byte4 "DevDataForPrkgAssi1";
BA_ "GenSigSendType" SG_ 1422 DevDataForPrkgAssi1Byte4 3;
BA_ "SigGroup" SG_ 1422 DevDataForPrkgAssi1Byte5 "DevDataForPrkgAssi1";
BA_ "GenSigSendType" SG_ 1422 DevDataForPrkgAssi1Byte5 3;
BA_ "SigGroup" SG_ 1422 DevDataForPrkgAssi1Byte6 "DevDataForPrkgAssi1";
BA_ "GenSigSendType" SG_ 1422 DevDataForPrkgAssi1Byte6 3;
BA_ "SigGroup" SG_ 1422 DevDataForPrkgAssi1Byte7 "DevDataForPrkgAssi1";
BA_ "GenSigSendType" SG_ 1422 DevDataForPrkgAssi1Byte7 3;
BA_ "SigGroup" SG_ 1420 DevDataForPrkgAssi2Byte0 "DevDataForPrkgAssi2";
BA_ "GenSigSendType" SG_ 1420 DevDataForPrkgAssi2Byte0 3;
BA_ "SigGroup" SG_ 1420 DevDataForPrkgAssi2Byte1 "DevDataForPrkgAssi2";
BA_ "GenSigSendType" SG_ 1420 DevDataForPrkgAssi2Byte1 3;
BA_ "SigGroup" SG_ 1420 DevDataForPrkgAssi2Byte2 "DevDataForPrkgAssi2";
BA_ "GenSigSendType" SG_ 1420 DevDataForPrkgAssi2Byte2 3;
BA_ "SigGroup" SG_ 1420 DevDataForPrkgAssi2Byte3 "DevDataForPrkgAssi2";
BA_ "GenSigSendType" SG_ 1420 DevDataForPrkgAssi2Byte3 3;
BA_ "SigGroup" SG_ 1420 DevDataForPrkgAssi2Byte4 "DevDataForPrkgAssi2";
BA_ "GenSigSendType" SG_ 1420 DevDataForPrkgAssi2Byte4 3;
BA_ "SigGroup" SG_ 1420 DevDataForPrkgAssi2Byte5 "DevDataForPrkgAssi2";
BA_ "GenSigSendType" SG_ 1420 DevDataForPrkgAssi2Byte5 3;
BA_ "SigGroup" SG_ 1420 DevDataForPrkgAssi2Byte6 "DevDataForPrkgAssi2";
BA_ "GenSigSendType" SG_ 1420 DevDataForPrkgAssi2Byte6 3;
BA_ "SigGroup" SG_ 1420 DevDataForPrkgAssi2Byte7 "DevDataForPrkgAssi2";
BA_ "GenSigSendType" SG_ 1420 DevDataForPrkgAssi2Byte7 3;
BA_ "SigGroup" SG_ 1447 DevDataForPrkgAssi3Byte0 "DevDataForPrkgAssi3";
BA_ "GenSigSendType" SG_ 1447 DevDataForPrkgAssi3Byte0 3;
BA_ "SigGroup" SG_ 1447 DevDataForPrkgAssi3Byte1 "DevDataForPrkgAssi3";
BA_ "GenSigSendType" SG_ 1447 DevDataForPrkgAssi3Byte1 3;
BA_ "SigGroup" SG_ 1447 DevDataForPrkgAssi3Byte2 "DevDataForPrkgAssi3";
BA_ "GenSigSendType" SG_ 1447 DevDataForPrkgAssi3Byte2 3;
BA_ "SigGroup" SG_ 1447 DevDataForPrkgAssi3Byte3 "DevDataForPrkgAssi3";
BA_ "GenSigSendType" SG_ 1447 DevDataForPrkgAssi3Byte3 3;
BA_ "SigGroup" SG_ 1447 DevDataForPrkgAssi3Byte4 "DevDataForPrkgAssi3";
BA_ "GenSigSendType" SG_ 1447 DevDataForPrkgAssi3Byte4 3;
BA_ "SigGroup" SG_ 1447 DevDataForPrkgAssi3Byte5 "DevDataForPrkgAssi3";
BA_ "GenSigSendType" SG_ 1447 DevDataForPrkgAssi3Byte5 3;
BA_ "SigGroup" SG_ 1447 DevDataForPrkgAssi3Byte6 "DevDataForPrkgAssi3";
BA_ "GenSigSendType" SG_ 1447 DevDataForPrkgAssi3Byte6 3;
BA_ "SigGroup" SG_ 1447 DevDataForPrkgAssi3Byte7 "DevDataForPrkgAssi3";
BA_ "GenSigSendType" SG_ 1447 DevDataForPrkgAssi3Byte7 3;
BA_ "SigGroup" SG_ 1421 DevDataForPrkgAssi4Byte0 "DevDataForPrkgAssi4";
BA_ "GenSigSendType" SG_ 1421 DevDataForPrkgAssi4Byte0 3;
BA_ "SigGroup" SG_ 1421 DevDataForPrkgAssi4Byte1 "DevDataForPrkgAssi4";
BA_ "GenSigSendType" SG_ 1421 DevDataForPrkgAssi4Byte1 3;
BA_ "SigGroup" SG_ 1421 DevDataForPrkgAssi4Byte2 "DevDataForPrkgAssi4";
BA_ "GenSigSendType" SG_ 1421 DevDataForPrkgAssi4Byte2 3;
BA_ "SigGroup" SG_ 1421 DevDataForPrkgAssi4Byte3 "DevDataForPrkgAssi4";
BA_ "GenSigSendType" SG_ 1421 DevDataForPrkgAssi4Byte3 3;
BA_ "SigGroup" SG_ 1421 DevDataForPrkgAssi4Byte4 "DevDataForPrkgAssi4";
BA_ "GenSigSendType" SG_ 1421 DevDataForPrkgAssi4Byte4 3;
BA_ "SigGroup" SG_ 1421 DevDataForPrkgAssi4Byte5 "DevDataForPrkgAssi4";
BA_ "GenSigSendType" SG_ 1421 DevDataForPrkgAssi4Byte5 3;
BA_ "SigGroup" SG_ 1421 DevDataForPrkgAssi4Byte6 "DevDataForPrkgAssi4";
BA_ "GenSigSendType" SG_ 1421 DevDataForPrkgAssi4Byte6 3;
BA_ "SigGroup" SG_ 1421 DevDataForPrkgAssi4Byte7 "DevDataForPrkgAssi4";
BA_ "GenSigSendType" SG_ 1421 DevDataForPrkgAssi4Byte7 3;
BA_ "SigGroup" SG_ 1423 DevDataForPrkgAssi5Byte0 "DevDataForPrkgAssi5";
BA_ "GenSigSendType" SG_ 1423 DevDataForPrkgAssi5Byte0 3;
BA_ "SigGroup" SG_ 1423 DevDataForPrkgAssi5Byte1 "DevDataForPrkgAssi5";
BA_ "GenSigSendType" SG_ 1423 DevDataForPrkgAssi5Byte1 3;
BA_ "SigGroup" SG_ 1423 DevDataForPrkgAssi5Byte2 "DevDataForPrkgAssi5";
BA_ "GenSigSendType" SG_ 1423 DevDataForPrkgAssi5Byte2 3;
BA_ "SigGroup" SG_ 1423 DevDataForPrkgAssi5Byte3 "DevDataForPrkgAssi5";
BA_ "GenSigSendType" SG_ 1423 DevDataForPrkgAssi5Byte3 3;
BA_ "SigGroup" SG_ 1423 DevDataForPrkgAssi5Byte4 "DevDataForPrkgAssi5";
BA_ "GenSigSendType" SG_ 1423 DevDataForPrkgAssi5Byte4 3;
BA_ "SigGroup" SG_ 1423 DevDataForPrkgAssi5Byte5 "DevDataForPrkgAssi5";
BA_ "GenSigSendType" SG_ 1423 DevDataForPrkgAssi5Byte5 3;
BA_ "SigGroup" SG_ 1423 DevDataForPrkgAssi5Byte6 "DevDataForPrkgAssi5";
BA_ "GenSigSendType" SG_ 1423 DevDataForPrkgAssi5Byte6 3;
BA_ "SigGroup" SG_ 1423 DevDataForPrkgAssi5Byte7 "DevDataForPrkgAssi5";
BA_ "GenSigSendType" SG_ 1423 DevDataForPrkgAssi5Byte7 3;
BA_ "SigGroup" SG_ 1439 DevDataForPrkgAssi6Byte0 "DevDataForPrkgAssi6";
BA_ "GenSigSendType" SG_ 1439 DevDataForPrkgAssi6Byte0 3;
BA_ "SigGroup" SG_ 1439 DevDataForPrkgAssi6Byte1 "DevDataForPrkgAssi6";
BA_ "GenSigSendType" SG_ 1439 DevDataForPrkgAssi6Byte1 3;
BA_ "SigGroup" SG_ 1439 DevDataForPrkgAssi6Byte2 "DevDataForPrkgAssi6";
BA_ "GenSigSendType" SG_ 1439 DevDataForPrkgAssi6Byte2 3;
BA_ "SigGroup" SG_ 1439 DevDataForPrkgAssi6Byte3 "DevDataForPrkgAssi6";
BA_ "GenSigSendType" SG_ 1439 DevDataForPrkgAssi6Byte3 3;
BA_ "SigGroup" SG_ 1439 DevDataForPrkgAssi6Byte4 "DevDataForPrkgAssi6";
BA_ "GenSigSendType" SG_ 1439 DevDataForPrkgAssi6Byte4 3;
BA_ "SigGroup" SG_ 1439 DevDataForPrkgAssi6Byte5 "DevDataForPrkgAssi6";
BA_ "GenSigSendType" SG_ 1439 DevDataForPrkgAssi6Byte5 3;
BA_ "SigGroup" SG_ 1439 DevDataForPrkgAssi6Byte6 "DevDataForPrkgAssi6";
BA_ "GenSigSendType" SG_ 1439 DevDataForPrkgAssi6Byte6 3;
BA_ "SigGroup" SG_ 1439 DevDataForPrkgAssi6Byte7 "DevDataForPrkgAssi6";
BA_ "GenSigSendType" SG_ 1439 DevDataForPrkgAssi6Byte7 3;
BA_ "SigGroup" SG_ 1445 DevDataForPrkgAssi7Byte0 "DevDataForPrkgAssi7";
BA_ "GenSigSendType" SG_ 1445 DevDataForPrkgAssi7Byte0 3;
BA_ "SigGroup" SG_ 1445 DevDataForPrkgAssi7Byte1 "DevDataForPrkgAssi7";
BA_ "GenSigSendType" SG_ 1445 DevDataForPrkgAssi7Byte1 3;
BA_ "SigGroup" SG_ 1445 DevDataForPrkgAssi7Byte2 "DevDataForPrkgAssi7";
BA_ "GenSigSendType" SG_ 1445 DevDataForPrkgAssi7Byte2 3;
BA_ "SigGroup" SG_ 1445 DevDataForPrkgAssi7Byte3 "DevDataForPrkgAssi7";
BA_ "GenSigSendType" SG_ 1445 DevDataForPrkgAssi7Byte3 3;
BA_ "SigGroup" SG_ 1445 DevDataForPrkgAssi7Byte4 "DevDataForPrkgAssi7";
BA_ "GenSigSendType" SG_ 1445 DevDataForPrkgAssi7Byte4 3;
BA_ "SigGroup" SG_ 1445 DevDataForPrkgAssi7Byte5 "DevDataForPrkgAssi7";
BA_ "GenSigSendType" SG_ 1445 DevDataForPrkgAssi7Byte5 3;
BA_ "SigGroup" SG_ 1445 DevDataForPrkgAssi7Byte6 "DevDataForPrkgAssi7";
BA_ "GenSigSendType" SG_ 1445 DevDataForPrkgAssi7Byte6 3;
BA_ "SigGroup" SG_ 1445 DevDataForPrkgAssi7Byte7 "DevDataForPrkgAssi7";
BA_ "GenSigSendType" SG_ 1445 DevDataForPrkgAssi7Byte7 3;
BA_ "SigGroup" SG_ 1444 DevDataForPrkgAssi8Byte0 "DevDataForPrkgAssi8";
BA_ "GenSigSendType" SG_ 1444 DevDataForPrkgAssi8Byte0 3;
BA_ "SigGroup" SG_ 1444 DevDataForPrkgAssi8Byte1 "DevDataForPrkgAssi8";
BA_ "GenSigSendType" SG_ 1444 DevDataForPrkgAssi8Byte1 3;
BA_ "SigGroup" SG_ 1444 DevDataForPrkgAssi8Byte2 "DevDataForPrkgAssi8";
BA_ "GenSigSendType" SG_ 1444 DevDataForPrkgAssi8Byte2 3;
BA_ "SigGroup" SG_ 1444 DevDataForPrkgAssi8Byte3 "DevDataForPrkgAssi8";
BA_ "GenSigSendType" SG_ 1444 DevDataForPrkgAssi8Byte3 3;
BA_ "SigGroup" SG_ 1444 DevDataForPrkgAssi8Byte4 "DevDataForPrkgAssi8";
BA_ "GenSigSendType" SG_ 1444 DevDataForPrkgAssi8Byte4 3;
BA_ "SigGroup" SG_ 1444 DevDataForPrkgAssi8Byte5 "DevDataForPrkgAssi8";
BA_ "GenSigSendType" SG_ 1444 DevDataForPrkgAssi8Byte5 3;
BA_ "SigGroup" SG_ 1444 DevDataForPrkgAssi8Byte6 "DevDataForPrkgAssi8";
BA_ "GenSigSendType" SG_ 1444 DevDataForPrkgAssi8Byte6 3;
BA_ "SigGroup" SG_ 1444 DevDataForPrkgAssi8Byte7 "DevDataForPrkgAssi8";
BA_ "GenSigSendType" SG_ 1444 DevDataForPrkgAssi8Byte7 3;
BA_ "SigGroup" SG_ 1419 DevDataForPrkgAssi9Byte0 "DevDataForPrkgAssi9";
BA_ "GenSigSendType" SG_ 1419 DevDataForPrkgAssi9Byte0 3;
BA_ "SigGroup" SG_ 1419 DevDataForPrkgAssi9Byte1 "DevDataForPrkgAssi9";
BA_ "GenSigSendType" SG_ 1419 DevDataForPrkgAssi9Byte1 3;
BA_ "SigGroup" SG_ 1419 DevDataForPrkgAssi9Byte2 "DevDataForPrkgAssi9";
BA_ "GenSigSendType" SG_ 1419 DevDataForPrkgAssi9Byte2 3;
BA_ "SigGroup" SG_ 1419 DevDataForPrkgAssi9Byte3 "DevDataForPrkgAssi9";
BA_ "GenSigSendType" SG_ 1419 DevDataForPrkgAssi9Byte3 3;
BA_ "SigGroup" SG_ 1419 DevDataForPrkgAssi9Byte4 "DevDataForPrkgAssi9";
BA_ "GenSigSendType" SG_ 1419 DevDataForPrkgAssi9Byte4 3;
BA_ "SigGroup" SG_ 1419 DevDataForPrkgAssi9Byte5 "DevDataForPrkgAssi9";
BA_ "GenSigSendType" SG_ 1419 DevDataForPrkgAssi9Byte5 3;
BA_ "SigGroup" SG_ 1419 DevDataForPrkgAssi9Byte6 "DevDataForPrkgAssi9";
BA_ "GenSigSendType" SG_ 1419 DevDataForPrkgAssi9Byte6 3;
BA_ "SigGroup" SG_ 1419 DevDataForPrkgAssi9Byte7 "DevDataForPrkgAssi9";
BA_ "GenSigSendType" SG_ 1419 DevDataForPrkgAssi9Byte7 3;
BA_ "SigGroup" SG_ 1418 DevDataForPrkgAssi10Byte0 "DevDataForPrkgAssi10";
BA_ "GenSigSendType" SG_ 1418 DevDataForPrkgAssi10Byte0 3;
BA_ "SigGroup" SG_ 1418 DevDataForPrkgAssi10Byte1 "DevDataForPrkgAssi10";
BA_ "GenSigSendType" SG_ 1418 DevDataForPrkgAssi10Byte1 3;
BA_ "SigGroup" SG_ 1418 DevDataForPrkgAssi10Byte2 "DevDataForPrkgAssi10";
BA_ "GenSigSendType" SG_ 1418 DevDataForPrkgAssi10Byte2 3;
BA_ "SigGroup" SG_ 1418 DevDataForPrkgAssi10Byte3 "DevDataForPrkgAssi10";
BA_ "GenSigSendType" SG_ 1418 DevDataForPrkgAssi10Byte3 3;
BA_ "SigGroup" SG_ 1418 DevDataForPrkgAssi10Byte4 "DevDataForPrkgAssi10";
BA_ "GenSigSendType" SG_ 1418 DevDataForPrkgAssi10Byte4 3;
BA_ "SigGroup" SG_ 1418 DevDataForPrkgAssi10Byte5 "DevDataForPrkgAssi10";
BA_ "GenSigSendType" SG_ 1418 DevDataForPrkgAssi10Byte5 3;
BA_ "SigGroup" SG_ 1418 DevDataForPrkgAssi10Byte6 "DevDataForPrkgAssi10";
BA_ "GenSigSendType" SG_ 1418 DevDataForPrkgAssi10Byte6 3;
BA_ "SigGroup" SG_ 1418 DevDataForPrkgAssi10Byte7 "DevDataForPrkgAssi10";
BA_ "GenSigSendType" SG_ 1418 DevDataForPrkgAssi10Byte7 3;
BA_ "SigGroup" SG_ 1446 DevDataForPrkgAssi11Byte0 "DevDataForPrkgAssi11";
BA_ "GenSigSendType" SG_ 1446 DevDataForPrkgAssi11Byte0 3;
BA_ "SigGroup" SG_ 1446 DevDataForPrkgAssi11Byte1 "DevDataForPrkgAssi11";
BA_ "GenSigSendType" SG_ 1446 DevDataForPrkgAssi11Byte1 3;
BA_ "SigGroup" SG_ 1446 DevDataForPrkgAssi11Byte2 "DevDataForPrkgAssi11";
BA_ "GenSigSendType" SG_ 1446 DevDataForPrkgAssi11Byte2 3;
BA_ "SigGroup" SG_ 1446 DevDataForPrkgAssi11Byte3 "DevDataForPrkgAssi11";
BA_ "GenSigSendType" SG_ 1446 DevDataForPrkgAssi11Byte3 3;
BA_ "SigGroup" SG_ 1446 DevDataForPrkgAssi11Byte4 "DevDataForPrkgAssi11";
BA_ "GenSigSendType" SG_ 1446 DevDataForPrkgAssi11Byte4 3;
BA_ "SigGroup" SG_ 1446 DevDataForPrkgAssi11Byte5 "DevDataForPrkgAssi11";
BA_ "GenSigSendType" SG_ 1446 DevDataForPrkgAssi11Byte5 3;
BA_ "SigGroup" SG_ 1446 DevDataForPrkgAssi11Byte6 "DevDataForPrkgAssi11";
BA_ "GenSigSendType" SG_ 1446 DevDataForPrkgAssi11Byte6 3;
BA_ "SigGroup" SG_ 1446 DevDataForPrkgAssi11Byte7 "DevDataForPrkgAssi11";
BA_ "GenSigSendType" SG_ 1446 DevDataForPrkgAssi11Byte7 3;
BA_ "SigGroup" SG_ 1437 DevDataForPrkgAssi12Byte0 "DevDataForPrkgAssi12";
BA_ "GenSigSendType" SG_ 1437 DevDataForPrkgAssi12Byte0 3;
BA_ "SigGroup" SG_ 1437 DevDataForPrkgAssi12Byte1 "DevDataForPrkgAssi12";
BA_ "GenSigSendType" SG_ 1437 DevDataForPrkgAssi12Byte1 3;
BA_ "SigGroup" SG_ 1437 DevDataForPrkgAssi12Byte2 "DevDataForPrkgAssi12";
BA_ "GenSigSendType" SG_ 1437 DevDataForPrkgAssi12Byte2 3;
BA_ "SigGroup" SG_ 1437 DevDataForPrkgAssi12Byte3 "DevDataForPrkgAssi12";
BA_ "GenSigSendType" SG_ 1437 DevDataForPrkgAssi12Byte3 3;
BA_ "SigGroup" SG_ 1437 DevDataForPrkgAssi12Byte4 "DevDataForPrkgAssi12";
BA_ "GenSigSendType" SG_ 1437 DevDataForPrkgAssi12Byte4 3;
BA_ "SigGroup" SG_ 1437 DevDataForPrkgAssi12Byte5 "DevDataForPrkgAssi12";
BA_ "GenSigSendType" SG_ 1437 DevDataForPrkgAssi12Byte5 3;
BA_ "SigGroup" SG_ 1437 DevDataForPrkgAssi12Byte6 "DevDataForPrkgAssi12";
BA_ "GenSigSendType" SG_ 1437 DevDataForPrkgAssi12Byte6 3;
BA_ "SigGroup" SG_ 1437 DevDataForPrkgAssi12Byte7 "DevDataForPrkgAssi12";
BA_ "GenSigSendType" SG_ 1437 DevDataForPrkgAssi12Byte7 3;
BA_ "SigGroup" SG_ 1438 DevDataForPrkgAssi13Byte0 "DevDataForPrkgAssi13";
BA_ "GenSigSendType" SG_ 1438 DevDataForPrkgAssi13Byte0 3;
BA_ "SigGroup" SG_ 1438 DevDataForPrkgAssi13Byte1 "DevDataForPrkgAssi13";
BA_ "GenSigSendType" SG_ 1438 DevDataForPrkgAssi13Byte1 3;
BA_ "SigGroup" SG_ 1438 DevDataForPrkgAssi13Byte2 "DevDataForPrkgAssi13";
BA_ "GenSigSendType" SG_ 1438 DevDataForPrkgAssi13Byte2 3;
BA_ "SigGroup" SG_ 1438 DevDataForPrkgAssi13Byte3 "DevDataForPrkgAssi13";
BA_ "GenSigSendType" SG_ 1438 DevDataForPrkgAssi13Byte3 3;
BA_ "SigGroup" SG_ 1438 DevDataForPrkgAssi13Byte4 "DevDataForPrkgAssi13";
BA_ "GenSigSendType" SG_ 1438 DevDataForPrkgAssi13Byte4 3;
BA_ "SigGroup" SG_ 1438 DevDataForPrkgAssi13Byte5 "DevDataForPrkgAssi13";
BA_ "GenSigSendType" SG_ 1438 DevDataForPrkgAssi13Byte5 3;
BA_ "SigGroup" SG_ 1438 DevDataForPrkgAssi13Byte6 "DevDataForPrkgAssi13";
BA_ "GenSigSendType" SG_ 1438 DevDataForPrkgAssi13Byte6 3;
BA_ "SigGroup" SG_ 1438 DevDataForPrkgAssi13Byte7 "DevDataForPrkgAssi13";
BA_ "GenSigSendType" SG_ 1438 DevDataForPrkgAssi13Byte7 3;
BA_ "SigGroup" SG_ 1448 DevDataForPrkgAssi14Byte0 "DevDataForPrkgAssi14";
BA_ "GenSigSendType" SG_ 1448 DevDataForPrkgAssi14Byte0 3;
BA_ "SigGroup" SG_ 1448 DevDataForPrkgAssi14Byte1 "DevDataForPrkgAssi14";
BA_ "GenSigSendType" SG_ 1448 DevDataForPrkgAssi14Byte1 3;
BA_ "SigGroup" SG_ 1448 DevDataForPrkgAssi14Byte2 "DevDataForPrkgAssi14";
BA_ "GenSigSendType" SG_ 1448 DevDataForPrkgAssi14Byte2 3;
BA_ "SigGroup" SG_ 1448 DevDataForPrkgAssi14Byte3 "DevDataForPrkgAssi14";
BA_ "GenSigSendType" SG_ 1448 DevDataForPrkgAssi14Byte3 3;
BA_ "SigGroup" SG_ 1448 DevDataForPrkgAssi14Byte4 "DevDataForPrkgAssi14";
BA_ "GenSigSendType" SG_ 1448 DevDataForPrkgAssi14Byte4 3;
BA_ "SigGroup" SG_ 1448 DevDataForPrkgAssi14Byte5 "DevDataForPrkgAssi14";
BA_ "GenSigSendType" SG_ 1448 DevDataForPrkgAssi14Byte5 3;
BA_ "SigGroup" SG_ 1448 DevDataForPrkgAssi14Byte6 "DevDataForPrkgAssi14";
BA_ "GenSigSendType" SG_ 1448 DevDataForPrkgAssi14Byte6 3;
BA_ "SigGroup" SG_ 1448 DevDataForPrkgAssi14Byte7 "DevDataForPrkgAssi14";
BA_ "GenSigSendType" SG_ 1448 DevDataForPrkgAssi14Byte7 3;
BA_ "GenSigStartValue" SG_ 16 ChdLockgProtnStsAtPassRe_UB 1;
BA_ "GenSigStartValue" SG_ 16 ChdWinProtnStsAtPassRe_UB 1;
BA_ "GenSigStartValue" SG_ 16 CurtReReqFromRe_UB 1;
BA_ "GenSigStartValue" SG_ 16 DoorPassLockReSts_UB 1;
BA_ "GenSigStartValue" SG_ 16 DoorPassLockSts_UB 1;
BA_ "GenSigStartValue" SG_ 16 DoorPassSwtIntrLockgReq_UB 1;
BA_ "GenSigStartValue" SG_ 16 DoorPassSwtLockgReSts_UB 1;
BA_ "GenSigStartValue" SG_ 16 LcmaLedStsPassSide_UB 1;
BA_ "GenSigStartValue" SG_ 16 MirrAtPassInMovmt_UB 1;
BA_ "GenSigStartValue" SG_ 16 MirrDwnStsAtPass_UB 1;
BA_ "GenSigStartValue" SG_ 16 MirrFoldStsAtPass_UB 1;
BA_ "GenSigStartValue" SG_ 16 PassMemBtnPsd_UB 1;
BA_ "SigGroup" SG_ 16 PassMemBtnPsdMemBtn1 "PassMemBtnPsd";
BA_ "SigGroup" SG_ 16 PassMemBtnPsdMemBtn2 "PassMemBtnPsd";
BA_ "SigGroup" SG_ 16 PassMemBtnPsdMemBtn3 "PassMemBtnPsd";
BA_ "SigGroup" SG_ 16 PassMemBtnPsdMemButM "PassMemBtnPsd";
BA_ "GenSigStartValue" SG_ 16 SunRoofAndCurtReqFromRe_UB 1;
BA_ "SigGroup" SG_ 16 SunRoofAndCurtReqFromReSunCurtRo "SunRoofAndCurtReqFromRe";
BA_ "SystemSignalLongSymbol" SG_ 16 SunRoofAndCurtReqFromReSunCurtRo "SunRoofAndCurtReqFromReSunCurtRoofReqFromRe";
BA_ "SigGroup" SG_ 16 SunRoofAndCurtReqFromReSunRoofRe "SunRoofAndCurtReqFromRe";
BA_ "SystemSignalLongSymbol" SG_ 16 SunRoofAndCurtReqFromReSunRoofRe "SunRoofAndCurtReqFromReSunRoofReqFromRe";
BA_ "GenSigStartValue" SG_ 16 WinAndCurtSwtReqReLeFromRe_UB 1;
BA_ "GenSigStartValue" SG_ 16 WinPosnStsRePass_UB 1;
BA_ "SigGroup" SG_ 352 AmbTQlyAtPassSide "AmbTRawAtPassSide";
BA_ "GenSigStartValue" SG_ 352 AmbTRawAtPassSide_UB 1;
BA_ "GenSigStartValue" SG_ 352 AmbTURawAtRiSideForObd_UB 1;
BA_ "SigGroup" SG_ 352 AmbTValAtPassSide "AmbTRawAtPassSide";
BA_ "GenSigStartValue" SG_ 352 AmbTValAtPassSide 700;
BA_ "GenSigStartValue" SG_ 352 CrashUnlckFailrStsAtPass_UB 1;
BA_ "GenSigStartValue" SG_ 352 CrashUnlckFailrStsAtPassRe_UB 1;
BA_ "GenSigStartValue" SG_ 352 DoorPassReStsOfSeatSwt_UB 1;
BA_ "SigGroup" SG_ 352 DoorPassReStsOfSeatSwtActrIncSts "DoorPassReStsOfSeatSwt";
BA_ "SigGroup" SG_ 352 DoorPassReStsOfSeatSwtActrSldSts "DoorPassReStsOfSeatSwt";
BA_ "GenSigStartValue" SG_ 352 FltOfPuddleLiPass_UB 1;
BA_ "GenSigStartValue" SG_ 352 LiPassFltIndcrTurn_UB 1;
BA_ "GenSigStartValue" SG_ 352 MirrDefrstAtPassSts_UB 1;
BA_ "GenSigStartValue" SG_ 352 WinPosnStsPass_UB 1;
BA_ "GenSigStartValue" SG_ 298 CryptoDoorPassLockCmdInin_UB 1;
BA_ "SigGroup" SG_ 298 CryptoDoorPassLockCmdIninCmdInin "CryptoDoorPassLockCmdInin";
BA_ "SystemSignalLongSymbol" SG_ 298 CryptoDoorPassLockCmdIninCmdInin "CryptoDoorPassLockCmdIninCmdInin1";
BA_ "SigGroup" SG_ 298 CryptoDoorPassLockCmdIninCm_0000 "CryptoDoorPassLockCmdInin";
BA_ "SystemSignalLongSymbol" SG_ 298 CryptoDoorPassLockCmdIninCm_0000 "CryptoDoorPassLockCmdIninCmdInin2";
BA_ "SigGroup" SG_ 298 CryptoDoorPassLockCmdIninCm_0001 "CryptoDoorPassLockCmdInin";
BA_ "SystemSignalLongSymbol" SG_ 298 CryptoDoorPassLockCmdIninCm_0001 "CryptoDoorPassLockCmdIninCmdInin3";
BA_ "GenSigStartValue" SG_ 298 CryptoDoorPassLockReCmdInin_UB 1;
BA_ "SigGroup" SG_ 298 CryptoDoorPassLockReCmdIninCmdIn "CryptoDoorPassLockReCmdInin";
BA_ "SystemSignalLongSymbol" SG_ 298 CryptoDoorPassLockReCmdIninCmdIn "CryptoDoorPassLockReCmdIninCmdInin1";
BA_ "SigGroup" SG_ 298 CryptoDoorPassLockReCmdInin_0000 "CryptoDoorPassLockReCmdInin";
BA_ "SystemSignalLongSymbol" SG_ 298 CryptoDoorPassLockReCmdInin_0000 "CryptoDoorPassLockReCmdIninCmdInin2";
BA_ "SigGroup" SG_ 298 CryptoDoorPassLockReCmdInin_0001 "CryptoDoorPassLockReCmdInin";
BA_ "SystemSignalLongSymbol" SG_ 298 CryptoDoorPassLockReCmdInin_0001 "CryptoDoorPassLockReCmdIninCmdInin3";
BA_ "SigGroup" SG_ 1433 DevRespAtPassDoorByte0 "DevRespAtPassDoor";
BA_ "GenSigSendType" SG_ 1433 DevRespAtPassDoorByte0 3;
BA_ "SigGroup" SG_ 1433 DevRespAtPassDoorByte1 "DevRespAtPassDoor";
BA_ "GenSigSendType" SG_ 1433 DevRespAtPassDoorByte1 3;
BA_ "SigGroup" SG_ 1433 DevRespAtPassDoorByte2 "DevRespAtPassDoor";
BA_ "GenSigSendType" SG_ 1433 DevRespAtPassDoorByte2 3;
BA_ "SigGroup" SG_ 1433 DevRespAtPassDoorByte3 "DevRespAtPassDoor";
BA_ "GenSigSendType" SG_ 1433 DevRespAtPassDoorByte3 3;
BA_ "SigGroup" SG_ 1433 DevRespAtPassDoorByte4 "DevRespAtPassDoor";
BA_ "GenSigSendType" SG_ 1433 DevRespAtPassDoorByte4 3;
BA_ "SigGroup" SG_ 1433 DevRespAtPassDoorByte5 "DevRespAtPassDoor";
BA_ "GenSigSendType" SG_ 1433 DevRespAtPassDoorByte5 3;
BA_ "SigGroup" SG_ 1433 DevRespAtPassDoorByte6 "DevRespAtPassDoor";
BA_ "GenSigSendType" SG_ 1433 DevRespAtPassDoorByte6 3;
BA_ "SigGroup" SG_ 1433 DevRespAtPassDoorByte7 "DevRespAtPassDoor";
BA_ "GenSigSendType" SG_ 1433 DevRespAtPassDoorByte7 3;
BA_ "SigGroup" SG_ 1436 DevRespAtPassDoorReByte0 "DevRespAtPassDoorRe";
BA_ "GenSigSendType" SG_ 1436 DevRespAtPassDoorReByte0 3;
BA_ "SigGroup" SG_ 1436 DevRespAtPassDoorReByte1 "DevRespAtPassDoorRe";
BA_ "GenSigSendType" SG_ 1436 DevRespAtPassDoorReByte1 3;
BA_ "SigGroup" SG_ 1436 DevRespAtPassDoorReByte2 "DevRespAtPassDoorRe";
BA_ "GenSigSendType" SG_ 1436 DevRespAtPassDoorReByte2 3;
BA_ "SigGroup" SG_ 1436 DevRespAtPassDoorReByte3 "DevRespAtPassDoorRe";
BA_ "GenSigSendType" SG_ 1436 DevRespAtPassDoorReByte3 3;
BA_ "SigGroup" SG_ 1436 DevRespAtPassDoorReByte4 "DevRespAtPassDoorRe";
BA_ "GenSigSendType" SG_ 1436 DevRespAtPassDoorReByte4 3;
BA_ "SigGroup" SG_ 1436 DevRespAtPassDoorReByte5 "DevRespAtPassDoorRe";
BA_ "GenSigSendType" SG_ 1436 DevRespAtPassDoorReByte5 3;
BA_ "SigGroup" SG_ 1436 DevRespAtPassDoorReByte6 "DevRespAtPassDoorRe";
BA_ "GenSigSendType" SG_ 1436 DevRespAtPassDoorReByte6 3;
BA_ "SigGroup" SG_ 1436 DevRespAtPassDoorReByte7 "DevRespAtPassDoorRe";
BA_ "GenSigSendType" SG_ 1436 DevRespAtPassDoorReByte7 3;
BA_ "SigGroup" SG_ 1431 DevTx1AtPassDoorByte0 "DevTx1AtPassDoor";
BA_ "GenSigSendType" SG_ 1431 DevTx1AtPassDoorByte0 3;
BA_ "SigGroup" SG_ 1431 DevTx1AtPassDoorByte1 "DevTx1AtPassDoor";
BA_ "GenSigSendType" SG_ 1431 DevTx1AtPassDoorByte1 3;
BA_ "SigGroup" SG_ 1431 DevTx1AtPassDoorByte2 "DevTx1AtPassDoor";
BA_ "GenSigSendType" SG_ 1431 DevTx1AtPassDoorByte2 3;
BA_ "SigGroup" SG_ 1431 DevTx1AtPassDoorByte3 "DevTx1AtPassDoor";
BA_ "GenSigSendType" SG_ 1431 DevTx1AtPassDoorByte3 3;
BA_ "SigGroup" SG_ 1431 DevTx1AtPassDoorByte4 "DevTx1AtPassDoor";
BA_ "GenSigSendType" SG_ 1431 DevTx1AtPassDoorByte4 3;
BA_ "SigGroup" SG_ 1431 DevTx1AtPassDoorByte5 "DevTx1AtPassDoor";
BA_ "GenSigSendType" SG_ 1431 DevTx1AtPassDoorByte5 3;
BA_ "SigGroup" SG_ 1431 DevTx1AtPassDoorByte6 "DevTx1AtPassDoor";
BA_ "GenSigSendType" SG_ 1431 DevTx1AtPassDoorByte6 3;
BA_ "SigGroup" SG_ 1431 DevTx1AtPassDoorByte7 "DevTx1AtPassDoor";
BA_ "GenSigSendType" SG_ 1431 DevTx1AtPassDoorByte7 3;
BA_ "SigGroup" SG_ 1434 DevTx1AtPassDoorReByte0 "DevTx1AtPassDoorRe";
BA_ "GenSigSendType" SG_ 1434 DevTx1AtPassDoorReByte0 3;
BA_ "SigGroup" SG_ 1434 DevTx1AtPassDoorReByte1 "DevTx1AtPassDoorRe";
BA_ "GenSigSendType" SG_ 1434 DevTx1AtPassDoorReByte1 3;
BA_ "SigGroup" SG_ 1434 DevTx1AtPassDoorReByte2 "DevTx1AtPassDoorRe";
BA_ "GenSigSendType" SG_ 1434 DevTx1AtPassDoorReByte2 3;
BA_ "SigGroup" SG_ 1434 DevTx1AtPassDoorReByte3 "DevTx1AtPassDoorRe";
BA_ "GenSigSendType" SG_ 1434 DevTx1AtPassDoorReByte3 3;
BA_ "SigGroup" SG_ 1434 DevTx1AtPassDoorReByte4 "DevTx1AtPassDoorRe";
BA_ "GenSigSendType" SG_ 1434 DevTx1AtPassDoorReByte4 3;
BA_ "SigGroup" SG_ 1434 DevTx1AtPassDoorReByte5 "DevTx1AtPassDoorRe";
BA_ "GenSigSendType" SG_ 1434 DevTx1AtPassDoorReByte5 3;
BA_ "SigGroup" SG_ 1434 DevTx1AtPassDoorReByte6 "DevTx1AtPassDoorRe";
BA_ "GenSigSendType" SG_ 1434 DevTx1AtPassDoorReByte6 3;
BA_ "SigGroup" SG_ 1434 DevTx1AtPassDoorReByte7 "DevTx1AtPassDoorRe";
BA_ "GenSigSendType" SG_ 1434 DevTx1AtPassDoorReByte7 3;
BA_ "SigGroup" SG_ 1432 DevTx2AtPassDoorByte0 "DevTx2AtPassDoor";
BA_ "GenSigSendType" SG_ 1432 DevTx2AtPassDoorByte0 3;
BA_ "SigGroup" SG_ 1432 DevTx2AtPassDoorByte1 "DevTx2AtPassDoor";
BA_ "GenSigSendType" SG_ 1432 DevTx2AtPassDoorByte1 3;
BA_ "SigGroup" SG_ 1432 DevTx2AtPassDoorByte2 "DevTx2AtPassDoor";
BA_ "GenSigSendType" SG_ 1432 DevTx2AtPassDoorByte2 3;
BA_ "SigGroup" SG_ 1432 DevTx2AtPassDoorByte3 "DevTx2AtPassDoor";
BA_ "GenSigSendType" SG_ 1432 DevTx2AtPassDoorByte3 3;
BA_ "SigGroup" SG_ 1432 DevTx2AtPassDoorByte4 "DevTx2AtPassDoor";
BA_ "GenSigSendType" SG_ 1432 DevTx2AtPassDoorByte4 3;
BA_ "SigGroup" SG_ 1432 DevTx2AtPassDoorByte5 "DevTx2AtPassDoor";
BA_ "GenSigSendType" SG_ 1432 DevTx2AtPassDoorByte5 3;
BA_ "SigGroup" SG_ 1432 DevTx2AtPassDoorByte6 "DevTx2AtPassDoor";
BA_ "GenSigSendType" SG_ 1432 DevTx2AtPassDoorByte6 3;
BA_ "SigGroup" SG_ 1432 DevTx2AtPassDoorByte7 "DevTx2AtPassDoor";
BA_ "GenSigSendType" SG_ 1432 DevTx2AtPassDoorByte7 3;
BA_ "SigGroup" SG_ 1435 DevTx2AtPassDoorReByte0 "DevTx2AtPassDoorRe";
BA_ "GenSigSendType" SG_ 1435 DevTx2AtPassDoorReByte0 3;
BA_ "SigGroup" SG_ 1435 DevTx2AtPassDoorReByte1 "DevTx2AtPassDoorRe";
BA_ "GenSigSendType" SG_ 1435 DevTx2AtPassDoorReByte1 3;
BA_ "SigGroup" SG_ 1435 DevTx2AtPassDoorReByte2 "DevTx2AtPassDoorRe";
BA_ "GenSigSendType" SG_ 1435 DevTx2AtPassDoorReByte2 3;
BA_ "SigGroup" SG_ 1435 DevTx2AtPassDoorReByte3 "DevTx2AtPassDoorRe";
BA_ "GenSigSendType" SG_ 1435 DevTx2AtPassDoorReByte3 3;
BA_ "SigGroup" SG_ 1435 DevTx2AtPassDoorReByte4 "DevTx2AtPassDoorRe";
BA_ "GenSigSendType" SG_ 1435 DevTx2AtPassDoorReByte4 3;
BA_ "SigGroup" SG_ 1435 DevTx2AtPassDoorReByte5 "DevTx2AtPassDoorRe";
BA_ "GenSigSendType" SG_ 1435 DevTx2AtPassDoorReByte5 3;
BA_ "SigGroup" SG_ 1435 DevTx2AtPassDoorReByte6 "DevTx2AtPassDoorRe";
BA_ "GenSigSendType" SG_ 1435 DevTx2AtPassDoorReByte6 3;
BA_ "SigGroup" SG_ 1435 DevTx2AtPassDoorReByte7 "DevTx2AtPassDoorRe";
BA_ "GenSigSendType" SG_ 1435 DevTx2AtPassDoorReByte7 3;
BA_ "GenSigStartValue" SG_ 416 BodyMissComPrmntFromBoot_UB 1;
BA_ "GenSigStartValue" SG_ 416 CurtPosnReSts_UB 1;
BA_ "GenSigStartValue" SG_ 149 TrOpenerSts_UB 1;
BA_ "SigGroup" SG_ 1450 DevRespInDrvrSeatByte0 "DevRespInDrvrSeat";
BA_ "GenSigSendType" SG_ 1450 DevRespInDrvrSeatByte0 3;
BA_ "SigGroup" SG_ 1450 DevRespInDrvrSeatByte1 "DevRespInDrvrSeat";
BA_ "GenSigSendType" SG_ 1450 DevRespInDrvrSeatByte1 3;
BA_ "SigGroup" SG_ 1450 DevRespInDrvrSeatByte2 "DevRespInDrvrSeat";
BA_ "GenSigSendType" SG_ 1450 DevRespInDrvrSeatByte2 3;
BA_ "SigGroup" SG_ 1450 DevRespInDrvrSeatByte3 "DevRespInDrvrSeat";
BA_ "GenSigSendType" SG_ 1450 DevRespInDrvrSeatByte3 3;
BA_ "SigGroup" SG_ 1450 DevRespInDrvrSeatByte4 "DevRespInDrvrSeat";
BA_ "GenSigSendType" SG_ 1450 DevRespInDrvrSeatByte4 3;
BA_ "SigGroup" SG_ 1450 DevRespInDrvrSeatByte5 "DevRespInDrvrSeat";
BA_ "GenSigSendType" SG_ 1450 DevRespInDrvrSeatByte5 3;
BA_ "SigGroup" SG_ 1450 DevRespInDrvrSeatByte6 "DevRespInDrvrSeat";
BA_ "GenSigSendType" SG_ 1450 DevRespInDrvrSeatByte6 3;
BA_ "SigGroup" SG_ 1450 DevRespInDrvrSeatByte7 "DevRespInDrvrSeat";
BA_ "GenSigSendType" SG_ 1450 DevRespInDrvrSeatByte7 3;
BA_ "GenSigStartValue" SG_ 144 DrvrCtrlOfPassSeatFrntSts_UB 1;
BA_ "GenSigStartValue" SG_ 144 DrvrMassgRunng_UB 1;
BA_ "GenSigStartValue" SG_ 144 DrvrSeatActvSpplFct_UB 1;
BA_ "GenSigStartValue" SG_ 144 DrvrSeatBtnPsd_UB 1;
BA_ "GenSigStartValue" SG_ 144 DrvrSeatInAutMovmt_UB 1;
BA_ "GenSigStartValue" SG_ 144 DrvrSeatMassgFct_UB 1;
BA_ "SigGroup" SG_ 144 DrvrSeatMassgFctMassgInten "DrvrSeatMassgFct";
BA_ "GenSigStartValue" SG_ 144 DrvrSeatMassgFctMassgInten 1;
BA_ "SigGroup" SG_ 144 DrvrSeatMassgFctMassgProg "DrvrSeatMassgFct";
BA_ "SigGroup" SG_ 144 DrvrSeatMassgFctMassgSpdLvl "DrvrSeatMassgFct";
BA_ "GenSigStartValue" SG_ 144 DrvrSeatMassgFctMassgSpdLvl 1;
BA_ "SigGroup" SG_ 144 DrvrSeatMassgFctOnOff "DrvrSeatMassgFct";
BA_ "SigGroup" SG_ 144 DrvrSeatSwtAdjmtOfSpplFctHozlSts "DrvrSeatSwtSts";
BA_ "SigGroup" SG_ 144 DrvrSeatSwtAdjmtOfSpplFctVertSts "DrvrSeatSwtSts";
BA_ "SigGroup" SG_ 144 DrvrSeatSwtHeiFrntSts "DrvrSeatSwtSts";
BA_ "SigGroup" SG_ 144 DrvrSeatSwtHeiSts "DrvrSeatSwtSts";
BA_ "SigGroup" SG_ 144 DrvrSeatSwtInclSts "DrvrSeatSwtSts";
BA_ "SigGroup" SG_ 144 DrvrSeatSwtSelnOfSpplFctSts "DrvrSeatSwtSts";
BA_ "SigGroup" SG_ 144 DrvrSeatSwtSldSts "DrvrSeatSwtSts";
BA_ "GenSigStartValue" SG_ 144 DrvrSeatSwtSts_UB 1;
BA_ "GenSigStartValue" SG_ 144 SeatBackUnlckdThrd_UB 1;
BA_ "SigGroup" SG_ 144 SeatBackUnlckdThrdLe "SeatBackUnlckdThrd";
BA_ "SigGroup" SG_ 144 SeatBackUnlckdThrdRi "SeatBackUnlckdThrd";
BA_ "SigGroup" SG_ 144 SeatBlkdLe "SeatBlkdThrd";
BA_ "SigGroup" SG_ 144 SeatBlkdRi "SeatBlkdThrd";
BA_ "GenSigStartValue" SG_ 144 SeatBlkdThrd_UB 1;
BA_ "GenSigStartValue" SG_ 144 SeatFoldFctStsThrdGlb_UB 1;
BA_ "SigGroup" SG_ 1504 DevRespInPassSeatByte0 "DevRespInPassSeat";
BA_ "GenSigSendType" SG_ 1504 DevRespInPassSeatByte0 3;
BA_ "SigGroup" SG_ 1504 DevRespInPassSeatByte1 "DevRespInPassSeat";
BA_ "GenSigSendType" SG_ 1504 DevRespInPassSeatByte1 3;
BA_ "SigGroup" SG_ 1504 DevRespInPassSeatByte2 "DevRespInPassSeat";
BA_ "GenSigSendType" SG_ 1504 DevRespInPassSeatByte2 3;
BA_ "SigGroup" SG_ 1504 DevRespInPassSeatByte3 "DevRespInPassSeat";
BA_ "GenSigSendType" SG_ 1504 DevRespInPassSeatByte3 3;
BA_ "SigGroup" SG_ 1504 DevRespInPassSeatByte4 "DevRespInPassSeat";
BA_ "GenSigSendType" SG_ 1504 DevRespInPassSeatByte4 3;
BA_ "SigGroup" SG_ 1504 DevRespInPassSeatByte5 "DevRespInPassSeat";
BA_ "GenSigSendType" SG_ 1504 DevRespInPassSeatByte5 3;
BA_ "SigGroup" SG_ 1504 DevRespInPassSeatByte6 "DevRespInPassSeat";
BA_ "GenSigSendType" SG_ 1504 DevRespInPassSeatByte6 3;
BA_ "SigGroup" SG_ 1504 DevRespInPassSeatByte7 "DevRespInPassSeat";
BA_ "GenSigSendType" SG_ 1504 DevRespInPassSeatByte7 3;
BA_ "GenSigStartValue" SG_ 160 PassMassgRunng_UB 1;
BA_ "GenSigStartValue" SG_ 160 PassSeatActvSpplFct_UB 1;
BA_ "GenSigStartValue" SG_ 160 PassSeatBtnPsd_UB 1;
BA_ "GenSigStartValue" SG_ 160 PassSeatInAutMovmt_UB 1;
BA_ "GenSigStartValue" SG_ 160 PassSeatMassgFct_UB 1;
BA_ "SigGroup" SG_ 160 PassSeatMassgFctMassgInten "PassSeatMassgFct";
BA_ "GenSigStartValue" SG_ 160 PassSeatMassgFctMassgInten 1;
BA_ "SigGroup" SG_ 160 PassSeatMassgFctMassgProg "PassSeatMassgFct";
BA_ "SigGroup" SG_ 160 PassSeatMassgFctMassgSpdLvl "PassSeatMassgFct";
BA_ "GenSigStartValue" SG_ 160 PassSeatMassgFctMassgSpdLvl 1;
BA_ "SigGroup" SG_ 160 PassSeatMassgFctOnOff "PassSeatMassgFct";
BA_ "GenSigStartValue" SG_ 165 PassSeatSwtSts2_UB 1;
BA_ "SigGroup" SG_ 165 PassSeatSwtSts2PassSeatSwtAdjmtO "PassSeatSwtSts2";
BA_ "SystemSignalLongSymbol" SG_ 165 PassSeatSwtSts2PassSeatSwtAdjmtO "PassSeatSwtSts2PassSeatSwtAdjmtOfSpplFctHozlSts";
BA_ "SigGroup" SG_ 165 PassSeatSwtSts2PassSeatSwtA_0000 "PassSeatSwtSts2";
BA_ "SystemSignalLongSymbol" SG_ 165 PassSeatSwtSts2PassSeatSwtA_0000 "PassSeatSwtSts2PassSeatSwtAdjmtOfSpplFctVerSts";
BA_ "SigGroup" SG_ 165 PassSeatSwtSts2PassSeatSwtHeiFrn "PassSeatSwtSts2";
BA_ "SystemSignalLongSymbol" SG_ 165 PassSeatSwtSts2PassSeatSwtHeiFrn "PassSeatSwtSts2PassSeatSwtHeiFrntSts";
BA_ "SigGroup" SG_ 165 PassSeatSwtSts2PassSeatSwtHeiSts "PassSeatSwtSts2";
BA_ "SigGroup" SG_ 165 PassSeatSwtSts2PassSeatSwtInclSt "PassSeatSwtSts2";
BA_ "SystemSignalLongSymbol" SG_ 165 PassSeatSwtSts2PassSeatSwtInclSt "PassSeatSwtSts2PassSeatSwtInclSts";
BA_ "SigGroup" SG_ 165 PassSeatSwtSts2PassSeatSwtSelnOf "PassSeatSwtSts2";
BA_ "SystemSignalLongSymbol" SG_ 165 PassSeatSwtSts2PassSeatSwtSelnOf "PassSeatSwtSts2PassSeatSwtSelnOfSpplFctStsSts";
BA_ "SigGroup" SG_ 165 PassSeatSwtSts2PassSeatSwtSldSts "PassSeatSwtSts2";
BA_ "SigGroup" SG_ 565 ImobVehDataRemReq0 "ImobVehRemReqAndResp";
BA_ "SigGroup" SG_ 565 ImobVehDataRemReq1 "ImobVehRemReqAndResp";
BA_ "SigGroup" SG_ 565 ImobVehDataRemReq2 "ImobVehRemReqAndResp";
BA_ "SigGroup" SG_ 565 ImobVehDataRemReq3 "ImobVehRemReqAndResp";
BA_ "SigGroup" SG_ 565 ImobVehDataRemReq4 "ImobVehRemReqAndResp";
BA_ "GenSigStartValue" SG_ 565 ImobVehRemReqAndResp_UB 1;
BA_ "SigGroup" SG_ 565 ImobVehRemReqCmd "ImobVehRemReqAndResp";
BA_ "SigGroup" SG_ 565 ImobVehRemTmrOrSpdLim "ImobVehRemReqAndResp";
BA_ "GenSigStartValue" SG_ 192 CarFindrHornLiReqFromTelm_UB 1;
BA_ "GenSigStartValue" SG_ 192 ClimaRqrd1_UB 1;
BA_ "GenSigStartValue" SG_ 192 EmgyAsscSts_UB 1;
BA_ "GenSigStartValue" SG_ 192 ErsCmdRec_UB 1;
BA_ "SigGroup" SG_ 192 ErsCmdRecErsCmd "ErsCmdRec";
BA_ "SigGroup" SG_ 192 ErsCmdRecErsLeftFrontSeatHeat "ErsCmdRec";
BA_ "SigGroup" SG_ 192 ErsCmdRecErsRightFrontSeatHeat "ErsCmdRec";
BA_ "SigGroup" SG_ 192 ErsCmdRecErsRunTime "ErsCmdRec";
BA_ "SigGroup" SG_ 192 ErsCmdRecErsSteeringWheelHeat "ErsCmdRec";
BA_ "GenSigStartValue" SG_ 192 NetTelmActvt_UB 1;
BA_ "SigGroup" SG_ 192 NetTelmActvtPrio "NetTelmActvt";
BA_ "SigGroup" SG_ 192 NetTelmActvtResourceGroup "NetTelmActvt";
BA_ "GenSigStartValue" SG_ 192 RoadAsscSts_UB 1;
BA_ "GenSigStartValue" SG_ 192 SeatHeatDurgClimaEnadFromTelm_UB 1;
BA_ "SystemSignalLongSymbol" SG_ 192 SteerWhlHeatgDurgClimaEnadFromTe "SteerWhlHeatgDurgClimaEnadFromTelm";
BA_ "GenSigStartValue" SG_ 192 SteerWhlHeatgDurgClimaEnadF_0000 1;
BA_ "SystemSignalLongSymbol" SG_ 192 SteerWhlHeatgDurgClimaEnadF_0000 "SteerWhlHeatgDurgClimaEnadFromTelm_UB";
BA_ "GenSigStartValue" SG_ 192 TelmFctReq_UB 1;
BA_ "SigGroup" SG_ 192 TelmLockgCenReq "TelmLockgReq";
BA_ "GenSigStartValue" SG_ 192 TelmLockgReq_UB 1;
BA_ "GenSigStartValue" SG_ 192 TelmSts_UB 1;
BA_ "SigGroup" SG_ 192 UInt4 "TelmLockgReq";
BA_ "SigGroup" SG_ 560 UkwnCptRespFromTelmByte0 "UkwnCptRespFromTelm";
BA_ "SigGroup" SG_ 560 UkwnCptRespFromTelmByte1 "UkwnCptRespFromTelm";
BA_ "SigGroup" SG_ 560 UkwnCptRespFromTelmByte2 "UkwnCptRespFromTelm";
BA_ "SigGroup" SG_ 560 UkwnCptRespFromTelmByte3 "UkwnCptRespFromTelm";
BA_ "SigGroup" SG_ 560 UkwnCptRespFromTelmByte4 "UkwnCptRespFromTelm";
BA_ "SigGroup" SG_ 560 UkwnCptRespFromTelmByte5 "UkwnCptRespFromTelm";
BA_ "SigGroup" SG_ 560 UkwnCptRespFromTelmByte6 "UkwnCptRespFromTelm";
BA_ "SigGroup" SG_ 560 UkwnCptRespFromTelmByte7 "UkwnCptRespFromTelm";
BA_ "GenSigStartValue" SG_ 570 ClngRqrdFromTelm_UB 1;
BA_ "GenSigStartValue" SG_ 570 TelmToSecuAlrmMgrIni_UB 1;
BA_ "SigGroup" SG_ 570 TelmToSecuAlrmMgrIniMsgAuthentCo "TelmToSecuAlrmMgrIni";
BA_ "SystemSignalLongSymbol" SG_ 570 TelmToSecuAlrmMgrIniMsgAuthentCo "TelmToSecuAlrmMgrIniMsgAuthentCod1";
BA_ "SigGroup" SG_ 570 TelmToSecuAlrmMgrIniMsgAuth_0000 "TelmToSecuAlrmMgrIni";
BA_ "SystemSignalLongSymbol" SG_ 570 TelmToSecuAlrmMgrIniMsgAuth_0000 "TelmToSecuAlrmMgrIniMsgAuthentCod2";
BA_ "SigGroup" SG_ 570 TelmToSecuAlrmMgrIniSecuAlrmMagr "TelmToSecuAlrmMgrIni";
BA_ "SystemSignalLongSymbol" SG_ 570 TelmToSecuAlrmMgrIniSecuAlrmMagr "TelmToSecuAlrmMgrIniSecuAlrmMagrToTelmIniMsgAuthentCodMsgTyp";
BA_ "SigGroup" SG_ 570 TelmToSecuAlrmMgrIniSecuIniNrRnd "TelmToSecuAlrmMgrIni";
BA_ "SystemSignalLongSymbol" SG_ 570 TelmToSecuAlrmMgrIniSecuIniNrRnd "TelmToSecuAlrmMgrIniSecuIniNrRnd1";
BA_ "SigGroup" SG_ 570 TelmToSecuAlrmMgrIniSecuIni_0000 "TelmToSecuAlrmMgrIni";
BA_ "SystemSignalLongSymbol" SG_ 570 TelmToSecuAlrmMgrIniSecuIni_0000 "TelmToSecuAlrmMgrIniSecuIniNrRnd2";
BA_ "SigGroup" SG_ 570 TelmToSecuAlrmMgrIniSecuIni_0001 "TelmToSecuAlrmMgrIni";
BA_ "SystemSignalLongSymbol" SG_ 570 TelmToSecuAlrmMgrIniSecuIni_0001 "TelmToSecuAlrmMgrIniSecuIniNrRnd3";
BA_ "GenSigStartValue" SG_ 293 CryptoTelmLockgCenReq_UB 1;
BA_ "SigGroup" SG_ 293 CryptoTelmLockgCenReqAuthentCod "CryptoTelmLockgCenReq";
BA_ "SigGroup" SG_ 293 CryptoTelmLockgCenReqCntr "CryptoTelmLockgCenReq";
BA_ "GenSigStartValue" SG_ 293 CryptoTelmLockgCenReqCntr 65535;
BA_ "SigGroup" SG_ 293 CryptoTelmLockgCenReqReqTyp "CryptoTelmLockgCenReq";
BA_ "SigGroup" SG_ 293 CryptoTelmLockgCenReqTivld "CryptoTelmLockgCenReq";
BA_ "GenSigStartValue" SG_ 421 TelmChrgnTmrActvd_UB 1;
BA_ "GenSigStartValue" SG_ 421 TelmStopTiChrgnTmr_UB 1;
BA_ "GenSigStartValue" SG_ 423 TelmStrtTiChrgnTmr_UB 1;
BA_ "GenSigStartValue" SG_ 1279 VFCVectorTEM_UB 1;
BA_ "SigGroup" SG_ 1279 VFCVectorTEMGrp1 "VFCVectorTEM";
BA_ "SigGroup" SG_ 1279 VFCVectorTEMGrp2 "VFCVectorTEM";
BA_ "SigGroup" SG_ 1279 VFCVectorTEMGrp3 "VFCVectorTEM";
BA_ "GenSigStartValue" SG_ 208 TrlrFogLiSts 1;
BA_ "GenSigStartValue" SG_ 208 TrlrFogLiSts_UB 1;
BA_ "GenSigStartValue" SG_ 208 TrlrIndcrLeSts_UB 1;
BA_ "GenSigStartValue" SG_ 208 TrlrIndcrRiSts_UB 1;
BA_ "GenSigStartValue" SG_ 208 TrlrLampActvtChk_UB 1;
BA_ "GenSigStartValue" SG_ 208 TrlrLampChkSts_UB 1;
BA_ "GenSigStartValue" SG_ 208 TrlrLiSts_UB 1;
BA_ "GenSigStartValue" SG_ 208 TrlrPrmntPwrActv 1;
BA_ "GenSigStartValue" SG_ 208 TrlrPrmntPwrActv_UB 1;
BA_ "GenSigStartValue" SG_ 208 TrlrPrsnt_UB 1;
BA_ "GenSigStartValue" SG_ 208 TrlrSrvReq_UB 1;
BA_ "GenSigStartValue" SG_ 208 TwbrWarnSts_UB 1;
VAL_ 16 ChdLockgProtnStsAtPassRe 0 "OnOffSafe1_OnOffSafeInvld1" 1 "OnOffSafe1_OnOffSafeOn" 2 "OnOffSafe1_OnOffSafeOff" 3 "OnOffSafe1_OnOffSafeInvld2" ;
VAL_ 16 ChdWinProtnStsAtPassRe 0 "OnOff1_Off" 1 "OnOff1_On" ;
VAL_ 16 CurtReReqFromRe 0 "Boolean_FALSE" 1 "Boolean_TRUE" ;
VAL_ 16 DoorPassLockReSts 0 "LockSts2_LockStsUkwn" 1 "LockSts2_Unlckd" 2 "LockSts2_Lockd" 3 "LockSts2_SafeLockd" ;
VAL_ 16 DoorPassLockSts 0 "LockSts2_LockStsUkwn" 1 "LockSts2_Unlckd" 2 "LockSts2_Lockd" 3 "LockSts2_SafeLockd" ;
VAL_ 16 DoorPassSwtIntrLockgReq 0 "LockgCenReq2_Idle" 1 "LockgCenReq2_Unlck" 2 "LockgCenReq2_Lock" ;
VAL_ 16 DoorPassSwtLockgReSts 0 "PsdNotPsd1_NotPsd" 1 "PsdNotPsd1_Psd" ;
VAL_ 16 LcmaLedStsPassSide 0 "OkNotOk1_Ok" 1 "OkNotOk1_NotOk" ;
VAL_ 16 MirrAtPassInMovmt 0 "Boolean_FALSE" 1 "Boolean_TRUE" ;
VAL_ 16 MirrDwnStsAtPass 0 "MirrDwnStsTyp_MirrTiltUndefd" 1 "MirrDwnStsTyp_MirrUpPosn" 2 "MirrDwnStsTyp_MirrTiltPosn" 3 "MirrDwnStsTyp_MirrMovgToUpPosn" 4 "MirrDwnStsTyp_MirrMovgToTiltPosn" ;
VAL_ 16 MirrFoldStsAtPass 0 "MirrFoldStsTyp_MirrFoldPosnUndefd" 1 "MirrFoldStsTyp_MirrNotFoldPosn" 2 "MirrFoldStsTyp_MirrFoldPosn" 3 "MirrFoldStsTyp_MirrMovgToNotFold" 4 "MirrFoldStsTyp_MirrMovgToFold" ;
VAL_ 16 PassMemBtnPsdMemBtn1 0 "Boolean_FALSE" 1 "Boolean_TRUE" ;
VAL_ 16 PassMemBtnPsdMemBtn2 0 "Boolean_FALSE" 1 "Boolean_TRUE" ;
VAL_ 16 PassMemBtnPsdMemBtn3 0 "Boolean_FALSE" 1 "Boolean_TRUE" ;
VAL_ 16 PassMemBtnPsdMemButM 0 "Boolean_FALSE" 1 "Boolean_TRUE" ;
VAL_ 16 SunRoofAndCurtReqFromReSunCurtRo 0 "SunCurtRoofReqFromRe2_Idle" 1 "SunCurtRoofReqFromRe2_UpMan" 2 "SunCurtRoofReqFromRe2_UpAut" 3 "SunCurtRoofReqFromRe2_DwnMan" 4 "SunCurtRoofReqFromRe2_DwnAut" 5 "SunCurtRoofReqFromRe2_NotDefd" ;
VAL_ 16 SunRoofAndCurtReqFromReSunRoofRe 0 "SunRoofReqFromRe2_Idle" 1 "SunRoofReqFromRe2_UpMan" 2 "SunRoofReqFromRe2_UpAut" 3 "SunRoofReqFromRe2_DwnMan" 4 "SunRoofReqFromRe2_DwnAut" 5 "SunRoofReqFromRe2_NotDefd" ;
VAL_ 16 WinAndCurtSwtReqReLeFromRe 0 "WinPosnReq_Idle" 1 "WinPosnReq_UpMan" 2 "WinPosnReq_UpAut" 3 "WinPosnReq_DwnMan" 4 "WinPosnReq_DwnAut" 5 "WinPosnReq_NotDefd" ;
VAL_ 16 WinPosnStsRePass 0 "WinAndRoofAndCurtPosnTyp_PosnUkwn" 1 "WinAndRoofAndCurtPosnTyp_ClsFull" 2 "WinAndRoofAndCurtPosnTyp_PercOpen4" 3 "WinAndRoofAndCurtPosnTyp_PercOpen8" 4 "WinAndRoofAndCurtPosnTyp_PercOpen12" 5 "WinAndRoofAndCurtPosnTyp_PercOpen16" 6 "WinAndRoofAndCurtPosnTyp_PercOpen20" 7 "WinAndRoofAndCurtPosnTyp_PercOpen24" 8 "WinAndRoofAndCurtPosnTyp_PercOpen28" 9 "WinAndRoofAndCurtPosnTyp_PercOpen32" 10 "WinAndRoofAndCurtPosnTyp_PercOpen36" 11 "WinAndRoofAndCurtPosnTyp_PercOpen40" 12 "WinAndRoofAndCurtPosnTyp_PercOpen44" 13 "WinAndRoofAndCurtPosnTyp_PercOpen48" 14 "WinAndRoofAndCurtPosnTyp_PercOpen52" 15 "WinAndRoofAndCurtPosnTyp_PercOpen56" 16 "WinAndRoofAndCurtPosnTyp_PercOpen60" 17 "WinAndRoofAndCurtPosnTyp_PercOpen64" 18 "WinAndRoofAndCurtPosnTyp_PercOpen68" 19 "WinAndRoofAndCurtPosnTyp_PercOpen72" 20 "WinAndRoofAndCurtPosnTyp_PercOpen76" 21 "WinAndRoofAndCurtPosnTyp_PercOpen80" 22 "WinAndRoofAndCurtPosnTyp_PercOpen84" 23 "WinAndRoofAndCurtPosnTyp_PercOpen88" 24 "WinAndRoofAndCurtPosnTyp_PercOpen92" 25 "WinAndRoofAndCurtPosnTyp_PercOpen96" 26 "WinAndRoofAndCurtPosnTyp_OpenFull" 27 "WinAndRoofAndCurtPosnTyp_Resd1" 28 "WinAndRoofAndCurtPosnTyp_Resd2" 29 "WinAndRoofAndCurtPosnTyp_Resd3" 30 "WinAndRoofAndCurtPosnTyp_Resd4" 31 "WinAndRoofAndCurtPosnTyp_Movg" ;
VAL_ 352 AmbTQlyAtPassSide 0 "GenQf1_UndefindDataAccur" 1 "GenQf1_TmpUndefdData" 2 "GenQf1_DataAccurNotWithinSpcn" 3 "GenQf1_AccurData" ;
VAL_ 352 CrashUnlckFailrStsAtPass 0 "OnOffSafe1_OnOffSafeInvld1" 1 "OnOffSafe1_OnOffSafeOn" 2 "OnOffSafe1_OnOffSafeOff" 3 "OnOffSafe1_OnOffSafeInvld2" ;
VAL_ 352 CrashUnlckFailrStsAtPassRe 0 "OnOffSafe1_OnOffSafeInvld1" 1 "OnOffSafe1_OnOffSafeOn" 2 "OnOffSafe1_OnOffSafeOff" 3 "OnOffSafe1_OnOffSafeInvld2" ;
VAL_ 352 DoorPassReStsOfSeatSwtActrIncSts 0 "SwtVertSts1_Idle" 1 "SwtVertSts1_Up" 2 "SwtVertSts1_Dwn" ;
VAL_ 352 DoorPassReStsOfSeatSwtActrSldSts 0 "SwtHozlSts1_Idle" 1 "SwtHozlSts1_Fwd" 2 "SwtHozlSts1_Backw" ;
VAL_ 352 FltOfPuddleLiPass 0 "DevErrSts2_NoFlt" 1 "DevErrSts2_Flt" ;
VAL_ 352 LiPassFltIndcrTurn 0 "DevErrSts2_NoFlt" 1 "DevErrSts2_Flt" ;
VAL_ 352 MirrDefrstAtPassSts 0 "OnOff1_Off" 1 "OnOff1_On" ;
VAL_ 352 WinPosnStsPass 0 "WinAndRoofAndCurtPosnTyp_PosnUkwn" 1 "WinAndRoofAndCurtPosnTyp_ClsFull" 2 "WinAndRoofAndCurtPosnTyp_PercOpen4" 3 "WinAndRoofAndCurtPosnTyp_PercOpen8" 4 "WinAndRoofAndCurtPosnTyp_PercOpen12" 5 "WinAndRoofAndCurtPosnTyp_PercOpen16" 6 "WinAndRoofAndCurtPosnTyp_PercOpen20" 7 "WinAndRoofAndCurtPosnTyp_PercOpen24" 8 "WinAndRoofAndCurtPosnTyp_PercOpen28" 9 "WinAndRoofAndCurtPosnTyp_PercOpen32" 10 "WinAndRoofAndCurtPosnTyp_PercOpen36" 11 "WinAndRoofAndCurtPosnTyp_PercOpen40" 12 "WinAndRoofAndCurtPosnTyp_PercOpen44" 13 "WinAndRoofAndCurtPosnTyp_PercOpen48" 14 "WinAndRoofAndCurtPosnTyp_PercOpen52" 15 "WinAndRoofAndCurtPosnTyp_PercOpen56" 16 "WinAndRoofAndCurtPosnTyp_PercOpen60" 17 "WinAndRoofAndCurtPosnTyp_PercOpen64" 18 "WinAndRoofAndCurtPosnTyp_PercOpen68" 19 "WinAndRoofAndCurtPosnTyp_PercOpen72" 20 "WinAndRoofAndCurtPosnTyp_PercOpen76" 21 "WinAndRoofAndCurtPosnTyp_PercOpen80" 22 "WinAndRoofAndCurtPosnTyp_PercOpen84" 23 "WinAndRoofAndCurtPosnTyp_PercOpen88" 24 "WinAndRoofAndCurtPosnTyp_PercOpen92" 25 "WinAndRoofAndCurtPosnTyp_PercOpen96" 26 "WinAndRoofAndCurtPosnTyp_OpenFull" 27 "WinAndRoofAndCurtPosnTyp_Resd1" 28 "WinAndRoofAndCurtPosnTyp_Resd2" 29 "WinAndRoofAndCurtPosnTyp_Resd3" 30 "WinAndRoofAndCurtPosnTyp_Resd4" 31 "WinAndRoofAndCurtPosnTyp_Movg" ;
VAL_ 416 BodyMissComPrmntFromBoot 0 "Boolean_FALSE" 1 "Boolean_TRUE" ;
VAL_ 416 CurtPosnReSts 0 "CurtPosnReStsTyp_PosnUkwn" 1 "CurtPosnReStsTyp_ClsFull" 2 "CurtPosnReStsTyp_PercOpen25" 3 "CurtPosnReStsTyp_PercOpen50" 4 "CurtPosnReStsTyp_PercOpen75" 5 "CurtPosnReStsTyp_OpenFull" 6 "CurtPosnReStsTyp_Movg" 7 "CurtPosnReStsTyp_Resd1" ;
VAL_ 149 TrOpenerSts 0 "TrOpenerSts1_Ukwn" 1 "TrOpenerSts1_FullClsd" 2 "TrOpenerSts1_MovgUp" 3 "TrOpenerSts1_MovgUpBrkg" 4 "TrOpenerSts1_StopDurgOpen" 5 "TrOpenerSts1_FullOpend" 6 "TrOpenerSts1_MovgDwn" 7 "TrOpenerSts1_MovgDwnBrkg" 8 "TrOpenerSts1_StopDurgCls" 9 "TrOpenerSts1_HalfClsd" ;
VAL_ 144 DrvrCtrlOfPassSeatFrntSts 0 "ActvnAvl1_NotAvl" 1 "ActvnAvl1_Avl" 2 "ActvnAvl1_Deactvd" 3 "ActvnAvl1_Actvd" ;
VAL_ 144 DrvrMassgRunng 0 "OnOff1_Off" 1 "OnOff1_On" ;
VAL_ 144 DrvrSeatActvSpplFct 0 "SeatActvSpplFct1_NotAvl" 1 "SeatActvSpplFct1_LumExtnAndLumHei" 2 "SeatActvSpplFct1_BackBlster" 3 "SeatActvSpplFct1_CushExtn" 4 "SeatActvSpplFct1_HdrestHeiAndHdrestTilt" 5 "SeatActvSpplFct1_MassgFct" ;
VAL_ 144 DrvrSeatBtnPsd 0 "Boolean_FALSE" 1 "Boolean_TRUE" ;
VAL_ 144 DrvrSeatInAutMovmt 0 "Boolean_FALSE" 1 "Boolean_TRUE" ;
VAL_ 144 DrvrSeatMassgFctMassgInten 0 "MassgIntenLvl_IntenLo" 1 "MassgIntenLvl_IntenNorm" 2 "MassgIntenLvl_IntenHi" ;
VAL_ 144 DrvrSeatMassgFctMassgProg 0 "MassgProgTyp_Prog1" 1 "MassgProgTyp_Prog2" 2 "MassgProgTyp_Prog3" 3 "MassgProgTyp_Prog4" 4 "MassgProgTyp_Prog5" ;
VAL_ 144 DrvrSeatMassgFctMassgSpdLvl 0 "MassgIntenLvl_IntenLo" 1 "MassgIntenLvl_IntenNorm" 2 "MassgIntenLvl_IntenHi" ;
VAL_ 144 DrvrSeatMassgFctOnOff 0 "OnOff1_Off" 1 "OnOff1_On" ;
VAL_ 144 DrvrSeatSwtAdjmtOfSpplFctHozlSts 0 "SwtHozlSts1_Idle" 1 "SwtHozlSts1_Fwd" 2 "SwtHozlSts1_Backw" ;
VAL_ 144 DrvrSeatSwtAdjmtOfSpplFctVertSts 0 "SwtVertSts1_Idle" 1 "SwtVertSts1_Up" 2 "SwtVertSts1_Dwn" ;
VAL_ 144 DrvrSeatSwtHeiFrntSts 0 "SwtVertSts1_Idle" 1 "SwtVertSts1_Up" 2 "SwtVertSts1_Dwn" ;
VAL_ 144 DrvrSeatSwtHeiSts 0 "SwtVertSts1_Idle" 1 "SwtVertSts1_Up" 2 "SwtVertSts1_Dwn" ;
VAL_ 144 DrvrSeatSwtInclSts 0 "SwtHozlSts1_Idle" 1 "SwtHozlSts1_Fwd" 2 "SwtHozlSts1_Backw" ;
VAL_ 144 DrvrSeatSwtSelnOfSpplFctSts 0 "SwtVertSts1_Idle" 1 "SwtVertSts1_Up" 2 "SwtVertSts1_Dwn" ;
VAL_ 144 DrvrSeatSwtSldSts 0 "SwtHozlSts1_Idle" 1 "SwtHozlSts1_Fwd" 2 "SwtHozlSts1_Backw" ;
VAL_ 144 SeatBackUnlckdThrdLe 0 "Boolean_FALSE" 1 "Boolean_TRUE" ;
VAL_ 144 SeatBackUnlckdThrdRi 0 "Boolean_FALSE" 1 "Boolean_TRUE" ;
VAL_ 144 SeatBlkdLe 0 "Boolean_FALSE" 1 "Boolean_TRUE" ;
VAL_ 144 SeatBlkdRi 0 "Boolean_FALSE" 1 "Boolean_TRUE" ;
VAL_ 144 SeatFoldFctStsThrdGlb 0 "Boolean_FALSE" 1 "Boolean_TRUE" ;
VAL_ 160 PassMassgRunng 0 "OnOff1_Off" 1 "OnOff1_On" ;
VAL_ 160 PassSeatActvSpplFct 0 "SeatActvSpplFct1_NotAvl" 1 "SeatActvSpplFct1_LumExtnAndLumHei" 2 "SeatActvSpplFct1_BackBlster" 3 "SeatActvSpplFct1_CushExtn" 4 "SeatActvSpplFct1_HdrestHeiAndHdrestTilt" 5 "SeatActvSpplFct1_MassgFct" ;
VAL_ 160 PassSeatBtnPsd 0 "Boolean_FALSE" 1 "Boolean_TRUE" ;
VAL_ 160 PassSeatInAutMovmt 0 "Boolean_FALSE" 1 "Boolean_TRUE" ;
VAL_ 160 PassSeatMassgFctMassgInten 0 "MassgIntenLvl_IntenLo" 1 "MassgIntenLvl_IntenNorm" 2 "MassgIntenLvl_IntenHi" ;
VAL_ 160 PassSeatMassgFctMassgProg 0 "MassgProgTyp_Prog1" 1 "MassgProgTyp_Prog2" 2 "MassgProgTyp_Prog3" 3 "MassgProgTyp_Prog4" 4 "MassgProgTyp_Prog5" ;
VAL_ 160 PassSeatMassgFctMassgSpdLvl 0 "MassgIntenLvl_IntenLo" 1 "MassgIntenLvl_IntenNorm" 2 "MassgIntenLvl_IntenHi" ;
VAL_ 160 PassSeatMassgFctOnOff 0 "OnOff1_Off" 1 "OnOff1_On" ;
VAL_ 165 PassSeatSwtSts2PassSeatSwtAdjmtO 0 "SwtHozlSts1_Idle" 1 "SwtHozlSts1_Fwd" 2 "SwtHozlSts1_Backw" ;
VAL_ 165 PassSeatSwtSts2PassSeatSwtA_0000 0 "SwtVertSts1_Idle" 1 "SwtVertSts1_Up" 2 "SwtVertSts1_Dwn" ;
VAL_ 165 PassSeatSwtSts2PassSeatSwtHeiFrn 0 "SwtVertSts1_Idle" 1 "SwtVertSts1_Up" 2 "SwtVertSts1_Dwn" ;
VAL_ 165 PassSeatSwtSts2PassSeatSwtHeiSts 0 "SwtVertSts1_Idle" 1 "SwtVertSts1_Up" 2 "SwtVertSts1_Dwn" ;
VAL_ 165 PassSeatSwtSts2PassSeatSwtInclSt 0 "SwtHozlSts1_Idle" 1 "SwtHozlSts1_Fwd" 2 "SwtHozlSts1_Backw" ;
VAL_ 165 PassSeatSwtSts2PassSeatSwtSelnOf 0 "SwtVertSts1_Idle" 1 "SwtVertSts1_Up" 2 "SwtVertSts1_Dwn" ;
VAL_ 165 PassSeatSwtSts2PassSeatSwtSldSts 0 "SwtHozlSts1_Idle" 1 "SwtHozlSts1_Fwd" 2 "SwtHozlSts1_Backw" ;
VAL_ 565 ImobVehRemReqCmd 0 "ImobVehRemReqCmd_ImobRemReqIdle" 1 "ImobVehRemReqCmd_NoImobnRemReq" 2 "ImobVehRemReqCmd_ImobnRemReq" 3 "ImobVehRemReqCmd_SpdLimRemReq" 4 "ImobVehRemReqCmd_ImobRemChkReq" 5 "ImobVehRemReqCmd_ImobRemStsReq" ;
VAL_ 192 CarFindrHornLiReqFromTelm 0 "CarFindrHornLiReqFromTelm_NoReq" 1 "CarFindrHornLiReqFromTelm_HornReq" 2 "CarFindrHornLiReqFromTelm_LiReq" 3 "CarFindrHornLiReqFromTelm_HornLiReq" ;
VAL_ 192 ClimaRqrd1 0 "OnOffNoReq_NoReq" 1 "OnOffNoReq_On" 2 "OnOffNoReq_Off" ;
VAL_ 192 EmgyAsscSts 0 "AsscSts_Idle" 1 "AsscSts_AsscDataTrfInin" 2 "AsscSts_AsscDataTrf" 3 "AsscSts_AsscReqActv" 4 "AsscSts_AsscReqNotAprvd" ;
VAL_ 192 ErsCmdRecErsCmd 0 "ErsCmd_ErsCmdNotSet" 1 "ErsCmd_ErsCmdOn" 2 "ErsCmd_ErsCmdOff" ;
VAL_ 192 ErsCmdRecErsLeftFrontSeatHeat 0 "OffAut_Off" 1 "OffAut_Aut" ;
VAL_ 192 ErsCmdRecErsRightFrontSeatHeat 0 "OffAut_Off" 1 "OffAut_Aut" ;
VAL_ 192 ErsCmdRecErsSteeringWheelHeat 0 "OffAut_Off" 1 "OffAut_Aut" ;
VAL_ 192 NetTelmActvtPrio 0 "PrioHighNormal_PrioNormal" 1 "PrioHighNormal_PrioHigh" ;
VAL_ 192 RoadAsscSts 0 "AsscSts_Idle" 1 "AsscSts_AsscDataTrfInin" 2 "AsscSts_AsscDataTrf" 3 "AsscSts_AsscReqActv" 4 "AsscSts_AsscReqNotAprvd" ;
VAL_ 192 SeatHeatDurgClimaEnadFromTelm 0 "SeatHeatDurgClimaEnad_SeatHeatOff" 1 "SeatHeatDurgClimaEnad_SeatDrvOn" 2 "SeatHeatDurgClimaEnad_SeatPassOn" 3 "SeatHeatDurgClimaEnad_SeatDrvrAndPass" ;
VAL_ 192 SteerWhlHeatgDurgClimaEnadFromTe 0 "OnOff1_Off" 1 "OnOff1_On" ;
VAL_ 192 TelmFctReq 0 "Boolean_FALSE" 1 "Boolean_TRUE" ;
VAL_ 192 TelmLockgCenReq 0 "TelmLockgCenReq2_TelmNoReq" 1 "TelmLockgCenReq2_TelmLock" 2 "TelmLockgCenReq2_TelmUnlck" 3 "TelmLockgCenReq2_TelmUnlckByTrSwtEna" ;
VAL_ 192 TelmSts 0 "TelmSts_NoErr" 1 "TelmSts_TelmErr" 2 "TelmSts_TelmDi" 3 "TelmSts_TelmEnd" ;
VAL_ 570 ClngRqrdFromTelm 0 "OnOffNoReq_NoReq" 1 "OnOffNoReq_On" 2 "OnOffNoReq_Off" ;
VAL_ 570 TelmToSecuAlrmMgrIniSecuAlrmMagr 0 "AuthentIninMsgTyp_NoMsg" 1 "AuthentIninMsgTyp_AuthentIninReq" 2 "AuthentIninMsgTyp_AuthentIninResp" 3 "AuthentIninMsgTyp_AuthentIninAck" ;
VAL_ 293 CryptoTelmLockgCenReqReqTyp 0 "TelmLockgCenReq2_TelmNoReq" 1 "TelmLockgCenReq2_TelmLock" 2 "TelmLockgCenReq2_TelmUnlck" 3 "TelmLockgCenReq2_TelmUnlckByTrSwtEna" ;
VAL_ 421 TelmChrgnTmrActvd 0 "Boolean_FALSE" 1 "Boolean_TRUE" ;
VAL_ 208 TrlrFogLiSts 0 "OnOff2_On" 1 "OnOff2_Off" ;
VAL_ 208 TrlrIndcrLeSts 0 "DevErrSts2_NoFlt" 1 "DevErrSts2_Flt" ;
VAL_ 208 TrlrIndcrRiSts 0 "DevErrSts2_NoFlt" 1 "DevErrSts2_Flt" ;
VAL_ 208 TrlrLampActvtChk 0 "TrlrLampChkSts1_TrlrLampChkNotAvl" 1 "TrlrLampChkSts1_TrlrLampChkAvl" ;
VAL_ 208 TrlrLampChkSts 0 "TrlrLampChkSts2_Idle" 1 "TrlrLampChkSts2_TrlrLampChkStrtd" 2 "TrlrLampChkSts2_TrlrLampChkCmpl" 3 "TrlrLampChkSts2_CnclOper" 4 "TrlrLampChkSts2_TrlrLampEngOffReqd" 5 "TrlrLampChkSts2_Resd1" 6 "TrlrLampChkSts2_Resd2" 7 "TrlrLampChkSts2_Resd3" ;
VAL_ 208 TrlrLiSts 0 "LampFailrSts1_LampNoFailr" 1 "LampFailrSts1_LampIndcrTurnRiFailr" 2 "LampFailrSts1_LampIndcrTurnLeFailr" 3 "LampFailrSts1_LampIndcrTurnLeAndRiFailr" 4 "LampFailrSts1_BrkLampFailr" 5 "LampFailrSts1_BrkLampAndIndcrTurnRiFailr" 6 "LampFailrSts1_BrkLampAndIndcrTurnLeFailr" 7 "LampFailrSts1_BrkAndIndcrTurnAllFailr" ;
VAL_ 208 TrlrPrmntPwrActv 0 "YesNo1_Yes" 1 "YesNo1_No" ;
VAL_ 208 TrlrPrsnt 0 "TrlrPrsntSts_TrlrNotPrsnt" 1 "TrlrPrsntSts_TrlrPrsnt" ;
VAL_ 208 TrlrSrvReq 0 "DevErrSts2_NoFlt" 1 "DevErrSts2_Flt" ;
VAL_ 208 TwbrWarnSts 0 "DevErrSts2_NoFlt" 1 "DevErrSts2_Flt" ;
SIG_GROUP_ 1442 DevReqToPassDoorRe 1 : DevReqToPassDoorReByte0 DevReqToPassDoorReByte1 DevReqToPassDoorReByte2 DevReqToPassDoorReByte3 DevReqToPassDoorReByte4 DevReqToPassDoorReByte5 DevReqToPassDoorReByte6 DevReqToPassDoorReByte7;
SIG_GROUP_ 1473 ETCBodyDevReqToPassSeat 1 : ETCBodyDevReqToPassSeatByte0 ETCBodyDevReqToPassSeatByte1 ETCBodyDevReqToPassSeatByte2 ETCBodyDevReqToPassSeatByte3 ETCBodyDevReqToPassSeatByte4 ETCBodyDevReqToPassSeatByte5 ETCBodyDevReqToPassSeatByte6 ETCBodyDevReqToPassSeatByte7;
SIG_GROUP_ 1422 DevDataForPrkgAssi1 1 : DevDataForPrkgAssi1Byte0 DevDataForPrkgAssi1Byte1 DevDataForPrkgAssi1Byte2 DevDataForPrkgAssi1Byte3 DevDataForPrkgAssi1Byte4 DevDataForPrkgAssi1Byte5 DevDataForPrkgAssi1Byte6 DevDataForPrkgAssi1Byte7;
SIG_GROUP_ 1420 DevDataForPrkgAssi2 1 : DevDataForPrkgAssi2Byte0 DevDataForPrkgAssi2Byte1 DevDataForPrkgAssi2Byte2 DevDataForPrkgAssi2Byte3 DevDataForPrkgAssi2Byte4 DevDataForPrkgAssi2Byte5 DevDataForPrkgAssi2Byte6 DevDataForPrkgAssi2Byte7;
SIG_GROUP_ 1447 DevDataForPrkgAssi3 1 : DevDataForPrkgAssi3Byte0 DevDataForPrkgAssi3Byte1 DevDataForPrkgAssi3Byte2 DevDataForPrkgAssi3Byte3 DevDataForPrkgAssi3Byte4 DevDataForPrkgAssi3Byte5 DevDataForPrkgAssi3Byte6 DevDataForPrkgAssi3Byte7;
SIG_GROUP_ 1421 DevDataForPrkgAssi4 1 : DevDataForPrkgAssi4Byte0 DevDataForPrkgAssi4Byte1 DevDataForPrkgAssi4Byte2 DevDataForPrkgAssi4Byte3 DevDataForPrkgAssi4Byte4 DevDataForPrkgAssi4Byte5 DevDataForPrkgAssi4Byte6 DevDataForPrkgAssi4Byte7;
SIG_GROUP_ 1423 DevDataForPrkgAssi5 1 : DevDataForPrkgAssi5Byte0 DevDataForPrkgAssi5Byte1 DevDataForPrkgAssi5Byte2 DevDataForPrkgAssi5Byte3 DevDataForPrkgAssi5Byte4 DevDataForPrkgAssi5Byte5 DevDataForPrkgAssi5Byte6 DevDataForPrkgAssi5Byte7;
SIG_GROUP_ 1439 DevDataForPrkgAssi6 1 : DevDataForPrkgAssi6Byte0 DevDataForPrkgAssi6Byte1 DevDataForPrkgAssi6Byte2 DevDataForPrkgAssi6Byte3 DevDataForPrkgAssi6Byte4 DevDataForPrkgAssi6Byte5 DevDataForPrkgAssi6Byte6 DevDataForPrkgAssi6Byte7;
SIG_GROUP_ 1445 DevDataForPrkgAssi7 1 : DevDataForPrkgAssi7Byte0 DevDataForPrkgAssi7Byte1 DevDataForPrkgAssi7Byte2 DevDataForPrkgAssi7Byte3 DevDataForPrkgAssi7Byte4 DevDataForPrkgAssi7Byte5 DevDataForPrkgAssi7Byte6 DevDataForPrkgAssi7Byte7;
SIG_GROUP_ 1444 DevDataForPrkgAssi8 1 : DevDataForPrkgAssi8Byte0 DevDataForPrkgAssi8Byte1 DevDataForPrkgAssi8Byte2 DevDataForPrkgAssi8Byte3 DevDataForPrkgAssi8Byte4 DevDataForPrkgAssi8Byte5 DevDataForPrkgAssi8Byte6 DevDataForPrkgAssi8Byte7;
SIG_GROUP_ 1419 DevDataForPrkgAssi9 1 : DevDataForPrkgAssi9Byte0 DevDataForPrkgAssi9Byte1 DevDataForPrkgAssi9Byte2 DevDataForPrkgAssi9Byte3 DevDataForPrkgAssi9Byte4 DevDataForPrkgAssi9Byte5 DevDataForPrkgAssi9Byte6 DevDataForPrkgAssi9Byte7;
SIG_GROUP_ 1418 DevDataForPrkgAssi10 1 : DevDataForPrkgAssi10Byte0 DevDataForPrkgAssi10Byte1 DevDataForPrkgAssi10Byte2 DevDataForPrkgAssi10Byte3 DevDataForPrkgAssi10Byte4 DevDataForPrkgAssi10Byte5 DevDataForPrkgAssi10Byte6 DevDataForPrkgAssi10Byte7;
SIG_GROUP_ 1446 DevDataForPrkgAssi11 1 : DevDataForPrkgAssi11Byte0 DevDataForPrkgAssi11Byte1 DevDataForPrkgAssi11Byte2 DevDataForPrkgAssi11Byte3 DevDataForPrkgAssi11Byte4 DevDataForPrkgAssi11Byte5 DevDataForPrkgAssi11Byte6 DevDataForPrkgAssi11Byte7;
SIG_GROUP_ 1437 DevDataForPrkgAssi12 1 : DevDataForPrkgAssi12Byte0 DevDataForPrkgAssi12Byte1 DevDataForPrkgAssi12Byte2 DevDataForPrkgAssi12Byte3 DevDataForPrkgAssi12Byte4 DevDataForPrkgAssi12Byte5 DevDataForPrkgAssi12Byte6 DevDataForPrkgAssi12Byte7;
SIG_GROUP_ 1438 DevDataForPrkgAssi13 1 : DevDataForPrkgAssi13Byte0 DevDataForPrkgAssi13Byte1 DevDataForPrkgAssi13Byte2 DevDataForPrkgAssi13Byte3 DevDataForPrkgAssi13Byte4 DevDataForPrkgAssi13Byte5 DevDataForPrkgAssi13Byte6 DevDataForPrkgAssi13Byte7;
SIG_GROUP_ 1448 DevDataForPrkgAssi14 1 : DevDataForPrkgAssi14Byte0 DevDataForPrkgAssi14Byte1 DevDataForPrkgAssi14Byte2 DevDataForPrkgAssi14Byte3 DevDataForPrkgAssi14Byte4 DevDataForPrkgAssi14Byte5 DevDataForPrkgAssi14Byte6 DevDataForPrkgAssi14Byte7;
SIG_GROUP_ 16 PassMemBtnPsd 1 : PassMemBtnPsdMemBtn1 PassMemBtnPsdMemBtn2 PassMemBtnPsdMemBtn3 PassMemBtnPsdMemButM;
SIG_GROUP_ 16 SunRoofAndCurtReqFromRe 1 : SunRoofAndCurtReqFromReSunCurtRo SunRoofAndCurtReqFromReSunRoofRe;
SIG_GROUP_ 352 AmbTRawAtPassSide 1 : AmbTQlyAtPassSide AmbTValAtPassSide;
SIG_GROUP_ 352 DoorPassReStsOfSeatSwt 1 : DoorPassReStsOfSeatSwtActrIncSts DoorPassReStsOfSeatSwtActrSldSts;
SIG_GROUP_ 298 CryptoDoorPassLockCmdInin 1 : CryptoDoorPassLockCmdIninCmdInin CryptoDoorPassLockCmdIninCm_0000 CryptoDoorPassLockCmdIninCm_0001;
SIG_GROUP_ 298 CryptoDoorPassLockReCmdInin 1 : CryptoDoorPassLockReCmdIninCmdIn CryptoDoorPassLockReCmdInin_0000 CryptoDoorPassLockReCmdInin_0001;
SIG_GROUP_ 1433 DevRespAtPassDoor 1 : DevRespAtPassDoorByte0 DevRespAtPassDoorByte1 DevRespAtPassDoorByte2 DevRespAtPassDoorByte3 DevRespAtPassDoorByte4 DevRespAtPassDoorByte5 DevRespAtPassDoorByte6 DevRespAtPassDoorByte7;
SIG_GROUP_ 1436 DevRespAtPassDoorRe 1 : DevRespAtPassDoorReByte0 DevRespAtPassDoorReByte1 DevRespAtPassDoorReByte2 DevRespAtPassDoorReByte3 DevRespAtPassDoorReByte4 DevRespAtPassDoorReByte5 DevRespAtPassDoorReByte6 DevRespAtPassDoorReByte7;
SIG_GROUP_ 1431 DevTx1AtPassDoor 1 : DevTx1AtPassDoorByte0 DevTx1AtPassDoorByte1 DevTx1AtPassDoorByte2 DevTx1AtPassDoorByte3 DevTx1AtPassDoorByte4 DevTx1AtPassDoorByte5 DevTx1AtPassDoorByte6 DevTx1AtPassDoorByte7;
SIG_GROUP_ 1434 DevTx1AtPassDoorRe 1 : DevTx1AtPassDoorReByte0 DevTx1AtPassDoorReByte1 DevTx1AtPassDoorReByte2 DevTx1AtPassDoorReByte3 DevTx1AtPassDoorReByte4 DevTx1AtPassDoorReByte5 DevTx1AtPassDoorReByte6 DevTx1AtPassDoorReByte7;
SIG_GROUP_ 1432 DevTx2AtPassDoor 1 : DevTx2AtPassDoorByte0 DevTx2AtPassDoorByte1 DevTx2AtPassDoorByte2 DevTx2AtPassDoorByte3 DevTx2AtPassDoorByte4 DevTx2AtPassDoorByte5 DevTx2AtPassDoorByte6 DevTx2AtPassDoorByte7;
SIG_GROUP_ 1435 DevTx2AtPassDoorRe 1 : DevTx2AtPassDoorReByte0 DevTx2AtPassDoorReByte1 DevTx2AtPassDoorReByte2 DevTx2AtPassDoorReByte3 DevTx2AtPassDoorReByte4 DevTx2AtPassDoorReByte5 DevTx2AtPassDoorReByte6 DevTx2AtPassDoorReByte7;
SIG_GROUP_ 1450 DevRespInDrvrSeat 1 : DevRespInDrvrSeatByte0 DevRespInDrvrSeatByte1 DevRespInDrvrSeatByte2 DevRespInDrvrSeatByte3 DevRespInDrvrSeatByte4 DevRespInDrvrSeatByte5 DevRespInDrvrSeatByte6 DevRespInDrvrSeatByte7;
SIG_GROUP_ 144 DrvrSeatMassgFct 1 : DrvrSeatMassgFctMassgInten DrvrSeatMassgFctMassgProg DrvrSeatMassgFctMassgSpdLvl DrvrSeatMassgFctOnOff;
SIG_GROUP_ 144 DrvrSeatSwtSts 1 : DrvrSeatSwtAdjmtOfSpplFctHozlSts DrvrSeatSwtAdjmtOfSpplFctVertSts DrvrSeatSwtHeiFrntSts DrvrSeatSwtHeiSts DrvrSeatSwtInclSts DrvrSeatSwtSelnOfSpplFctSts DrvrSeatSwtSldSts;
SIG_GROUP_ 144 SeatBackUnlckdThrd 1 : SeatBackUnlckdThrdLe SeatBackUnlckdThrdRi;
SIG_GROUP_ 144 SeatBlkdThrd 1 : SeatBlkdLe SeatBlkdRi;
SIG_GROUP_ 1504 DevRespInPassSeat 1 : DevRespInPassSeatByte0 DevRespInPassSeatByte1 DevRespInPassSeatByte2 DevRespInPassSeatByte3 DevRespInPassSeatByte4 DevRespInPassSeatByte5 DevRespInPassSeatByte6 DevRespInPassSeatByte7;
SIG_GROUP_ 160 PassSeatMassgFct 1 : PassSeatMassgFctMassgInten PassSeatMassgFctMassgProg PassSeatMassgFctMassgSpdLvl PassSeatMassgFctOnOff;
SIG_GROUP_ 165 PassSeatSwtSts2 1 : PassSeatSwtSts2PassSeatSwtAdjmtO PassSeatSwtSts2PassSeatSwtA_0000 PassSeatSwtSts2PassSeatSwtHeiFrn PassSeatSwtSts2PassSeatSwtHeiSts PassSeatSwtSts2PassSeatSwtInclSt PassSeatSwtSts2PassSeatSwtSelnOf PassSeatSwtSts2PassSeatSwtSldSts;
SIG_GROUP_ 565 ImobVehRemReqAndResp 1 : ImobVehDataRemReq0 ImobVehDataRemReq1 ImobVehDataRemReq2 ImobVehDataRemReq3 ImobVehDataRemReq4 ImobVehRemReqCmd ImobVehRemTmrOrSpdLim;
SIG_GROUP_ 192 ErsCmdRec 1 : ErsCmdRecErsCmd ErsCmdRecErsLeftFrontSeatHeat ErsCmdRecErsRightFrontSeatHeat ErsCmdRecErsRunTime ErsCmdRecErsSteeringWheelHeat;
SIG_GROUP_ 192 NetTelmActvt 1 : NetTelmActvtPrio NetTelmActvtResourceGroup;
SIG_GROUP_ 192 TelmLockgReq 1 : TelmLockgCenReq UInt4;
SIG_GROUP_ 560 UkwnCptRespFromTelm 1 : UkwnCptRespFromTelmByte0 UkwnCptRespFromTelmByte1 UkwnCptRespFromTelmByte2 UkwnCptRespFromTelmByte3 UkwnCptRespFromTelmByte4 UkwnCptRespFromTelmByte5 UkwnCptRespFromTelmByte6 UkwnCptRespFromTelmByte7;
SIG_GROUP_ 570 TelmToSecuAlrmMgrIni 1 : TelmToSecuAlrmMgrIniMsgAuthentCo TelmToSecuAlrmMgrIniMsgAuth_0000 TelmToSecuAlrmMgrIniSecuAlrmMagr TelmToSecuAlrmMgrIniSecuIniNrRnd TelmToSecuAlrmMgrIniSecuIni_0000 TelmToSecuAlrmMgrIniSecuIni_0001;
SIG_GROUP_ 293 CryptoTelmLockgCenReq 1 : CryptoTelmLockgCenReqAuthentCod CryptoTelmLockgCenReqCntr CryptoTelmLockgCenReqReqTyp CryptoTelmLockgCenReqTivld;
SIG_GROUP_ 1279 VFCVectorTEM 1 : VFCVectorTEMGrp1 VFCVectorTEMGrp2 VFCVectorTEMGrp3;
